VERSION ""

NS_ :

BS_:

BU_: TCM HCM IPMA_ADAS PSCM ABS_ESC TCCM TCM_DSL PCM_HEV PCM ECM_HEVDSL ECM_HEV ECM_Diesel ECM SIMA_DLCS BCMD_IPDB VDM CMR_DSMC SOBDMC_HPCM CHCM GWM _delete AWD_DLCM GENERIC TSTR

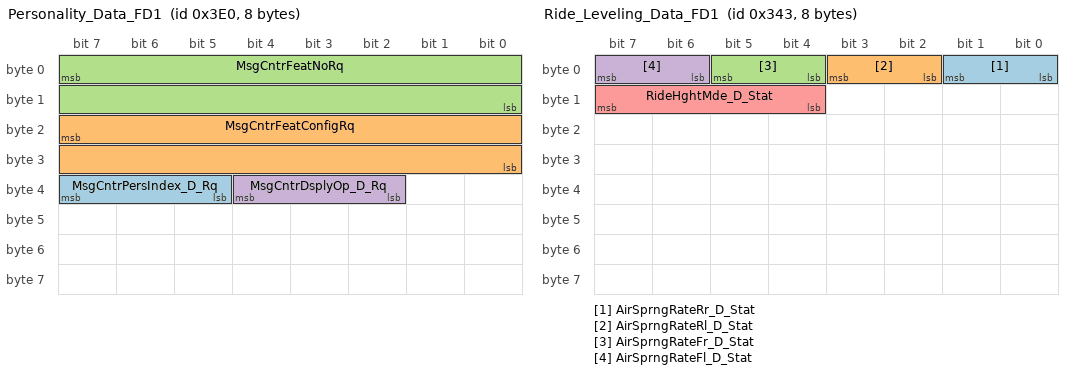
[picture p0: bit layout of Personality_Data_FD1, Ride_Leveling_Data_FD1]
BO_ 992 Personality_Data_FD1: 8 IPC
 SG_ MsgCntrPersIndex_D_Rq : 39|3@0+ (1,0) [0|7] "SED"  SOBDMC_HPCM,VDM,IPMA_ADAS,HCM
 SG_ MsgCntrFeatConfigRq : 23|16@0+ (1,0) [0|65535] "unitless"  SOBDMC_HPCM,HCM,VDM,IPMA_ADAS
 SG_ MsgCntrFeatNoRq : 7|16@0+ (1,0) [0|65535] "Number"  VDM,SOBDMC_HPCM,IPMA_ADAS,HCM
 SG_ MsgCntrDsplyOp_D_Rq : 36|3@0+ (1,0) [0|7] "SED"  SOBDMC_HPCM,HCM,VDM,IPMA_ADAS

BO_ 835 Ride_Leveling_Data_FD1: 8 SUMA_RLM
 SG_ AirSprngRateRr_D_Stat : 1|2@0+ (1,0) [0|3] "SED"  VDM,GENERIC
 SG_ AirSprngRateRl_D_Stat : 3|2@0+ (1,0) [0|3] "SED"  VDM,GENERIC
 SG_ AirSprngRateFr_D_Stat : 5|2@0+ (1,0) [0|3] "SED"  VDM,GENERIC
 SG_ AirSprngRateFl_D_Stat : 7|2@0+ (1,0) [0|3] "SED"  VDM,GENERIC
 SG_ RideHghtMde_D_Stat : 15|4@0+ (1,0) [0|15] "SED"  PSCM,GENERIC,VDM

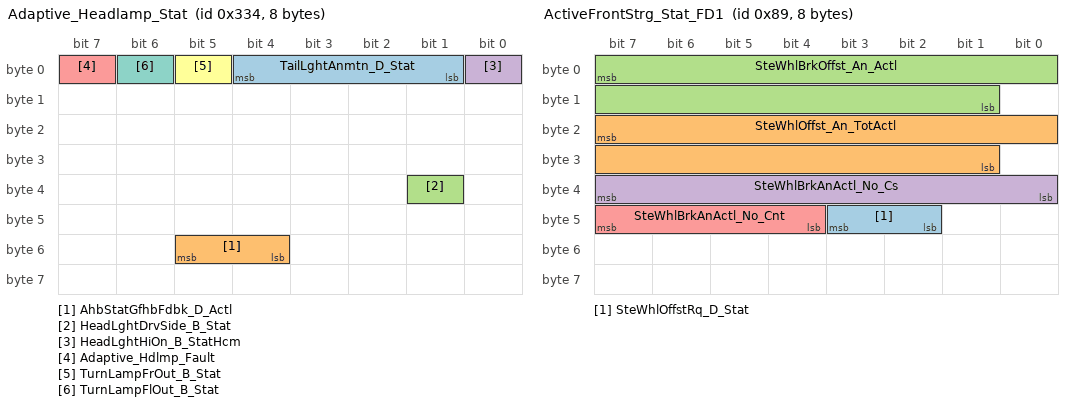
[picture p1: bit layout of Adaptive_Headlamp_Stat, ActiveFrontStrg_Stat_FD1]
BO_ 820 Adaptive_Headlamp_Stat: 8 GWM
 SG_ TailLghtAnmtn_D_Stat : 4|4@0+ (1,0) [0|15] "SED"  GWM
 SG_ AhbStatGfhbFdbk_D_Actl : 53|2@0+ (1,0) [0|3] "SED"  IPMA_ADAS
 SG_ HeadLghtDrvSide_B_Stat : 33|1@0+ (1,0) [0|1] "SED"  IPMA_ADAS
 SG_ HeadLghtHiOn_B_StatHcm : 0|1@0+ (1,0) [0|1] "SED"  GWM
 SG_ Adaptive_Hdlmp_Fault : 7|1@0+ (1,0) [0|1] "SED"  IPMA_ADAS,GWM
 SG_ TurnLampFrOut_B_Stat : 5|1@0+ (1,0) [0|1] "SED"  GWM
 SG_ TurnLampFlOut_B_Stat : 6|1@0+ (1,0) [0|1] "SED"  GWM

BO_ 817 Locking_Systems_2_FD1: 8 BCM
 SG_ ChildLckMde_B_Stat : 56|1@0+ (1,0) [0|1] "SED"  GENERIC
 SG_ VehLckInd_D_Rq : 58|2@0+ (1,0) [0|3] "SED"  GENERIC
 SG_ DrTgateOpen_B_Rq : 59|1@0+ (1,0) [0|1] "SED"  GENERIC
 SG_ DrTgateExtSwMde_B_Stat : 32|1@0+ (1,0) [0|1] "SED"  ECM,PCM
 SG_ Remote_Device_Feedback : 50|3@0+ (1,0) [0|7] "SED"  ECM,PCM
 SG_ Veh_Lock_Requestor : 55|5@0+ (1,0) [0|31] "SED"  ECM,PCM,ABS_ESC
 SG_ R_Pwr_Sliding_Dr_Rqst : 36|1@0+ (1,0) [0|1] "SED"  GENERIC
 SG_ Power_Liftgate_Rqst : 0|1@0+ (1,0) [0|1] "SED"  GENERIC
 SG_ Veh_Lock_EvNum : 47|8@0+ (1,0) [0|255] "unitless"  ECM,PCM,ABS_ESC
 SG_ Power_Decklid_Rqst : 1|1@0+ (1,0) [0|1] "SED"  GENERIC
 SG_ L_Pwr_Sliding_Dr_Rqst : 3|1@0+ (1,0) [0|1] "SED"  GENERIC
 SG_ Keyfob_Pad_Msg_Count : 15|8@0+ (1,0) [0|255] "Counts"  GENERIC
 SG_ Veh_Lock_Sub_Id : 63|4@0+ (1,0) [0|15] "SED"  ECM,PCM
 SG_ Veh_Lock_Status : 34|2@0+ (1,0) [0|3] "SED"  ECM,PCM,GENERIC,ABS_ESC,IPMA_ADAS,CMR_DSMC
 SG_ ChildLck_D_Dsply : 7|2@0+ (1,0) [0|3] "SED"  GENERIC
 SG_ WindowLockout_B_Stat : 35|1@0+ (1,0) [0|1] "SED"  GENERIC
 SG_ RollCodeUnlock : 23|16@0+ (1,0) [0|65535] "Unitless"  GENERIC
 SG_ Lockmsgtxt_D_Rq : 39|3@0+ (1,0) [0|7] "SED"  GENERIC
 SG_ FobComm_D_Stat : 5|2@0+ (1,0) [0|3] "SED"  ECM,PCM
 SG_ LockInhibit : 2|1@0+ (1,0) [0|1] "SED"  GENERIC

BO_ 137 ActiveFrontStrg_Stat_FD1: 8 GWM
 SG_ SteWhlOffstRq_D_Stat : 43|2@0+ (1,0) [0|3] "SED"  ABS_ESC
 SG_ SteWhlOffst_An_TotActl : 23|15@0+ (0.1,-1600) [-1600|1676.5] "degrees"  ABS_ESC
 SG_ SteWhlBrkOffst_An_Actl : 7|15@0+ (0.1,-1600) [-1600|1676.5] "degrees"  ABS_ESC,AWD_DLCM
 SG_ SteWhlBrkAnActl_No_Cs : 39|8@0+ (1,0) [0|255] "Unitless"  ABS_ESC
 SG_ SteWhlBrkAnActl_No_Cnt : 47|4@0+ (1,0) [0|15] "Unitless"  ABS_ESC

BO_ 129 Steering_Wheel_Data2_FD1: 8 SCCM
 SG_ SelDrvMdeSwtch4_D_Stat4 : 38|2@0+ (1,0) [0|3] "SED"  ABS_ESC
 SG_ EngExhMdeQuiet_B_RqDrv2 : 39|1@0+ (1,0) [0|1] "SED"  GENERIC
 SG_ SelDrvMdeSwtch_D_Stat4 : 21|2@0+ (1,0) [0|3] "SED"  ABS_ESC
 SG_ SteWhlSwtchView_B_Stat : 23|1@0+ (1,0) [0|1] "SED"  GENERIC
 SG_ SteWhlSwtchSet_B_Stat : 8|1@0+ (1,0) [0|1] "SED"  GENERIC
 SG_ SteWhlSwtchPhon_B_Stat : 9|1@0+ (1,0) [0|1] "SED"  GENERIC
 SG_ SteWhlSwtchNav_B_Stat : 10|1@0+ (1,0) [0|1] "SED"  GENERIC
 SG_ SteWhlSwtchMed_B_Stat : 11|1@0+ (1,0) [0|1] "SED"  GENERIC
 SG_ SteWhlSwtchIod_B_Stat : 12|1@0+ (1,0) [0|1] "SED"  GENERIC
 SG_ SteWhlSwtchHud_B_Stat : 13|1@0+ (1,0) [0|1] "SED"  GENERIC
 SG_ SteWhlSwtchBack_B_Stat : 14|1@0+ (1,0) [0|1] "SED"  GENERIC
 SG_ SteWhlSwtchMenu_B_Stat : 22|1@0+ (1,0) [0|1] "SED"  GENERIC
 SG_ SteEffortInc_B_RqDrv : 5|1@0+ (1,0) [0|1] "SED"  GENERIC
 SG_ SelDrvMdeInc_B_RqDrv : 6|1@0+ (1,0) [0|1] "SED"  GENERIC
 SG_ SelDrvMdeDec_B_RqDrv : 7|1@0+ (1,0) [0|1] "SED"  GENERIC
 SG_ SuspDampInc_B_RqDrv : 15|1@0+ (1,0) [0|1] "SED"  GENERIC
 SG_ SteWhlSwtchUp_B_Stat : 3|1@0+ (1,0) [0|1] "SED"  GENERIC
 SG_ SteWhlSwtchRght_B_Stat : 2|1@0+ (1,0) [0|1] "SED"  GENERIC
 SG_ SteWhlSwtchOk_B_Stat : 4|1@0+ (1,0) [0|1] "SED"  GENERIC
 SG_ SteWhlSwtchLeft_B_Stat : 1|1@0+ (1,0) [0|1] "SED"  GENERIC
 SG_ SteWhlSwtchDown_B_Stat : 0|1@0+ (1,0) [0|1] "SED"  GENERIC
 SG_ SteWhlSwtchHome_B_Stat : 19|1@0+ (1,0) [0|1] "SED"  GENERIC
 SG_ SteWhlSwtchInfo_B_Stat : 18|1@0+ (1,0) [0|1] "SED"  GENERIC
 SG_ PoliceAux4Swtch_B_Stat : 30|1@0+ (1,0) [0|1] "SED"  GENERIC
 SG_ PoliceAux3Swtch_B_Stat : 31|1@0+ (1,0) [0|1] "SED"  GENERIC
 SG_ PoliceAux2Swtch_B_Stat : 16|1@0+ (1,0) [0|1] "SED"  GENERIC
 SG_ PoliceAux1Swtch_B_Stat : 17|1@0+ (1,0) [0|1] "SED"  GENERIC
 SG_ SelDrvMdeSwtch3_D_Stat4 : 25|2@0+ (1,0) [0|3] "SED"  ABS_ESC
 SG_ SelDrvMdeSwtch2_D_Stat4 : 27|2@0+ (1,0) [0|3] "SED"  ABS_ESC
 SG_ SelDrvMdeSwtch1_D_Stat4 : 29|2@0+ (1,0) [0|3] "SED"  ABS_ESC

BO_ 854 Clmt_Button_Stat2_FD1: 8 HVAC_RCCM
 SG_ Dsp_RotAddrBtnEv_St : 63|4@0+ (1,0) [0|15] "SED"  GENERIC
 SG_ SelDrvMdeButtn_B_Stat : 55|1@0+ (1,0) [0|1] "SED"  GENERIC
 SG_ SteEffortButtn_B_Stat : 54|1@0+ (1,0) [0|1] "SED"  GENERIC
 SG_ SelDrvMdeSwtch_D_Stat2 : 51|2@0+ (1,0) [0|3] "SED"  GENERIC,ABS_ESC
 SG_ CC_Fr_Stat_User_Adj : 6|3@0+ (1,0) [0|7] "SED"  GENERIC
 SG_ EngExhMdeQuiet_B_RqDrv : 52|1@0+ (1,0) [0|1] "SED"  GENERIC
 SG_ LnchCtlSys_B_RqDrv : 53|1@0+ (1,0) [0|1] "SED"  GENERIC
 SG_ Front_Blower_Indicate : 13|4@0+ (1,0) [0|15] "SED"  GENERIC
 SG_ CC_Diagnostics_Active : 7|1@0+ (1,0) [0|1] "SED"  GENERIC
 SG_ RHS_Temp_Display_Digit3 : 3|2@0+ (1,0) [0|3] "SED"  GENERIC
 SG_ RHS_Temp_Display_Digit2 : 47|8@0+ (1,0) [0|255] "ASCII"  GENERIC
 SG_ RHS_Temp_Display_Digit1 : 39|8@0+ (1,0) [0|255] "ASCII"  GENERIC
 SG_ LHS_Temp_Display_Digit3 : 9|2@0+ (1,0) [0|3] "SED"  GENERIC
 SG_ LHS_Temp_Display_Digit2 : 31|8@0+ (1,0) [0|255] "ASCII"  GENERIC
 SG_ LHS_Temp_Display_Digit1 : 23|8@0+ (1,0) [0|255] "ASCII"  GENERIC
 SG_ EATC_RHS_Units : 15|2@0+ (1,0) [0|3] "SED"  GENERIC
 SG_ EATC_LHS_Units : 1|2@0+ (1,0) [0|3] "SED"  GENERIC
 SG_ LHS_Auto_Seat_Btn_Stt : 59|2@0+ (1,0) [0|3] "SED"  GENERIC
 SG_ RHS_Auto_Seat_Btn_Stt : 57|2@0+ (1,0) [0|3] "SED"  GENERIC

BO_ 549 IPC_Infotainment_FD1: 8 IPC
 SG_ SpeedChngChime_D_Rq2 : 13|2@0+ (1,0) [0|3] "SED"  IPMA_ADAS
 SG_ CCOI_PolicyClient_St2 : 45|4@0+ (1,0) [0|15] "SED"  GENERIC
 SG_ FactoryReset_Rq2 : 18|1@0+ (1,0) [0|1] "SED"  GENERIC
 SG_ TjaLcEnbl_D_DrvRq : 41|2@0+ (1,0) [0|3] "SED"  IPMA_ADAS
 SG_ BattTracLoThres_D_Rq2 : 52|3@0+ (1,0) [0|7] "SED"  SOBDMC_HPCM
 SG_ NavIod_D_Rq : 55|3@0+ (1,0) [0|7] "SED"  GENERIC
 SG_ Veh_V2_Dsply : 39|9@0+ (1,0) [0|511] "unitless"  GENERIC,IPMA_ADAS
 SG_ IPC_MyKeyVolLimit_St : 9|2@0+ (1,0) [0|3] "SED"  GENERIC
 SG_ HdcOn_B_Rq : 19|1@0+ (1,0) [0|1] "SED"  GENERIC,ABS_ESC
 SG_ IPC_Attn_Info_Audio : 4|3@0+ (1,0) [0|7] "SED"  GENERIC
 SG_ BeltminderAudioMute : 6|2@0+ (1,0) [0|3] "SED"  GENERIC
 SG_ Power_Up_Chime_Modules : 23|1@0+ (1,0) [0|1] "SED"  GENERIC
 SG_ Chime_Source : 15|2@0+ (1,0) [0|3] "SED"  GENERIC
 SG_ IPC_New_Attn_Event : 0|1@0+ (1,0) [0|1] "SED"  GENERIC
 SG_ WwaActv_B_Stat : 46|1@0+ (1,0) [0|1] "SED"  IPMA_ADAS
 SG_ MetricActv_B_Dsply : 7|1@0+ (1,0) [0|1] "SED"  GENERIC
 SG_ HudVertSzMnuOn_B_Rq : 21|1@0+ (1,0) [0|1] "SED"  GENERIC
 SG_ HudVertMnuOn_B_Rq : 11|1@0+ (1,0) [0|1] "SED"  GENERIC
 SG_ HudRotatMnuOn_B_Rq : 22|1@0+ (1,0) [0|1] "SED" Vector__XXX
 SG_ HudCntntMnuOn_B_Rq : 20|1@0+ (1,0) [0|1] "SED"  GENERIC
 SG_ HudBrightMnuOn_B_Rq : 1|1@0+ (1,0) [0|1] "SED"  GENERIC
 SG_ StrtInGearOk_D_Stat : 17|2@0+ (1,0) [0|3] "SED"  ECM_Diesel,ECM,PCM

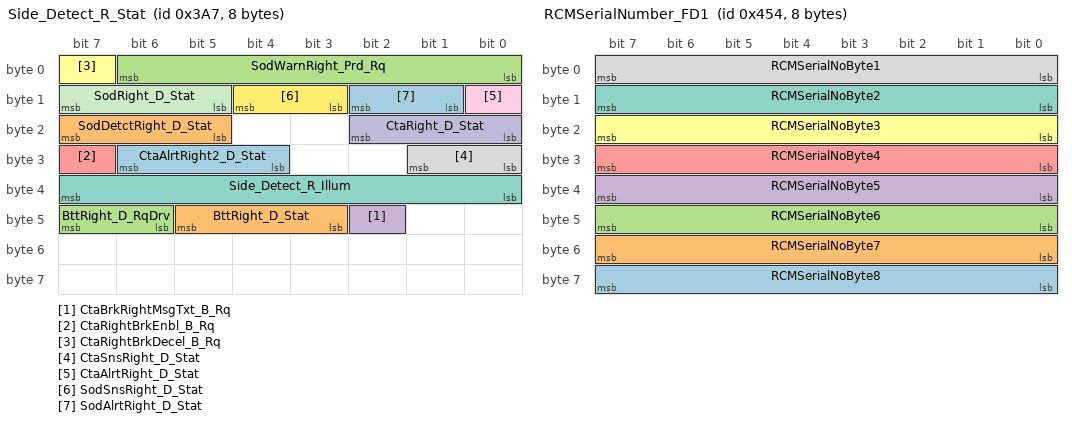
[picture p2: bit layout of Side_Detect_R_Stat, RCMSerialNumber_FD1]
BO_ 935 Side_Detect_R_Stat: 8 IPMA_ADAS
 SG_ CtaAlrtRight2_D_Stat : 30|3@0+ (1,0) [0|7] "SED"  GWM
 SG_ BttRight_D_Stat : 45|3@0+ (1,0) [0|7] "SED"  GWM
 SG_ BttRight_D_RqDrv : 47|2@0+ (1,0) [0|3] "SED"  GWM
 SG_ CtaBrkRightMsgTxt_B_Rq : 42|1@0+ (1,0) [0|1] "SED"  GWM
 SG_ CtaRightBrkEnbl_B_Rq : 31|1@0+ (1,0) [0|1] "SED"  GWM,ABS_ESC
 SG_ CtaRightBrkDecel_B_Rq : 7|1@0+ (1,0) [0|1] "SED"  GWM,ABS_ESC
 SG_ Side_Detect_R_Illum : 39|8@0+ (1,0) [0|255] "Percent"  GWM
 SG_ CtaSnsRight_D_Stat : 25|2@0+ (1,0) [0|3] "SED"  GWM
 SG_ CtaAlrtRight_D_Stat : 8|1@0+ (1,0) [0|1] "SED"  GWM
 SG_ CtaRight_D_Stat : 18|3@0+ (1,0) [0|7] "SED"  GWM
 SG_ SodRight_D_Stat : 15|3@0+ (1,0) [0|7] "SED"  GWM
 SG_ SodSnsRight_D_Stat : 12|2@0+ (1,0) [0|3] "SED"  GWM
 SG_ SodAlrtRight_D_Stat : 10|2@0+ (1,0) [0|3] "SED"  GWM
 SG_ SodDetctRight_D_Stat : 23|3@0+ (1,0) [0|7] "SED"  GWM
 SG_ SodWarnRight_Prd_Rq : 6|7@0+ (1,0) [0|127] "millisecond"  GWM

BO_ 1108 RCMSerialNumber_FD1: 8 RCM
 SG_ RCMSerialNoByte8 : 63|8@0+ (1,0) [0|253] "Unitless"  ABS_ESC
 SG_ RCMSerialNoByte7 : 55|8@0+ (1,0) [0|253] "Unitless"  ABS_ESC
 SG_ RCMSerialNoByte6 : 47|8@0+ (1,0) [0|253] "Unitless"  ABS_ESC
 SG_ RCMSerialNoByte5 : 39|8@0+ (1,0) [0|253] "Unitless"  ABS_ESC
 SG_ RCMSerialNoByte4 : 31|8@0+ (1,0) [0|253] "Unitless"  ABS_ESC
 SG_ RCMSerialNoByte3 : 23|8@0+ (1,0) [0|253] "Unitless"  ABS_ESC
 SG_ RCMSerialNoByte2 : 15|8@0+ (1,0) [0|253] "Unitless"  ABS_ESC
 SG_ RCMSerialNoByte1 : 7|8@0+ (1,0) [0|253] "Unitless"  ABS_ESC

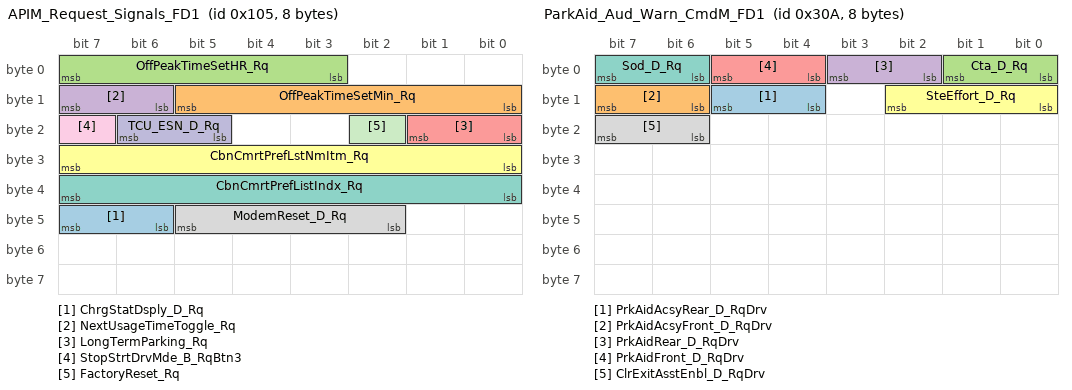
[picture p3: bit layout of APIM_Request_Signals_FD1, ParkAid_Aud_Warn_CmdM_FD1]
BO_ 261 APIM_Request_Signals_FD1: 8 ACM
 SG_ ChrgStatDsply_D_Rq : 47|2@0+ (1,0) [0|3] "SED"  GENERIC
 SG_ OffPeakTimeSetMin_Rq : 13|6@0+ (1,0) [0|63] "unitless"  GENERIC
 SG_ OffPeakTimeSetHR_Rq : 7|5@0+ (1,0) [0|31] "unitless"  GENERIC
 SG_ NextUsageTimeToggle_Rq : 15|2@0+ (1,0) [0|3] "SED"  GENERIC
 SG_ LongTermParking_Rq : 17|2@0+ (1,0) [0|3] "SED"  GENERIC
 SG_ CbnCmrtPrefLstNmItm_Rq : 31|8@0+ (1,0) [0|255] "unitless"  GENERIC
 SG_ CbnCmrtPrefListIndx_Rq : 39|8@0+ (1,0) [0|255] "unitless"  GENERIC
 SG_ ModemReset_D_Rq : 45|4@0+ (1,0) [0|15] "SED"  SOBDMC_HPCM
 SG_ StopStrtDrvMde_B_RqBtn3 : 23|1@0+ (1,0) [0|1] "SED"  ECM_HEVDSL,ECM_Diesel,ECM,PCM
 SG_ TCU_ESN_D_Rq : 22|2@0+ (1,0) [0|3] "SED"  GENERIC
 SG_ FactoryReset_Rq : 18|1@0+ (1,0) [0|1] "SED"  SOBDMC_HPCM

BO_ 1146 TrailerInfo_2_FD1: 8 TRM
 SG_ TrlrAidSwtch_D_RqDrv : 35|2@0+ (1,0) [0|3] "SED"  PSCM,IPMA_ADAS
 SG_ TrlrAidCtl_U_RqDrv : 31|12@0+ (0.00125,0) [0|5.11625] "volt"  PSCM

BO_ 533 APIM_Send_Signals_2_FD1: 8 APIM
 SG_ TjaLcEnbl_D_RqMnu : 57|2@0+ (1,0) [0|3] "SED"  IPMA_ADAS
 SG_ ExtLghtRvrseOn_B_Rq : 58|1@0+ (1,0) [0|1] "SED"  GENERIC
 SG_ ClrExitAsstEnbl_D_RqMnu : 60|2@0+ (1,0) [0|3] "SED"  IPMA_ADAS
 SG_ TrlrAidMde_D_Rq : 5|2@0+ (1,0) [0|3] "SED"  PSCM
 SG_ TCU_Init_Actvtn_St : 1|2@0+ (1,0) [0|3] "SED"  GENERIC
 SG_ TCU_Final_Actvtn_St : 3|2@0+ (1,0) [0|3] "SED"  GENERIC
 SG_ OtaTrg_D_Stat : 41|2@0+ (1,0) [0|3] "SED"  GENERIC
 SG_ OnbChrgGoTTouch_D_Rq : 43|2@0+ (1,0) [0|3] "SED"  SOBDMC_HPCM,GENERIC
 SG_ OnbChrgGoTPrcond_D_Rq : 34|2@0+ (1,0) [0|3] "SED"  SOBDMC_HPCM,GENERIC
 SG_ OnbChrgGoTOn_D_Rq : 25|2@0+ (1,0) [0|3] "SED"  SOBDMC_HPCM,GENERIC
 SG_ OnbChrgGoTMnte_D_Rq : 47|4@0+ (1,0) [0|15] "minute"  SOBDMC_HPCM,GENERIC
 SG_ OnbChrgGoTHr_T_Rq : 39|5@0+ (1,0) [0|29] "hour"  SOBDMC_HPCM,GENERIC
 SG_ OnbChrgGoTExtHtr_D_Rq : 27|2@0+ (1,0) [0|3] "SED"  SOBDMC_HPCM,GENERIC
 SG_ OnbChrgGoTElement_D_Rq : 31|4@0+ (1,0) [0|15] "Unitless"  SOBDMC_HPCM,GENERIC
 SG_ OnbChrgGoTDelete_B_Rq : 17|1@0+ (1,0) [0|1] "SED"  SOBDMC_HPCM,GENERIC
 SG_ OnbChrgClearAll_B_Rq : 18|1@0+ (1,0) [0|1] "SED"  SOBDMC_HPCM,GENERIC
 SG_ PaakMyKey_D_Rq : 7|2@0+ (1,0) [0|3] "SED"  GENERIC
 SG_ AutoEpbZoomView_B_Stat : 32|1@0+ (1,0) [0|1] "SED"  ABS_ESC
 SG_ AutoEpbButtn_B_Stat : 19|1@0+ (1,0) [0|1] "SED"  ABS_ESC
 SG_ DcacPw_D_Rq : 62|2@0+ (1,0) [0|3] "SED"  PCM_HEV,ECM_HEV,PCM
 SG_ DcacPwReset_B_Rq : 63|1@0+ (1,0) [0|1] "SED"  PCM_HEV,ECM_HEV,PCM,ECM_HEVDSL,ECM_Diesel
 SG_ LghtAmbDrvMde_D_Rq : 49|2@0+ (1,0) [0|3] "SED"  GENERIC
 SG_ DcacPwLoButtn_B_Stat : 13|1@0+ (1,0) [0|1] "SED"  ECM,ECM_HEV,ECM_HEVDSL,ECM_Diesel,PCM,PCM_HEV
 SG_ DcacPwOffButtn_B_Stat : 12|1@0+ (1,0) [0|1] "SED"  ECM,ECM_HEV,ECM_HEVDSL,ECM_Diesel,PCM,PCM_HEV
 SG_ DcacPwHiButtn_B_Stat : 14|1@0+ (1,0) [0|1] "SED"  PCM,ECM,ECM_HEV,ECM_HEVDSL,ECM_Diesel,PCM_HEV
 SG_ DcacPwResetButtn_B_Stat : 11|1@0+ (1,0) [0|1] "SED"  PCM,PCM_HEV,ECM,ECM_HEV
 SG_ DcacPwButtn_B_Falt : 15|1@0+ (1,0) [0|1] "SED"  PCM,PCM_HEV,ECM,ECM_HEV,ECM_HEVDSL,ECM_Diesel
 SG_ OnbChrgGoTUpdate_B_Rq : 16|1@0+ (1,0) [0|1] "SED"  SOBDMC_HPCM,GENERIC
 SG_ TrlrAlarmButtn_B_Stat : 50|1@0+ (1,0) [0|1] "SED"  GENERIC
 SG_ DcacMdeButtn_B_Stat : 8|1@0+ (1,0) [0|1] "SED"  ECM,ECM_HEV,PCM,PCM_HEV,ECM_HEVDSL,ECM_Diesel
 SG_ DcacGfciTestBttn_B_Stat : 9|1@0+ (1,0) [0|1] "SED"  ECM,ECM_HEV,PCM_HEV,PCM,ECM_HEVDSL,ECM_Diesel
 SG_ TrlrHitch_D_RqMnu : 23|4@0+ (1,0) [0|15] "SED"  IPMA_ADAS
 SG_ TrlrBrkGain_No_Rq : 55|5@0+ (0.5,0) [0|15.5] "unitless"  GENERIC
 SG_ DcacPwButtn_B_Stat : 10|1@0+ (1,0) [0|1] "SED"  ECM,ECM_HEV,ECM_HEVDSL,ECM_Diesel,PCM_HEV,PCM

BO_ 778 ParkAid_Aud_Warn_CmdM_FD1: 8 GWM
 SG_ PrkAidAcsyRear_D_RqDrv : 13|2@0+ (1,0) [0|3] "SED"  IPMA_ADAS
 SG_ PrkAidAcsyFront_D_RqDrv : 15|2@0+ (1,0) [0|3] "SED"  IPMA_ADAS
 SG_ Cta_D_Rq : 1|2@0+ (1,0) [0|3] "SED"  IPMA_ADAS
 SG_ PrkAidRear_D_RqDrv : 3|2@0+ (1,0) [0|3] "SED"  IPMA_ADAS
 SG_ PrkAidFront_D_RqDrv : 5|2@0+ (1,0) [0|3] "SED"  IPMA_ADAS
 SG_ SteEffort_D_Rq : 10|3@0+ (1,0) [0|7] "SED"  PSCM
 SG_ Sod_D_Rq : 7|2@0+ (1,0) [0|3] "SED"  IPMA_ADAS
 SG_ ClrExitAsstEnbl_D_RqDrv : 23|2@0+ (1,0) [0|3] "SED"  IPMA_ADAS

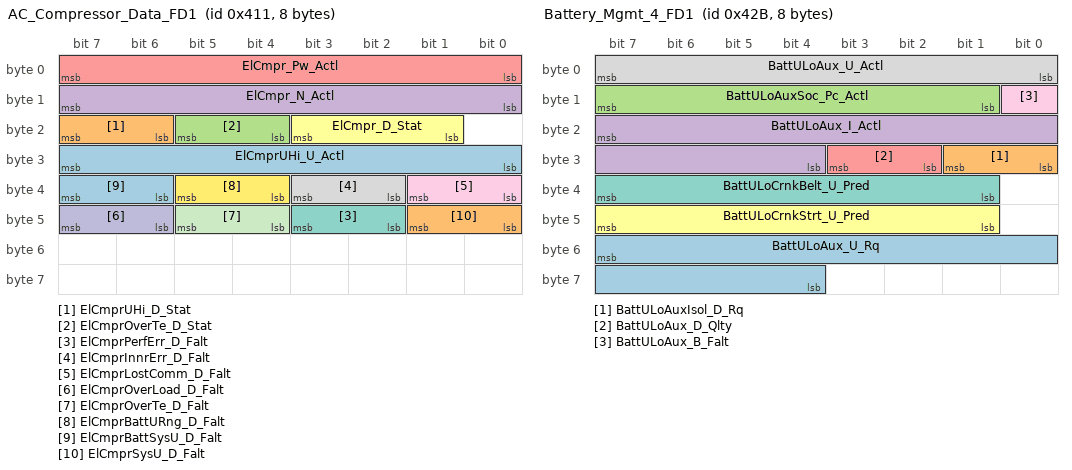
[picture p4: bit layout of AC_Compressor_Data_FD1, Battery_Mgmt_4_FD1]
BO_ 1041 AC_Compressor_Data_FD1: 8 ACCM
 SG_ ElCmprUHi_U_Actl : 31|8@0+ (2,0) [0|510] "volt"  SOBDMC_HPCM,GENERIC
 SG_ ElCmprUHi_D_Stat : 23|2@0+ (1,0) [0|3] "SED"  SOBDMC_HPCM,GENERIC
 SG_ ElCmprOverTe_D_Stat : 21|2@0+ (1,0) [0|3] "SED"  SOBDMC_HPCM,GENERIC
 SG_ ElCmpr_N_Actl : 15|8@0+ (50,0) [0|12700] "RPM"  SOBDMC_HPCM,GENERIC
 SG_ ElCmpr_Pw_Actl : 7|8@0+ (40,0) [0|10160] "watts"  SOBDMC_HPCM,PCM_HEV
 SG_ ElCmpr_D_Stat : 19|3@0+ (1,0) [0|7] "SED"  SOBDMC_HPCM,GENERIC
 SG_ ElCmprPerfErr_D_Falt : 43|2@0+ (1,0) [0|3] "SED"  GENERIC,SOBDMC_HPCM
 SG_ ElCmprInnrErr_D_Falt : 35|2@0+ (1,0) [0|3] "SED"  GENERIC,SOBDMC_HPCM
 SG_ ElCmprLostComm_D_Falt : 33|2@0+ (1,0) [0|3] "SED"  GENERIC,SOBDMC_HPCM
 SG_ ElCmprOverLoad_D_Falt : 47|2@0+ (1,0) [0|3] "SED"  GENERIC,SOBDMC_HPCM
 SG_ ElCmprOverTe_D_Falt : 45|2@0+ (1,0) [0|3] "SED"  GENERIC,SOBDMC_HPCM
 SG_ ElCmprBattURng_D_Falt : 37|2@0+ (1,0) [0|3] "SED"  GENERIC,SOBDMC_HPCM
 SG_ ElCmprBattSysU_D_Falt : 39|2@0+ (1,0) [0|3] "SED"  GENERIC,SOBDMC_HPCM
 SG_ ElCmprSysU_D_Falt : 41|2@0+ (1,0) [0|3] "SED"  GENERIC,SOBDMC_HPCM

BO_ 1067 Battery_Mgmt_4_FD1: 8 BCM
 SG_ BattULoAux_U_Rq : 55|12@0+ (0.00390625,0) [0|15.9921875] "volt"  ECM_HEV,PCM_HEV
 SG_ BattULoAuxIsol_D_Rq : 25|2@0+ (1,0) [0|3] "SED"  ECM_HEV,PCM_HEV
 SG_ BattULoAuxSoc_Pc_Actl : 15|7@0+ (1,0) [0|127] "percent"  PCM_HEV,ECM_HEV
 SG_ BattULoAux_I_Actl : 23|12@0+ (0.0625,-128) [-128|127.875] "ampere"  PCM_HEV,ECM_HEV
 SG_ BattULoAux_D_Qlty : 27|2@0+ (1,0) [0|3] "SED"  PCM_HEV,ECM_HEV
 SG_ BattULoCrnkStrt_U_Pred : 47|7@0+ (0.1,0) [0|12.7] "volt"  PCM_HEV,ECM_HEV
 SG_ BattULoCrnkBelt_U_Pred : 39|7@0+ (0.1,0) [0|12.7] "volt"  PCM_HEV,ECM_HEV
 SG_ BattULoAux_U_Actl : 7|8@0+ (0.0625,0) [0|15.875] "volt"  PCM_HEV,ECM_HEV
 SG_ BattULoAux_B_Falt : 8|1@0+ (1,0) [0|1] "SED"  PCM_HEV,ECM_HEV

BO_ 1118 BatteryCharge_Data2_FD1: 8 SOBDM_BCCM
 SG_ BptTgl_B_Complt : 29|1@0+ (1,0) [0|1] "SED"  SOBDMC_HPCM
 SG_ AcChrgRdy_B_Stat : 51|1@0+ (1,0) [0|1] "SED"  GENERIC
 SG_ DgtlCommGtwyMde_D_Rq : 48|4@0+ (1,0) [0|15] "SED"  GENERIC
 SG_ ExtChrgNowButtn_B_Rq : 49|1@0+ (1,0) [0|1] "SED"  SOBDMC_HPCM,GENERIC
 SG_ CoolFanChrgr_D_Rq : 45|2@0+ (1,0) [0|3] "SED"  SOBDMC_HPCM,GENERIC
 SG_ ChrgrClntFlw_D_Rq : 31|2@0+ (1,0) [0|3] "SED"  SOBDMC_HPCM,GENERIC
 SG_ PlgStatEvnt_B_Stat : 46|1@0+ (1,0) [0|1] "SED"  SOBDMC_HPCM,ECM_HEV,PCM_HEV
 SG_ ChrgrCnnctPwr_B_Stat : 47|1@0+ (1,0) [0|1] "SED"  SOBDMC_HPCM,GENERIC
 SG_ ChrgrAvailEvnt_B_Stat : 32|1@0+ (1,0) [0|1] "SED"  SOBDMC_HPCM,ECM_HEV,PCM_HEV
 SG_ ChrgrSrvcRqd_B_Rq : 0|1@0+ (1,0) [0|1] "SED"  GENERIC
 SG_ ChrgrS2Swtch_B_Stat : 42|1@0+ (1,0) [0|1] "SED"  GENERIC
 SG_ ChrgChngEvnt_B_Stat : 33|1@0+ (1,0) [0|1] "SED"  SOBDMC_HPCM,ECM_HEV,PCM_HEV
 SG_ ChrgCordLck_D_Stat : 7|3@0+ (1,0) [0|7] "SED"  SOBDMC_HPCM,PCM_HEV
 SG_ ChrgrInPwMde_D_Actl : 4|4@0+ (1,0) [0|15] "SED"  ECM_HEV,SOBDMC_HPCM,PCM_HEV
 SG_ ChrgPortDrOpen_B_Stat : 43|1@0+ (1,0) [0|1] "SED"  GENERIC
 SG_ ChrgCordChlng2_No_Actl : 23|8@0+ (1,0) [0|255] "unitless"  GENERIC
 SG_ ChrgCordChlng1_No_Actl : 15|8@0+ (1,0) [0|255] "unitless"  GENERIC
 SG_ ChrgrDcOvrVolt_B_Falt : 50|1@0+ (1,0) [0|1] "SED"  GENERIC
 SG_ ChrgrDcOvrCurnt_B_Falt : 56|1@0+ (1,0) [0|1] "SED"  GENERIC
 SG_ ChrgrPncEnbl_D_Stat : 58|2@0+ (1,0) [0|3] "SED"  GENERIC
 SG_ ChrgrCc2Cnnct_B_Falt : 59|1@0+ (1,0) [0|1] "SED"  GENERIC
 SG_ ChrgPortDcTeMx_B_Falt : 60|1@0+ (1,0) [0|1] "SED"  GENERIC
 SG_ ChrgCrdLck_D_Falt : 41|2@0+ (1,0) [0|3] "SED"  GENERIC

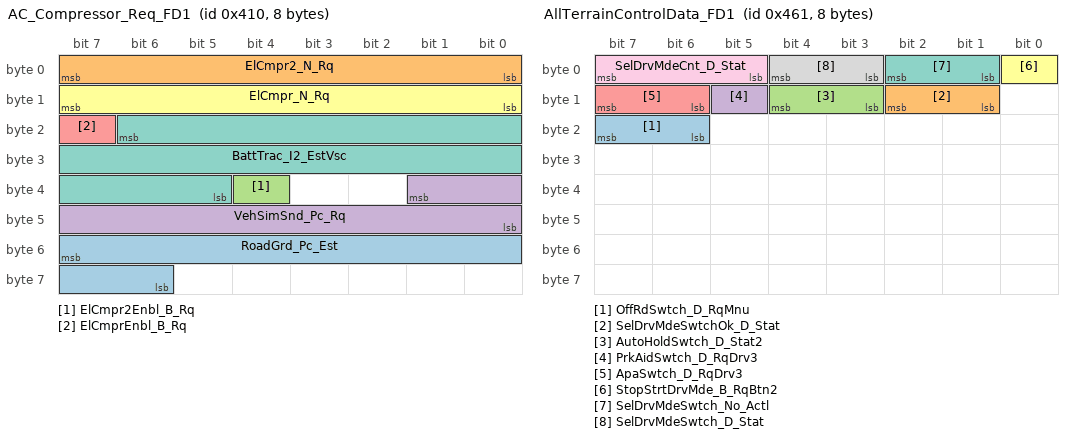
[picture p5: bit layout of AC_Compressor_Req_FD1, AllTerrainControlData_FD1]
BO_ 1040 AC_Compressor_Req_FD1: 8 SOBDMC_HPCM
 SG_ RoadGrd_Pc_Est : 55|10@0+ (0.2,-102) [-102|102.4] "percent"  GWM
 SG_ ElCmpr2_N_Rq : 7|8@0+ (50,0) [0|12750] "RPM"  GWM
 SG_ ElCmpr2Enbl_B_Rq : 36|1@0+ (1,0) [0|1] "SED"  GWM,ECM_HEV
 SG_ VehSimSnd_Pc_Rq : 33|10@0+ (0.2,-102.2) [-102.2|102.4] "percent"  GWM
 SG_ ElCmprEnbl_B_Rq : 23|1@0+ (1,0) [0|1] "SED"  GWM,PCM_HEV,ECM_HEV
 SG_ ElCmpr_N_Rq : 15|8@0+ (50,0) [0|12750] "RPM"  GWM,GENERIC
 SG_ BattTrac_I2_EstVsc : 22|18@0+ (0.05,-6553.52) [-6553.52|6553.53] "ampere"  GWM

BO_ 1144 MHT_EV_Wakeup_FD1: 8 SOBDMC_HPCM
 SG_ AwdLckMde_D_Stat : 59|3@0+ (1,0) [0|7] "SED"  ABS_ESC,GWM
 SG_ BattTracCool_B_Actl : 60|1@0+ (1,0) [0|1] "SED"  GWM
 SG_ BattChrgTrgtSoC_D_Rq : 35|3@0+ (1,0) [0|7] "Percent"  GWM,GENERIC
 SG_ CabnEvapSovFront_B_Rq : 38|1@0+ (1,0) [0|1] "SED"  GWM,BCMD_IPDB
 SG_ HeatCoreSovRear_B_Rq : 36|1@0+ (1,0) [0|1] "SED"  GWM,GENERIC
 SG_ BattChlrSov_B_Rq : 39|1@0+ (1,0) [0|1] "SED"  GWM,BCMD_IPDB
 SG_ CabnEvapSovRear_B_Rq : 37|1@0+ (1,0) [0|1] "SED"  GWM,GENERIC
 SG_ BrkAppl_D_RqPt : 25|2@0+ (1,0) [0|3] "SED"  GWM,ABS_ESC
 SG_ BattClntVlvOvrrd_D_Rq : 31|2@0+ (1,0) [0|3] "SED"  GWM,GENERIC
 SG_ BattTracChillerOn_B_Rq : 27|1@0+ (1,0) [0|1] "SED"  GWM,GENERIC
 SG_ BattTracChiller_D_Stat : 29|2@0+ (1,0) [0|3] "SED"  GWM,GENERIC
 SG_ HtrnDcdcDis_B_Rq : 26|1@0+ (1,0) [0|1] "SED"  GWM,ECM_HEV,ECM_HEVDSL,PCM_HEV
 SG_ HtrnCnnctPwr_B_Stat : 16|1@0+ (1,0) [0|1] "SED"  GWM,GENERIC
 SG_ PtcHtr_D_Stat : 18|2@0+ (1,0) [0|3] "SED"  GWM,PCM_HEV,ECM_HEV
 SG_ WakeAlarm0_B_Typ : 21|1@0+ (1,0) [0|1] "SED"  GWM,GENERIC
 SG_ WakeAlarm0_T_Rq : 7|15@0+ (1,0) [0|32767] "minute"  GWM,GENERIC
 SG_ HtrnClntFlw_D_Rq : 20|2@0+ (1,0) [0|3] "SED"  GWM,GENERIC
 SG_ BattTracDrvSustn_B_Rq : 8|1@0+ (1,0) [0|1] "SED"  GWM,PCM_HEV,ECM_HEV
 SG_ CabinDrvSustn_B_Rq : 23|1@0+ (1,0) [0|1] "SED"  GWM,PCM_HEV,ECM_HEV
 SG_ ChrgNowEvnt_B_Stat : 22|1@0+ (1,0) [0|1] "SED"  GWM,PCM_HEV,ECM_HEV
 SG_ PreCondBatt_B_Actl : 32|1@0+ (1,0) [0|1] "SED"  GWM,ECM_HEV,PCM_HEV
 SG_ BattTracClntVlv_B_Rq : 47|1@0+ (1,0) [0|1] "SED"  GWM,BCMD_IPDB
 SG_ FstChrgCmplt_T_Est : 41|10@0+ (1,0) [0|1023] "minute"  GWM
 SG_ ULoBattTrnsfrSustn_B_Rq : 43|1@0+ (1,0) [0|1] "SED"  ECM_HEV,PCM_HEV,GWM
 SG_ ULoBattTransfer_D_Stat : 46|3@0+ (1,0) [0|7] "SED"  ECM_HEV,PCM_HEV,GWM
 SG_ BattChrgInhbt_D2_Rq : 63|3@0+ (1,0) [0|7] "SED"  GWM
 SG_ BattTracClimtDis_B_Stat : 42|1@0+ (1,0) [0|1] "SED"  GWM

BO_ 1112 Battery_Traction_6_FD1: 8 BECM
 SG_ BattDcCnnct_D_Cmd : 14|3@0+ (1,0) [0|7] "SED"  SOBDMC_HPCM
 SG_ BattTrac2_E_Avail : 31|12@0+ (50,0) [0|204650] "watt*hour"  SOBDMC_HPCM,PCM_HEV
 SG_ BattTracCnnct_D_Cmd : 18|3@0+ (1,0) [0|7] "SED"  SOBDMC_HPCM,PCM_HEV,ECM_HEV,ECM_HEVDSL
 SG_ BattTracHvilOpen_B_Stat : 8|1@0+ (1,0) [0|1] "SED"  SOBDMC_HPCM,PCM_HEV
 SG_ BattTracCoolLvl_D_Rq : 11|3@0+ (1,0) [0|7] "SED"  SOBDMC_HPCM,GENERIC
 SG_ CoolFanBatt_D_Rq : 23|5@0+ (1,0) [0|31] "unitless"  PCM_HEV
 SG_ BattTracTeSustn_B_Rq : 1|1@0+ (1,0) [0|1] "SED"  SOBDMC_HPCM,PCM_HEV,ECM_HEV
 SG_ BattTracTeEvnt_B_Stat : 2|1@0+ (1,0) [0|1] "SED"  SOBDMC_HPCM,PCM_HEV,ECM_HEV
 SG_ BattTracDcdcDis_B_Rq : 7|1@0+ (1,0) [0|1] "SED"  ECM_HEV,ECM_HEVDSL,PCM_HEV
 SG_ BattChrgTrgtEvnt_B_Stat : 3|1@0+ (1,0) [0|1] "SED"  SOBDMC_HPCM,PCM_HEV,ECM_HEV
 SG_ BattTracChrgSustn_B_Rq : 4|1@0+ (1,0) [0|1] "SED"  SOBDMC_HPCM,PCM_HEV,ECM_HEV
 SG_ HtrnClntPump_D_Stat : 6|2@0+ (1,0) [0|3] "SED"  SOBDMC_HPCM,GENERIC
 SG_ BattTracIsoDis_B_Stat : 0|1@0+ (1,0) [0|1] "SED"  GENERIC
 SG_ BattTrac2_E_Max : 47|12@0+ (50,0) [0|204650] "watt*hour"  PCM_HEV,SOBDMC_HPCM
 SG_ BattTracHeat_D_Rq : 35|2@0+ (1,0) [0|3] "SED"  PCM_HEV,SOBDMC_HPCM
 SG_ BattTracDcFstSustn_B_Rq : 51|1@0+ (1,0) [0|1] "SED"  SOBDMC_HPCM
 SG_ BattTracDiagClr_B_Rq : 15|1@0+ (1,0) [0|1] "SED"  ECM_HEV,ECM_HEVDSL,PCM_HEV
 SG_ BattTracHazrd_D_Stat : 50|3@0+ (1,0) [0|7] "SED"  SOBDMC_HPCM
 SG_ BattTracDelta_Te_Actl : 63|8@0+ (0.5,-60) [-60|66.5] "degC"  SOBDMC_HPCM,GENERIC
 SG_ BattTracClntPmp_D_Stat : 33|2@0+ (1,0) [0|3] "SED"  SOBDMC_HPCM,GENERIC

BO_ 139 CruiseCtrl_Strg_Data_FD1: 8 GWM
 SG_ AccButtnGpTogglePress2 : 25|1@0+ (1,0) [0|1] "SED"  GENERIC
 SG_ TjaButtnOnOffPress2 : 26|1@0+ (1,0) [0|1] "SED"  GENERIC
 SG_ ActvFrontSteMsgTxt_D_Rq : 31|3@0+ (1,0) [0|7] "SED"  GENERIC
 SG_ ActvFrontSteLck_D_Stat : 17|2@0+ (1,0) [0|3] "SED"  ECM,ECM_Diesel,ECM_HEVDSL,PCM,PCM_HEV
 SG_ SelDrvMdeAdptSte_D_Stat : 28|2@0+ (1,0) [0|3] "SED"  ABS_ESC
 SG_ AslButtnOnOffPress2 : 4|1@0+ (1,0) [0|1] "SED"  GENERIC
 SG_ AslButtnOnOffCnclPres2 : 5|1@0+ (1,0) [0|1] "SED"  GENERIC
 SG_ CcButtnOnPress2 : 18|1@0+ (1,0) [0|1] "SED"  GENERIC
 SG_ CcButtnOnOffPress2 : 19|1@0+ (1,0) [0|1] "SED"  GENERIC
 SG_ CcButtnOnOffCnclPress2 : 20|1@0+ (1,0) [0|1] "SED"  GENERIC
 SG_ CcButtnOffPress2 : 21|1@0+ (1,0) [0|1] "SED"  GENERIC
 SG_ CcAsllButtnResPress2 : 22|1@0+ (1,0) [0|1] "SED"  GENERIC
 SG_ CcAslButtnSetPress2 : 23|1@0+ (1,0) [0|1] "SED"  GENERIC
 SG_ CcAslButtnSetIncPress2 : 8|1@0+ (1,0) [0|1] "SED"  GENERIC
 SG_ CcAslButtnSetDecPress2 : 9|1@0+ (1,0) [0|1] "SED"  GENERIC
 SG_ CcAslButtnResIncPress2 : 10|1@0+ (1,0) [0|1] "SED"  GENERIC
 SG_ CcAslButtnResDecPress2 : 11|1@0+ (1,0) [0|1] "SED"  GENERIC
 SG_ CcAslButtnOnPress2 : 12|1@0+ (1,0) [0|1] "SED"  GENERIC
 SG_ CcAslButtnOnOffCncl2 : 13|1@0+ (1,0) [0|1] "SED"  GENERIC
 SG_ CcAslButtnOffCnclPres2 : 14|1@0+ (1,0) [0|1] "SED"  GENERIC
 SG_ CcAslButtnIndxIncPres2 : 15|1@0+ (1,0) [0|1] "SED"  GENERIC
 SG_ CcAslButtnIndxDecPres2 : 0|1@0+ (1,0) [0|1] "SED"  GENERIC
 SG_ CcAslButtnDeny_B_Actl2 : 1|1@0+ (1,0) [0|1] "SED"  GENERIC
 SG_ CcAslButtnCnclResPres2 : 2|1@0+ (1,0) [0|1] "SED"  GENERIC
 SG_ CcAslButtnCnclPress2 : 3|1@0+ (1,0) [0|1] "SED"  GENERIC
 SG_ AccButtnGapIncPress2 : 6|1@0+ (1,0) [0|1] "SED"  GENERIC
 SG_ AccButtnGapDecPress2 : 7|1@0+ (1,0) [0|1] "SED"  GENERIC
 SG_ AfsPw_B_Rq : 24|1@0+ (1,0) [0|1] "SED"  ECM_Diesel,PCM

BO_ 1121 AllTerrainControlData_FD1: 8 ATCM_DMSM
 SG_ OffRdSwtch_D_RqMnu : 23|2@0+ (1,0) [0|3] "SED"  GENERIC
 SG_ SelDrvMdeSwtchOk_D_Stat : 10|2@0+ (1,0) [0|3] "SED"  ABS_ESC
 SG_ AutoHoldSwtch_D_Stat2 : 12|2@0+ (1,0) [0|3] "SED"  ABS_ESC
 SG_ PrkAidSwtch_D_RqDrv3 : 13|1@0+ (1,0) [0|1] "SED"  IPMA_ADAS
 SG_ ApaSwtch_D_RqDrv3 : 15|2@0+ (1,0) [0|3] "SED"  GENERIC
 SG_ StopStrtDrvMde_B_RqBtn2 : 0|1@0+ (1,0) [0|1] "SED"  PCM,ECM,ECM_Diesel,ECM_HEVDSL
 SG_ SelDrvMdeSwtch_No_Actl : 2|2@0+ (1,0) [0|3] "unitless"  ABS_ESC
 SG_ SelDrvMdeSwtch_D_Stat : 4|2@0+ (1,0) [0|3] "SED"  ABS_ESC
 SG_ SelDrvMdeCnt_D_Stat : 7|3@0+ (1,0) [0|7] "Counts"  ABS_ESC

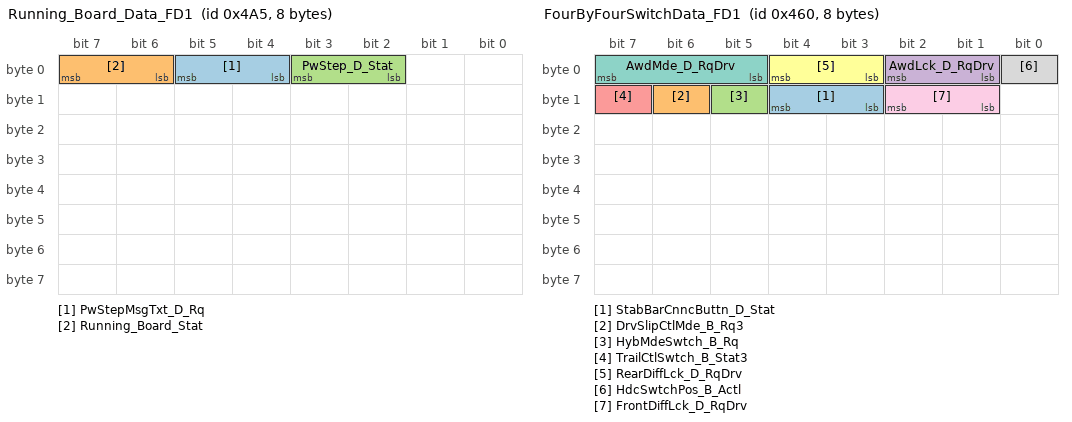
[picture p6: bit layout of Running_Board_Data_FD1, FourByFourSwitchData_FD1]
BO_ 1189 Running_Board_Data_FD1: 8 RBM
 SG_ PwStepMsgTxt_D_Rq : 5|2@0+ (1,0) [0|3] "SED"  GENERIC
 SG_ Running_Board_Stat : 7|2@0+ (1,0) [0|3] "SED"  GENERIC
 SG_ PwStep_D_Stat : 3|2@0+ (1,0) [0|3] "SED"  ECM,ECM_Diesel,ECM_HEVDSL

BO_ 1120 FourByFourSwitchData_FD1: 8 ATCM_DMSM
 SG_ StabBarCnncButtn_D_Stat : 12|2@0+ (1,0) [0|3] "SED"  CHCM
 SG_ DrvSlipCtlMde_B_Rq3 : 14|1@0+ (1,0) [0|1] "SED"  ABS_ESC
 SG_ HybMdeSwtch_B_Rq : 13|1@0+ (1,0) [0|1] "SED"  SOBDMC_HPCM,PCM_HEV
 SG_ AwdLck_D_RqDrv : 2|2@0+ (1,0) [0|3] "SED"  AWD_DLCM
 SG_ TrailCtlSwtch_B_Stat3 : 15|1@0+ (1,0) [0|1] "SED"  ABS_ESC
 SG_ RearDiffLck_D_RqDrv : 4|2@0+ (1,0) [0|3] "SED"  ECM,ECM_Diesel,ECM_HEVDSL,TCCM,PCM,AWD_DLCM
 SG_ AwdMde_D_RqDrv : 7|3@0+ (1,0) [0|7] "SED"  TCCM,AWD_DLCM
 SG_ HdcSwtchPos_B_Actl : 0|1@0+ (1,0) [0|1] "SED"  ABS_ESC
 SG_ FrontDiffLck_D_RqDrv : 10|2@0+ (1,0) [0|3] "SED"  AWD_DLCM

BO_ 1050 Climate_Control_Data_FD1: 8 HVAC_RCCM
 SG_ RearDiffLck_D_RqDrv4 : 55|2@0+ (1,0) [0|3] "SED"  AWD_DLCM
 SG_ CamraRearBttn_D_Stat : 35|1@0+ (1,0) [0|1] "SED"  GENERIC
 SG_ TrailCtlSwtch_B_Stat : 16|1@0+ (1,0) [0|1] "SED"  ABS_ESC
 SG_ AutoHoldSwtch_D_Stat : 20|2@0+ (1,0) [0|3] "SED"  ABS_ESC
 SG_ GlvBoxRleas_No_Actl : 23|3@0+ (1,0) [0|7] "unitless"  GENERIC
 SG_ EcoInhbt_B_RqHvac : 17|1@0+ (1,0) [0|1] "SED"  ECM,ECM_Diesel,ECM_HEV,ECM_HEVDSL,PCM,PCM_HEV
 SG_ LpdbPtc3_B_Rq : 36|1@0+ (1,0) [0|1] "SED"  GENERIC
 SG_ LpdbPtc2_B_Rq : 37|1@0+ (1,0) [0|1] "SED"  GENERIC
 SG_ LpdbPtc1_B_Rq : 38|1@0+ (1,0) [0|1] "SED"  GENERIC
 SG_ LpdbHeatWiprPrk_B_Rq : 39|1@0+ (1,0) [0|1] "SED"  GENERIC
 SG_ LpdbDfrstRearOn_B_Rq : 24|1@0+ (1,0) [0|1] "SED"  GENERIC,ECM_Diesel,ECM_HEVDSL
 SG_ LpdbDfrstFrOn_B_Rq : 25|1@0+ (1,0) [0|1] "SED"  GENERIC
 SG_ LpdbDfrstFlOn_B_Rq : 26|1@0+ (1,0) [0|1] "SED"  GENERIC
 SG_ LpdbAuxBlwr_B_Rq : 27|1@0+ (1,0) [0|1] "SED"  GENERIC
 SG_ PrkAidSwtch_No_Cnt : 31|4@0+ (1,0) [0|15] "Unitless"  GENERIC
 SG_ PrkAidSwtch_D_RqDrv : 18|1@0+ (1,0) [0|1] "SED"  GENERIC
 SG_ SteWhlHeat_D_Rq : 13|4@0+ (1,0) [0|15] "SED"  GENERIC
 SG_ MirrorHeatOn_B_Rq : 14|1@0+ (1,0) [0|1] "SED"  GENERIC
 SG_ Remote_Start_QuietMode : 15|1@0+ (1,0) [0|1] "SED"  GENERIC
 SG_ DrvSlipCtlMde_B_Rq : 9|1@0+ (1,0) [0|1] "SED"  ABS_ESC
 SG_ Outside_Air_Temp_Stat : 7|8@0+ (0.5,-40) [-40|86.5] "Degrees C"  ECM,ECM_Diesel,ECM_HEV,ECM_HEVDSL,IPMA_ADAS,PCM,PCM_HEV,PSCM,VDM
 SG_ CabnAmb_Te2_Actl : 47|8@0+ (0.5,-42) [-42|85] "degC"  PCM_HEV,PCM
 SG_ CamraFrntBttn_D_Stat : 8|1@0+ (1,0) [0|1] "SED"  IPMA_ADAS

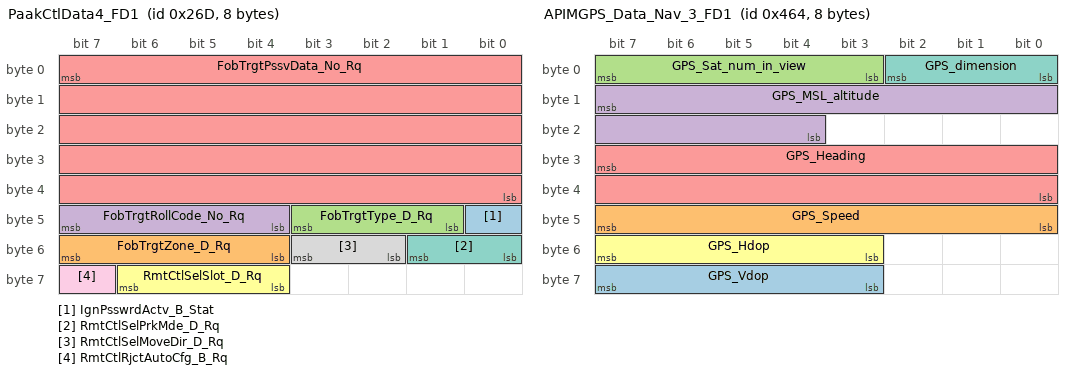
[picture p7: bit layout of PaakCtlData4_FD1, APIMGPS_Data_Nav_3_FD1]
BO_ 621 PaakCtlData4_FD1: 8 RFA_BLEM
 SG_ IgnPsswrdActv_B_Stat : 40|1@0+ (1,0) [0|1] "SED"  GENERIC
 SG_ FobTrgtZone_D_Rq : 55|4@0+ (1,0) [0|15] "SED"  GENERIC
 SG_ FobTrgtType_D_Rq : 43|3@0+ (1,0) [0|7] "SED"  GENERIC
 SG_ FobTrgtRollCode_No_Rq : 47|4@0+ (1,0) [0|15] "unitless"  GENERIC
 SG_ FobTrgtPssvData_No_Rq : 7|40@0+ (1,0) [0|1099511627775] "Encrypted"  GENERIC
 SG_ RmtCtlSelSlot_D_Rq : 62|3@0+ (1,0) [0|7] "SED"  IPMA_ADAS
 SG_ RmtCtlSelPrkMde_D_Rq : 49|2@0+ (1,0) [0|3] "SED"  IPMA_ADAS
 SG_ RmtCtlSelMoveDir_D_Rq : 51|2@0+ (1,0) [0|3] "SED"  IPMA_ADAS
 SG_ RmtCtlRjctAutoCfg_B_Rq : 63|1@0+ (1,0) [0|1] "SED"  IPMA_ADAS

BO_ 1124 APIMGPS_Data_Nav_3_FD1: 8 APIM
 SG_ GPS_Vdop : 63|5@0+ (0.2,0) [0|5.8] "unitless"  IPMA_ADAS,SOBDMC_HPCM,GENERIC
 SG_ GPS_Speed : 47|8@0+ (1,0) [0|253] "MPH"  SOBDMC_HPCM,GENERIC
 SG_ GPS_Sat_num_in_view : 7|5@0+ (1,0) [0|29] "unitless"  SOBDMC_HPCM,GENERIC
 SG_ GPS_MSL_altitude : 15|12@0+ (10,-20460) [-20460|20470] "feet"  SOBDMC_HPCM,GENERIC
 SG_ GPS_Heading : 31|16@0+ (0.01,0) [0|655.33] "Degrees"  SOBDMC_HPCM,IPMA_ADAS
 SG_ GPS_Hdop : 55|5@0+ (0.2,0) [0|5.8] "unitless"  IPMA_ADAS,SOBDMC_HPCM,GENERIC
 SG_ GPS_dimension : 2|3@0+ (1,0) [0|7] "SED"  SOBDMC_HPCM,GENERIC

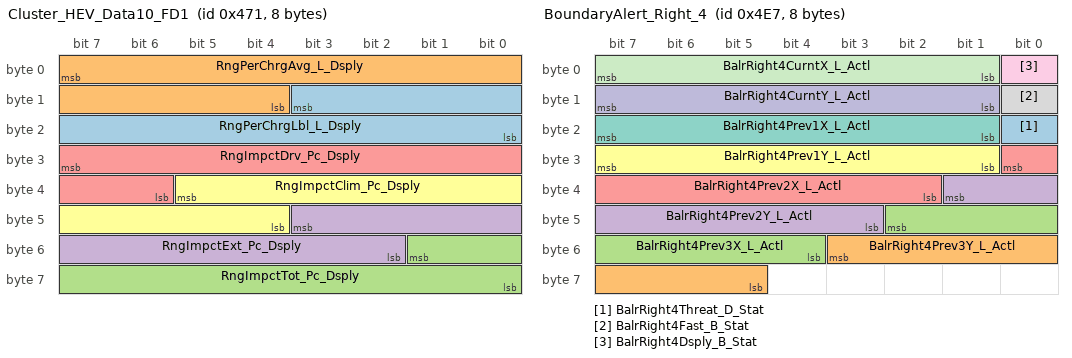
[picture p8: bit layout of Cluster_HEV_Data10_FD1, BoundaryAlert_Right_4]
BO_ 1137 Cluster_HEV_Data10_FD1: 8 PCM_HEV
 SG_ RngPerChrgLbl_L_Dsply : 11|12@0+ (0.1,0) [0|409.3] "km"  GWM
 SG_ RngPerChrgAvg_L_Dsply : 7|12@0+ (0.1,0) [0|409.3] "km"  GWM
 SG_ RngImpctTot_Pc_Dsply : 49|10@0+ (0.2,-102) [-102|102.4] "percent"  GWM
 SG_ RngImpctExt_Pc_Dsply : 43|10@0+ (0.2,-102) [-102|102.4] "percent"  GWM
 SG_ RngImpctDrv_Pc_Dsply : 31|10@0+ (0.2,-102) [-102|102.4] "percent"  GWM
 SG_ RngImpctClim_Pc_Dsply : 37|10@0+ (0.2,-102) [-102|102.4] "percent"  GWM

BO_ 1255 BoundaryAlert_Right_4: 8 IPMA_ADAS
 SG_ BalrRight4Threat_D_Stat : 16|1@0+ (1,0) [0|1] "SED"  GWM
 SG_ BalrRight4Prev3Y_L_Actl : 51|7@0+ (0.5,-32) [-32|31.5] "meter"  GWM
 SG_ BalrRight4Prev3X_L_Actl : 42|7@0+ (0.5,-32) [-32|31.5] "meter"  GWM
 SG_ BalrRight4Prev2Y_L_Actl : 33|7@0+ (0.5,-32) [-32|31.5] "meter"  GWM
 SG_ BalrRight4Prev2X_L_Actl : 24|7@0+ (0.5,-32) [-32|31.5] "meter"  GWM
 SG_ BalrRight4Prev1Y_L_Actl : 31|7@0+ (0.5,-32) [-32|31.5] "meter"  GWM
 SG_ BalrRight4Prev1X_L_Actl : 23|7@0+ (0.5,-32) [-32|31.5] "meter"  GWM
 SG_ BalrRight4Fast_B_Stat : 8|1@0+ (1,0) [0|1] "SED"  GWM
 SG_ BalrRight4Dsply_B_Stat : 0|1@0+ (1,0) [0|1] "SED"  GWM
 SG_ BalrRight4CurntY_L_Actl : 15|7@0+ (0.5,-32) [-32|31.5] "meter"  GWM
 SG_ BalrRight4CurntX_L_Actl : 7|7@0+ (0.5,-32) [-32|31.5] "meter"  GWM

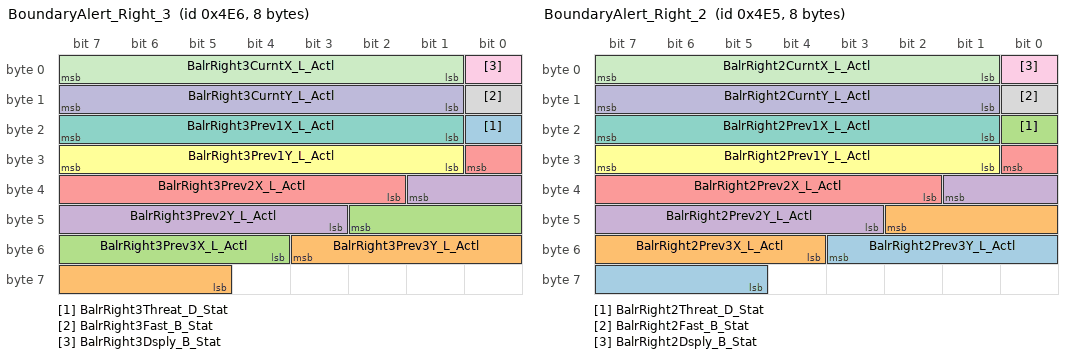
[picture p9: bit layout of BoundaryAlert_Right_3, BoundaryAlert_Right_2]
BO_ 1254 BoundaryAlert_Right_3: 8 IPMA_ADAS
 SG_ BalrRight3Threat_D_Stat : 16|1@0+ (1,0) [0|1] "SED"  GWM
 SG_ BalrRight3Prev3Y_L_Actl : 51|7@0+ (0.5,-32) [-32|31.5] "meter"  GWM
 SG_ BalrRight3Prev3X_L_Actl : 42|7@0+ (0.5,-32) [-32|31.5] "meter"  GWM
 SG_ BalrRight3Prev2Y_L_Actl : 33|7@0+ (0.5,-32) [-32|31.5] "meter"  GWM
 SG_ BalrRight3Prev2X_L_Actl : 24|7@0+ (0.5,-32) [-32|31.5] "meter"  GWM
 SG_ BalrRight3Prev1Y_L_Actl : 31|7@0+ (0.5,-32) [-32|31.5] "meter"  GWM
 SG_ BalrRight3Prev1X_L_Actl : 23|7@0+ (0.5,-32) [-32|31.5] "meter"  GWM
 SG_ BalrRight3Fast_B_Stat : 8|1@0+ (1,0) [0|1] "SED"  GWM
 SG_ BalrRight3Dsply_B_Stat : 0|1@0+ (1,0) [0|1] "SED"  GWM
 SG_ BalrRight3CurntY_L_Actl : 15|7@0+ (0.5,-32) [-32|31.5] "meter"  GWM
 SG_ BalrRight3CurntX_L_Actl : 7|7@0+ (0.5,-32) [-32|31.5] "meter"  GWM

BO_ 1253 BoundaryAlert_Right_2: 8 IPMA_ADAS
 SG_ BalrRight2Prev3Y_L_Actl : 51|7@0+ (0.5,-32) [-32|31.5] "meter"  GWM
 SG_ BalrRight2Prev3X_L_Actl : 42|7@0+ (0.5,-32) [-32|31.5] "meter"  GWM
 SG_ BalrRight2Threat_D_Stat : 16|1@0+ (1,0) [0|1] "SED"  GWM
 SG_ BalrRight2Prev2Y_L_Actl : 33|7@0+ (0.5,-32) [-32|31.5] "meter"  GWM
 SG_ BalrRight2Prev2X_L_Actl : 24|7@0+ (0.5,-32) [-32|31.5] "meter"  GWM
 SG_ BalrRight2Prev1Y_L_Actl : 31|7@0+ (0.5,-32) [-32|31.5] "meter"  GWM
 SG_ BalrRight2Prev1X_L_Actl : 23|7@0+ (0.5,-32) [-32|31.5] "meter"  GWM
 SG_ BalrRight2Fast_B_Stat : 8|1@0+ (1,0) [0|1] "SED"  GWM
 SG_ BalrRight2Dsply_B_Stat : 0|1@0+ (1,0) [0|1] "SED"  GWM
 SG_ BalrRight2CurntY_L_Actl : 15|7@0+ (0.5,-32) [-32|31.5] "meter"  GWM
 SG_ BalrRight2CurntX_L_Actl : 7|7@0+ (0.5,-32) [-32|31.5] "meter"  GWM

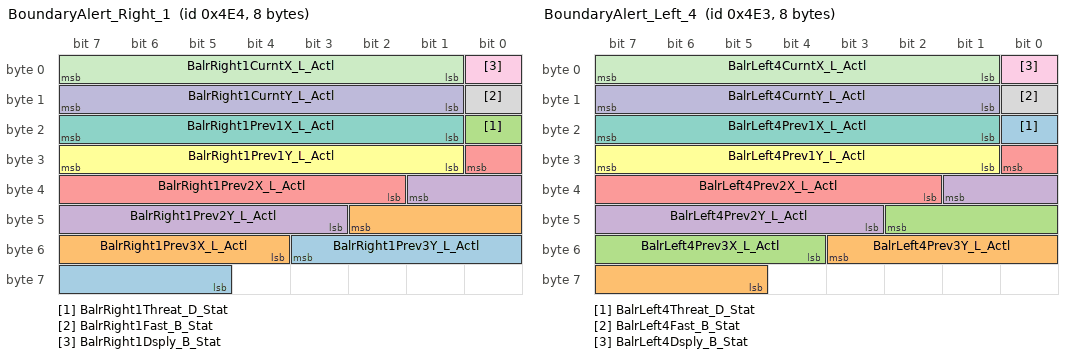
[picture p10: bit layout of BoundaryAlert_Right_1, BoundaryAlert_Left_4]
BO_ 1252 BoundaryAlert_Right_1: 8 IPMA_ADAS
 SG_ BalrRight1Prev3Y_L_Actl : 51|7@0+ (0.5,-32) [-32|31.5] "meter"  GWM
 SG_ BalrRight1Prev3X_L_Actl : 42|7@0+ (0.5,-32) [-32|31.5] "meter"  GWM
 SG_ BalrRight1Threat_D_Stat : 16|1@0+ (1,0) [0|1] "SED"  GWM
 SG_ BalrRight1Prev2Y_L_Actl : 33|7@0+ (0.5,-32) [-32|31.5] "meter"  GWM
 SG_ BalrRight1Prev2X_L_Actl : 24|7@0+ (0.5,-32) [-32|31.5] "meter"  GWM
 SG_ BalrRight1Prev1Y_L_Actl : 31|7@0+ (0.5,-32) [-32|31.5] "meter"  GWM
 SG_ BalrRight1Prev1X_L_Actl : 23|7@0+ (0.5,-32) [-32|31.5] "meter"  GWM
 SG_ BalrRight1Fast_B_Stat : 8|1@0+ (1,0) [0|1] "SED"  GWM
 SG_ BalrRight1Dsply_B_Stat : 0|1@0+ (1,0) [0|1] "SED"  GWM
 SG_ BalrRight1CurntY_L_Actl : 15|7@0+ (0.5,-32) [-32|31.5] "meter"  GWM
 SG_ BalrRight1CurntX_L_Actl : 7|7@0+ (0.5,-32) [-32|31.5] "meter"  GWM

BO_ 1251 BoundaryAlert_Left_4: 8 IPMA_ADAS
 SG_ BalrLeft4Threat_D_Stat : 16|1@0+ (1,0) [0|1] "SED"  GWM
 SG_ BalrLeft4Prev3Y_L_Actl : 51|7@0+ (0.5,-32) [-32|31.5] "meter"  GWM
 SG_ BalrLeft4Prev3X_L_Actl : 42|7@0+ (0.5,-32) [-32|31.5] "meter"  GWM
 SG_ BalrLeft4Prev2Y_L_Actl : 33|7@0+ (0.5,-32) [-32|31.5] "meter"  GWM
 SG_ BalrLeft4Prev2X_L_Actl : 24|7@0+ (0.5,-32) [-32|31.5] "meter"  GWM
 SG_ BalrLeft4Prev1Y_L_Actl : 31|7@0+ (0.5,-32) [-32|31.5] "meter"  GWM
 SG_ BalrLeft4Prev1X_L_Actl : 23|7@0+ (0.5,-32) [-32|31.5] "meter"  GWM
 SG_ BalrLeft4Fast_B_Stat : 8|1@0+ (1,0) [0|1] "SED"  GWM
 SG_ BalrLeft4Dsply_B_Stat : 0|1@0+ (1,0) [0|1] "SED"  GWM
 SG_ BalrLeft4CurntY_L_Actl : 15|7@0+ (0.5,-32) [-32|31.5] "meter"  GWM
 SG_ BalrLeft4CurntX_L_Actl : 7|7@0+ (0.5,-32) [-32|31.5] "meter"  GWM

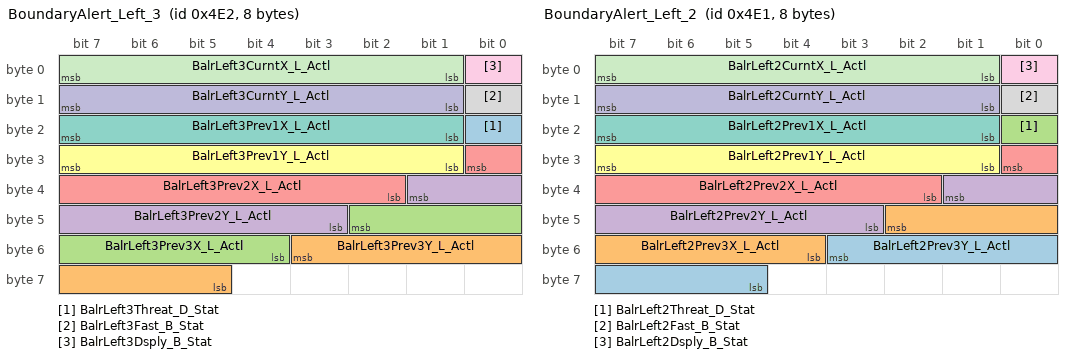
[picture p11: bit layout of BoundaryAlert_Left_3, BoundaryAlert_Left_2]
BO_ 1250 BoundaryAlert_Left_3: 8 IPMA_ADAS
 SG_ BalrLeft3Threat_D_Stat : 16|1@0+ (1,0) [0|1] "SED"  GWM
 SG_ BalrLeft3Prev3Y_L_Actl : 51|7@0+ (0.5,-32) [-32|31.5] "meter"  GWM
 SG_ BalrLeft3Prev3X_L_Actl : 42|7@0+ (0.5,-32) [-32|31.5] "meter"  GWM
 SG_ BalrLeft3Prev2Y_L_Actl : 33|7@0+ (0.5,-32) [-32|31.5] "meter"  GWM
 SG_ BalrLeft3Prev2X_L_Actl : 24|7@0+ (0.5,-32) [-32|31.5] "meter"  GWM
 SG_ BalrLeft3Prev1Y_L_Actl : 31|7@0+ (0.5,-32) [-32|31.5] "meter"  GWM
 SG_ BalrLeft3Prev1X_L_Actl : 23|7@0+ (0.5,-32) [-32|31.5] "meter"  GWM
 SG_ BalrLeft3Fast_B_Stat : 8|1@0+ (1,0) [0|1] "SED"  GWM
 SG_ BalrLeft3Dsply_B_Stat : 0|1@0+ (1,0) [0|1] "SED"  GWM
 SG_ BalrLeft3CurntY_L_Actl : 15|7@0+ (0.5,-32) [-32|31.5] "meter"  GWM
 SG_ BalrLeft3CurntX_L_Actl : 7|7@0+ (0.5,-32) [-32|31.5] "meter"  GWM

BO_ 1249 BoundaryAlert_Left_2: 8 IPMA_ADAS
 SG_ BalrLeft2Prev3Y_L_Actl : 51|7@0+ (0.5,-32) [-32|31.5] "meter"  GWM
 SG_ BalrLeft2Prev3X_L_Actl : 42|7@0+ (0.5,-32) [-32|31.5] "meter"  GWM
 SG_ BalrLeft2Threat_D_Stat : 16|1@0+ (1,0) [0|1] "SED"  GWM
 SG_ BalrLeft2Prev2Y_L_Actl : 33|7@0+ (0.5,-32) [-32|31.5] "meter"  GWM
 SG_ BalrLeft2Prev2X_L_Actl : 24|7@0+ (0.5,-32) [-32|31.5] "meter"  GWM
 SG_ BalrLeft2Prev1Y_L_Actl : 31|7@0+ (0.5,-32) [-32|31.5] "meter"  GWM
 SG_ BalrLeft2Prev1X_L_Actl : 23|7@0+ (0.5,-32) [-32|31.5] "meter"  GWM
 SG_ BalrLeft2Fast_B_Stat : 8|1@0+ (1,0) [0|1] "SED"  GWM
 SG_ BalrLeft2Dsply_B_Stat : 0|1@0+ (1,0) [0|1] "SED"  GWM
 SG_ BalrLeft2CurntY_L_Actl : 15|7@0+ (0.5,-32) [-32|31.5] "meter"  GWM
 SG_ BalrLeft2CurntX_L_Actl : 7|7@0+ (0.5,-32) [-32|31.5] "meter"  GWM

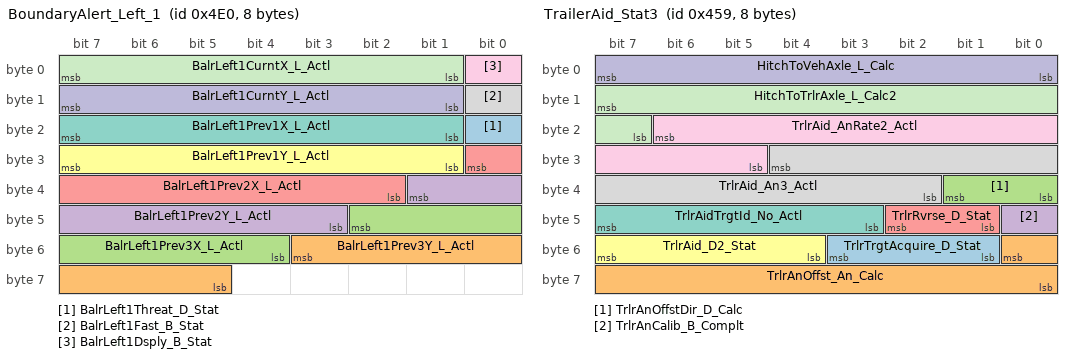
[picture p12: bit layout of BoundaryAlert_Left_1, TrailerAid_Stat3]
BO_ 1248 BoundaryAlert_Left_1: 8 IPMA_ADAS
 SG_ BalrLeft1Threat_D_Stat : 16|1@0+ (1,0) [0|1] "SED"  GWM
 SG_ BalrLeft1Prev3Y_L_Actl : 51|7@0+ (0.5,-32) [-32|31.5] "meter"  GWM
 SG_ BalrLeft1Prev3X_L_Actl : 42|7@0+ (0.5,-32) [-32|31.5] "meter"  GWM
 SG_ BalrLeft1Prev2Y_L_Actl : 33|7@0+ (0.5,-32) [-32|31.5] "meter"  GWM
 SG_ BalrLeft1Prev2X_L_Actl : 24|7@0+ (0.5,-32) [-32|31.5] "meter"  GWM
 SG_ BalrLeft1Prev1Y_L_Actl : 31|7@0+ (0.5,-32) [-32|31.5] "meter"  GWM
 SG_ BalrLeft1Prev1X_L_Actl : 23|7@0+ (0.5,-32) [-32|31.5] "meter"  GWM
 SG_ BalrLeft1Fast_B_Stat : 8|1@0+ (1,0) [0|1] "SED"  GWM
 SG_ BalrLeft1Dsply_B_Stat : 0|1@0+ (1,0) [0|1] "SED"  GWM
 SG_ BalrLeft1CurntY_L_Actl : 15|7@0+ (0.5,-32) [-32|31.5] "meter"  GWM
 SG_ BalrLeft1CurntX_L_Actl : 7|7@0+ (0.5,-32) [-32|31.5] "meter"  GWM

BO_ 2610988248 PARSEDPhysGWM_ECGtoIPMA: 64 GWM
 SG_ PARSEDPhysGWM_ECGtoIPMA : 7|29@0+ (1,0) [0|536870911] "unitless"  IPMA_ADAS

BO_ 1113 TrailerAid_Stat3: 8 IPMA_ADAS
 SG_ TrlrTrgtAcquire_D_Stat : 51|3@0+ (1,0) [0|7] "SED"  PSCM,GWM
 SG_ TrlrAnOffst_An_Calc : 48|9@0+ (0.1,0) [0|51.1] "degrees"  PSCM,GWM
 SG_ TrlrAnOffstDir_D_Calc : 33|2@0+ (1,0) [0|3] "SED"  PSCM,GWM
 SG_ TrlrAnCalib_B_Complt : 40|1@0+ (1,0) [0|1] "SED"  GWM
 SG_ TrlrRvrse_D_Stat : 42|2@0+ (1,0) [0|3] "SED"  PSCM
 SG_ TrlrAid_D2_Stat : 55|4@0+ (1,0) [0|15] "SED"  PSCM
 SG_ TrlrAidTrgtId_No_Actl : 47|5@0+ (1,0) [0|31] "unitless"  GWM,PSCM
 SG_ TrlrAid_An3_Actl : 28|11@0+ (0.125,-90) [-90|165.75] "degrees"  PSCM,GWM
 SG_ TrlrAid_AnRate2_Actl : 22|10@0+ (0.125,-50) [-50|77.75] "degrees/second"  PSCM,GWM
 SG_ HitchToVehAxle_L_Calc : 7|8@0+ (0.0127,-0.508) [-0.508|2.7178] "meter"  PSCM,GWM
 SG_ HitchToTrlrAxle_L_Calc2 : 15|9@0+ (0.0254,0) [0|12.9794] "meter"  GWM

BO_ 1105 Image_Processing_Data: 8 IPMA_ADAS
 SG_ SpeedChngChime_D_Stat : 41|2@0+ (1,0) [0|3] "SED"  GWM
 SG_ ClrExitAsstMsgTxt2_D_Rq : 55|4@0+ (1,0) [0|15] "SED"  GWM
 SG_ ClrExitAsstActv_B_Rq : 24|1@0+ (1,0) [0|1] "SED"  GWM
 SG_ TrlrRvrseMsgTxt_D2_Rq : 31|6@0+ (1,0) [0|63] "SED"  PSCM,GWM
 SG_ TrlrRvrseEnbl_D2_Stat : 18|3@0+ (1,0) [0|7] "SED"  PSCM,GWM
 SG_ RbaMsg_D_Rq : 22|2@0+ (1,0) [0|3] "SED"  GWM
 SG_ BrkDecel_B_RqRba : 8|1@0+ (1,0) [0|1] "SED"  ABS_ESC
 SG_ BrkEnbl_B_RqRba : 23|1@0+ (1,0) [0|1] "SED"  ABS_ESC
 SG_ Rba_D_Stat : 14|2@0+ (1,0) [0|3] "SED"  GWM
 SG_ RbaAlrt_D_Dsply : 12|2@0+ (1,0) [0|3] "SED"  GWM
 SG_ RbaMnu_D_Rq : 10|2@0+ (1,0) [0|3] "SED"  GWM
 SG_ CamraFrntStat_D_Stat : 7|2@0+ (1,0) [0|3] "SED"  GWM
 SG_ TrlrHitchLamp_D_Rq2 : 15|1@0+ (1,0) [0|1] "SED"  GWM
 SG_ CamraFrntOffRd_B_Stat : 25|1@0+ (1,0) [0|1] "SED"  GWM
 SG_ TrlrAidSwtchLamp_B_Rq : 32|1@0+ (1,0) [0|1] "SED"  GWM
 SG_ TrlrAidEnbl_D_RqAdas : 5|3@0+ (1,0) [0|7] "SED"  GWM,PSCM
 SG_ TrlrHitchMsgTxt_D_Rq : 47|6@0+ (1,0) [0|63] "SED"  GWM
 SG_ TrlrHitchIcon_D_Rq : 36|4@0+ (1,0) [0|15] "SED"  GWM
 SG_ TrlrHitchChime_D_Rq : 39|3@0+ (1,0) [0|7] "SED"  GWM

BO_ 938 ParkAid_Aud_Warn_Stat: 8 IPMA_ADAS
 SG_ SidePrkSnsR2_D_Stat : 59|4@0+ (1,0) [0|15] "SED"  GWM
 SG_ SidePrkSnsR1_D_Stat : 63|4@0+ (1,0) [0|15] "SED"  GWM
 SG_ SidePrkSnsL2_D_Stat : 51|4@0+ (1,0) [0|15] "SED"  GWM
 SG_ ApaMde_D_Stat : 23|3@0+ (1,0) [0|7] "SED"  GWM
 SG_ ApaActvSd_D_Actl : 14|2@0+ (1,0) [0|3] "SED"  GWM
 SG_ PrkAidSwtch_B_Stat : 8|1@0+ (1,0) [0|1] "SED"  GWM
 SG_ ApaMde_D_Avail : 12|4@0+ (1,0) [0|15] "SED"  GWM
 SG_ PrkAidSnsFrCrnr_D_Stat : 47|4@0+ (1,0) [0|15] "SED"  GWM
 SG_ PrkAidSnsFrCntr_D_Stat : 35|4@0+ (1,0) [0|15] "SED"  GWM
 SG_ PrkAidSnsFlCrnr_D_Stat : 27|4@0+ (1,0) [0|15] "SED"  GWM
 SG_ PrkAidSnsFlCntr_D_Stat : 31|4@0+ (1,0) [0|15] "SED"  GWM
 SG_ PrkBrkEl_B_RqFap : 20|1@0+ (1,0) [0|1] "SED"  GWM,ABS_ESC
 SG_ RpaChime_D_Rq : 7|4@0+ (1,0) [0|15] "SED"  GWM
 SG_ FpaChime_D_Rq : 3|4@0+ (1,0) [0|15] "SED"  GWM
 SG_ PrkAidMsgTxt_D_Rq : 19|4@0+ (1,0) [0|15] "SED"  GWM,PSCM
 SG_ SidePrkSnsL1_D_Stat : 55|4@0+ (1,0) [0|15] "SED"  GWM
 SG_ PrkAidAudioMute_B_Rq : 15|1@0+ (1,0) [0|1] "SED"  GWM

BO_ 939 ParkAid_Aud_Warn_Stat2: 8 IPMA_ADAS
 SG_ SidePrkSnsR4_D_Stat : 55|4@0+ (1,0) [0|15] "SED"  GWM
 SG_ SidePrkSnsR3_D_Stat : 47|4@0+ (1,0) [0|15] "SED"  GWM
 SG_ SidePrkSnsL4_D_Stat : 43|4@0+ (1,0) [0|15] "SED"  GWM
 SG_ SidePrkSnsL3_D_Stat : 37|4@0+ (1,0) [0|15] "SED"  GWM
 SG_ PrkAidChime_D_Stat : 4|2@0+ (1,0) [0|3] "SED"  GWM
 SG_ PrkAidSnsRlCntr_D_Stat : 15|4@0+ (1,0) [0|15] "SED"  GWM
 SG_ PrkAidSnsRrCrnr_D_Stat : 31|4@0+ (1,0) [0|15] "SED"  GWM
 SG_ PrkAidSnsRrCntr_D_Stat : 19|4@0+ (1,0) [0|15] "SED"  GWM
 SG_ PrkAidSnsRlCrnr_D_Stat : 11|4@0+ (1,0) [0|15] "SED"  GWM
 SG_ PrkAidRear_D_Stat : 39|2@0+ (1,0) [0|3] "SED"  GWM
 SG_ PrkAidFront_D_Stat : 2|2@0+ (1,0) [0|3] "SED"  GWM
 SG_ PrkAid_D_Falt : 7|3@0+ (1,0) [0|7] "SED"  GWM
 SG_ ApaLongCtrlEnbl_D_Rq : 0|1@0+ (1,0) [0|1] "SED"  TCM,SOBDMC_HPCM,ABS_ESC,ECM,ECM_Diesel,ECM_HEV,ECM_HEVDSL,PCM,PCM_HEV,TCM_DSL,GWM
 SG_ ApaBrk_A_Rq : 63|8@0+ (0.05,-12.75) [-12.75|0] "m/sec^2"  ABS_ESC,ECM,ECM_Diesel,ECM_HEV,ECM_HEVDSL,PCM,PCM_HEV,GWM
 SG_ PrkAidLamp_D_Rq : 33|2@0+ (1,0) [0|3] "SED"  GWM
 SG_ ResPrkAidSnsRrSide_D_Stat : 27|4@0+ (1,0) [0|15] "unitless"  GENERIC
 SG_ ResPrkAidSnsRlSide_D_Stat : 23|4@0+ (1,0) [0|15] "unitless"  GENERIC
 SG_ ApaBrk_D_Rq : 51|2@0+ (1,0) [0|3] "SED"  ABS_ESC,GWM

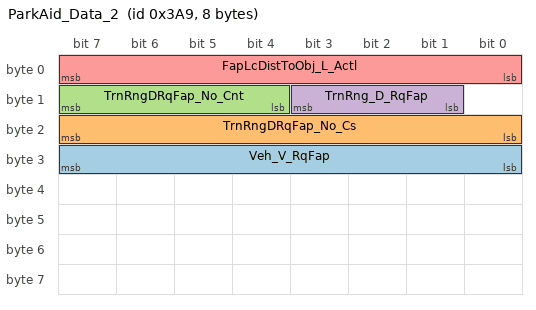
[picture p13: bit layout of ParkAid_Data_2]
BO_ 937 ParkAid_Data_2: 8 IPMA_ADAS
 SG_ Veh_V_RqFap : 31|8@0+ (0.1,0) [0|25.5] "km/h"  ECM,ECM_Diesel,ECM_HEV,ECM_HEVDSL,PCM,PCM_HEV
 SG_ TrnRngDRqFap_No_Cs : 23|8@0+ (1,0) [0|255] "unitless"  ECM_HEV,TCM,SOBDMC_HPCM,PCM,PCM_HEV,TCM_DSL
 SG_ TrnRngDRqFap_No_Cnt : 15|4@0+ (1,0) [0|15] "unitless"  ECM_HEV,TCM,SOBDMC_HPCM,PCM,PCM_HEV,TCM_DSL
 SG_ TrnRng_D_RqFap : 11|3@0+ (1,0) [0|7] "SED"  TCM,SOBDMC_HPCM,ECM,ECM_Diesel,ECM_HEV,ECM_HEVDSL,PCM,PCM_HEV,TCM_DSL,GWM
 SG_ FapLcDistToObj_L_Actl : 7|8@0+ (0.01,0) [0|2.53] "meter"  ECM,ECM_Diesel,ECM_HEV,ECM_HEVDSL,PCM,PCM_HEV

BO_TX_BU_ 820 : HCM,GWM;
BO_TX_BU_ 1137 : SOBDMC_HPCM,PCM_HEV;
CM_ SG_ 129 SelDrvMdeSwtch3_D_Stat4 "ECM_HEV does not support or Transmit signal.";
CM_ SG_ 854 RHS_Temp_Display_Digit3 "Added for MY 08";
CM_ SG_ 854 RHS_Temp_Display_Digit2 "Added for MY 08";
CM_ SG_ 854 RHS_Temp_Display_Digit1 "Added for MY 08";
CM_ SG_ 854 LHS_Temp_Display_Digit3 "Added for MY 08";
CM_ SG_ 854 LHS_Temp_Display_Digit2 "Added for MY 08";
CM_ SG_ 854 LHS_Temp_Display_Digit1 "Added for MY 08";
CM_ SG_ 854 EATC_RHS_Units "Added for MY 08";
CM_ SG_ 854 EATC_LHS_Units "Added for MY 08";
CM_ BO_ 549 "Method IPC _Infotainment";
CM_ SG_ 549 BeltminderAudioMute "Object.MyKey.BeltMinderAudioMute.St";
CM_ SG_ 549 Power_Up_Chime_Modules "Object.AlertMethod.IPC _Infotainment";
CM_ SG_ 549 Chime_Source "Object.AlertMethod.IPC_infotainment";
CM_ SG_ 1112 BattTracClntPmp_D_Stat "48V mHEV: ECM_HEVDSL is Tx,  MHT HEV: PCM_HEV is Tx,  Powersplit HEV: SOBDMC_HPCM is Tx";
CM_ SG_ 1189 Running_Board_Stat "Update msg. $115 to Event @ INIT in CMDB v4.06, 5/27/05.";
CM_ SG_ 1050 Outside_Air_Temp_Stat "Filtered value, i.e. same as disply for customer";
CM_ BO_ 1124 "HS3 APIM Sync Gen3 Tx 0x464.  FrameGateway to 0x467 on HS1, HS2, HS3 and MS1.";
BA_DEF_ BO_  "VFrameFormat" ENUM  "StandardCAN","ExtendedCAN","reserved","reserved","reserved","reserved","reserved","reserved","reserved","reserved","reserved","reserved","reserved","reserved","StandardCAN_FD","ExtendedCAN_FD";
BA_DEF_ SG_  "GenSigSendType" ENUM  "Cyclic","OnWrite","vector_leerstring","OnChange","vector_leerstring","IfActive","vector_leerstring","NoSigSendType";
BA_DEF_ SG_  "GenSigInactiveValue" INT 0 100000;
BA_DEF_ SG_  "WakeupSignal" ENUM  "No","Yes";
BA_DEF_ SG_  "UsedOnPgmDBC" ENUM  "No","Yes";
BA_DEF_ SG_  "GenSigStartValueInteger" INT 0 1000000000;
BA_DEF_ SG_  "ContentDependant" ENUM  "No","Yes";
BA_DEF_ SG_  "MetaData" ENUM  "No","Yes";
BA_DEF_ SG_  "GenSigStartValue" HEX 0 268435455;
BA_DEF_ SG_  "U_CX727_MY2021_Rx" ENUM  "No","Yes";
BA_DEF_ SG_  "U_P702_MY2021_Rx" ENUM  "No","Yes";
BA_DEF_ SG_  "U_T6_MCA_MY2020_Rx" ENUM  "No","Yes";
BA_DEF_ SG_  "ECGUsedRxSignal" ENUM  "No","Yes";
BA_DEF_ SG_  "U_CD542_MY2021_Rx" ENUM  "No","Yes";
BA_DEF_ SG_  "U_U55X_MY2022_Rx" ENUM  "No","Yes";
BA_DEF_ SG_  "U_CD764_MY2022_Rx" ENUM  "No","Yes";
BA_DEF_ SG_  "U_CDX706_MY2023_Rx" ENUM  "No","Yes";
BA_DEF_ SG_  "U_CX727_MY2021_Tx" ENUM  "No","Yes";
BA_DEF_ SG_  "U_P702_MY2021_Tx" ENUM  "No","Yes";
BA_DEF_ SG_  "U_T6_MCA_MY2020_Tx" ENUM  "No","Yes";
BA_DEF_ SG_  "ECGUsedTxSignal" ENUM  "No","Yes";
BA_DEF_ SG_  "U_CD542_MY2021_Tx" ENUM  "No","Yes";
BA_DEF_ SG_  "U_U55X_MY2022_Tx" ENUM  "No","Yes";
BA_DEF_ SG_  "U_CD764_MY2022_Tx" ENUM  "No","Yes";
BA_DEF_ SG_  "U_CDX706_MY2023_Tx" ENUM  "No","Yes";
BA_DEF_ BO_  "GenMsgILSupport" ENUM  "No","Yes";
BA_DEF_ BO_  "DiagResponse" ENUM  "No","Yes";
BA_DEF_ BO_  "DiagRequest" ENUM  "No","Yes";
BA_DEF_ BO_  "TpTxIndex" INT 0 536870911;
BA_DEF_ BO_  "DiagState" ENUM  "No","Yes";
BA_DEF_ BO_  "TpApplType" STRING ;
BA_DEF_ BO_  "NmAsrMessage" ENUM  "No","Yes";
BA_DEF_ BO_  "ProgBWConditional" STRING ;
BA_DEF_ BO_  "SCP_AuthInfoTxLength" INT 0 512;
BA_DEF_ BO_  "SCP_FreshnessValueTxLength" INT 0 512;
BA_DEF_ BO_  "SCP_FreshnessValueLength" INT 0 512;
BA_DEF_ BO_  "OvtpPushApplication" ENUM  "FALSE","TRUE";
BA_DEF_ BO_  "GenMsgSendType" ENUM  "FixedPeriodic","Event","EnabledPeriodic","NotUsed","NotUsed","EventPeriodic","NotUsed","NotUsed","NoMsgSendType";
BA_DEF_ BO_  "GenMsgCycleTime" INT 0 100000;
BA_DEF_ BO_  "GenMsgDelayTime" INT 0 1000;
BA_DEF_ BO_  "GenMsgNrOfRepetition" INT 0 100;
BA_DEF_ BO_  "GenMsgStartDelayTime" INT 0 10000;
BA_DEF_ BO_  "EventRateOfChange" INT 10 10000;
BA_DEF_ BO_  "FrameGatewayId" HEX 0 1407;
BA_DEF_ BO_  "NetworkInitialization" ENUM  "No","Yes";
BA_DEF_ BO_  "FrameGatewayNetwork" STRING ;
BA_DEF_ BO_  "FrameRouting" STRING ;
BA_DEF_DEF_  "VFrameFormat" "ExtendedCAN_FD";
BA_DEF_DEF_  "GenSigSendType" "NoSigSendType";
BA_DEF_DEF_  "GenSigInactiveValue" 0;
BA_DEF_DEF_  "WakeupSignal" "No";
BA_DEF_DEF_  "UsedOnPgmDBC" "Yes";
BA_DEF_DEF_  "GenSigStartValueInteger" 0;
BA_DEF_DEF_  "ContentDependant" "No";
BA_DEF_DEF_  "MetaData" "No";
BA_DEF_DEF_  "GenSigStartValue" 0;
BA_DEF_DEF_  "U_CX727_MY2021_Rx" "No";
BA_DEF_DEF_  "U_P702_MY2021_Rx" "No";
BA_DEF_DEF_  "U_T6_MCA_MY2020_Rx" "No";
BA_DEF_DEF_  "ECGUsedRxSignal" "No";
BA_DEF_DEF_  "U_CD542_MY2021_Rx" "No";
BA_DEF_DEF_  "U_U55X_MY2022_Rx" "No";
BA_DEF_DEF_  "U_CD764_MY2022_Rx" "No";
BA_DEF_DEF_  "U_CDX706_MY2023_Rx" "No";
BA_DEF_DEF_  "U_CX727_MY2021_Tx" "No";
BA_DEF_DEF_  "U_P702_MY2021_Tx" "No";
BA_DEF_DEF_  "U_T6_MCA_MY2020_Tx" "No";
BA_DEF_DEF_  "ECGUsedTxSignal" "No";
BA_DEF_DEF_  "U_CD542_MY2021_Tx" "No";
BA_DEF_DEF_  "U_U55X_MY2022_Tx" "No";
BA_DEF_DEF_  "U_CD764_MY2022_Tx" "No";
BA_DEF_DEF_  "U_CDX706_MY2023_Tx" "No";
BA_DEF_DEF_  "GenMsgILSupport" "Yes";
BA_DEF_DEF_  "DiagResponse" "No";
BA_DEF_DEF_  "DiagRequest" "No";
BA_DEF_DEF_  "TpTxIndex" 0;
BA_DEF_DEF_  "DiagState" "No";
BA_DEF_DEF_  "TpApplType" "";
BA_DEF_DEF_  "NmAsrMessage" "No";
BA_DEF_DEF_  "ProgBWConditional" "NONE";
BA_DEF_DEF_  "SCP_AuthInfoTxLength" 53;
BA_DEF_DEF_  "SCP_FreshnessValueTxLength" 11;
BA_DEF_DEF_  "SCP_FreshnessValueLength" 64;
BA_DEF_DEF_  "OvtpPushApplication" "FALSE";
BA_DEF_DEF_  "GenMsgSendType" "NoMsgSendType";
BA_DEF_DEF_  "GenMsgCycleTime" 0;
BA_DEF_DEF_  "GenMsgDelayTime" 20;
BA_DEF_DEF_  "GenMsgNrOfRepetition" 1;
BA_DEF_DEF_  "GenMsgStartDelayTime" 0;
BA_DEF_DEF_  "EventRateOfChange" 10000;
BA_DEF_DEF_  "FrameGatewayId" 0;
BA_DEF_DEF_  "NetworkInitialization" "Yes";
BA_DEF_DEF_  "FrameGatewayNetwork" "NONE";
BA_DEF_DEF_  "FrameRouting" "";
BA_ "GenMsgSendType" BO_ 992 5;
BA_ "GenMsgCycleTime" BO_ 992 1000;
BA_ "GenMsgSendType" BO_ 835 5;
BA_ "GenMsgCycleTime" BO_ 835 1000;
BA_ "GenMsgSendType" BO_ 817 5;
BA_ "GenMsgCycleTime" BO_ 817 1000;
BA_ "GenMsgSendType" BO_ 129 5;
BA_ "GenMsgCycleTime" BO_ 129 1000;
BA_ "GenMsgSendType" BO_ 854 5;
BA_ "GenMsgCycleTime" BO_ 854 1000;
BA_ "GenMsgSendType" BO_ 549 5;
BA_ "GenMsgCycleTime" BO_ 549 1000;
BA_ "GenMsgSendType" BO_ 1108 0;
BA_ "GenMsgCycleTime" BO_ 1108 1000;
BA_ "GenMsgSendType" BO_ 261 1;
BA_ "GenMsgSendType" BO_ 1146 0;
BA_ "GenMsgCycleTime" BO_ 1146 50;
BA_ "GenMsgSendType" BO_ 533 5;
BA_ "GenMsgCycleTime" BO_ 533 1000;
BA_ "GenMsgSendType" BO_ 1041 0;
BA_ "GenMsgCycleTime" BO_ 1041 100;
BA_ "GenMsgSendType" BO_ 1067 0;
BA_ "GenMsgCycleTime" BO_ 1067 100;
BA_ "GenMsgSendType" BO_ 1118 5;
BA_ "GenMsgCycleTime" BO_ 1118 1000;
BA_ "GenMsgSendType" BO_ 1112 5;
BA_ "GenMsgCycleTime" BO_ 1112 1000;
BA_ "GenMsgSendType" BO_ 1121 5;
BA_ "GenMsgCycleTime" BO_ 1121 1000;
BA_ "GenMsgSendType" BO_ 1189 5;
BA_ "GenMsgCycleTime" BO_ 1189 1000;
BA_ "GenMsgSendType" BO_ 1120 5;
BA_ "GenMsgCycleTime" BO_ 1120 1000;
BA_ "GenMsgSendType" BO_ 1050 5;
BA_ "GenMsgCycleTime" BO_ 1050 1000;
BA_ "GenMsgSendType" BO_ 621 5;
BA_ "GenMsgCycleTime" BO_ 621 200;
BA_ "GenMsgSendType" BO_ 1124 1;
BA_ "FrameGatewayId" BO_ 992 992;
BA_ "FrameGatewayNetwork" BO_ 992 "HS3_CAN";
BA_ "FrameRouting" BO_ 992 "HS3_CAN,0x3E0;";
BA_ "VFrameFormat" BO_ 992 14;
BA_ "FrameGatewayId" BO_ 835 835;
BA_ "FrameGatewayNetwork" BO_ 835 "HS2_CAN";
BA_ "FrameRouting" BO_ 835 "HS2_CAN,0x343;";
BA_ "VFrameFormat" BO_ 835 14;
BA_ "GenMsgSendType" BO_ 820 5;
BA_ "GenMsgCycleTime" BO_ 820 1000;
BA_ "FrameGatewayId" BO_ 820 820;
BA_ "FrameGatewayNetwork" BO_ 820 "HS2_CAN";
BA_ "FrameRouting" BO_ 820 "FD1_CAN,0x334;HS2_CAN,0x334";
BA_ "VFrameFormat" BO_ 820 14;
BA_ "FrameGatewayId" BO_ 817 817;
BA_ "FrameGatewayNetwork" BO_ 817 "HS1_CAN";
BA_ "FrameRouting" BO_ 817 "HS1_CAN,0x331;";
BA_ "VFrameFormat" BO_ 817 14;
BA_ "FrameGatewayId" BO_ 137 137;
BA_ "FrameGatewayNetwork" BO_ 137 "HS2_CAN";
BA_ "FrameRouting" BO_ 137 "HS2_CAN,0x89;";
BA_ "VFrameFormat" BO_ 137 14;
BA_ "FrameGatewayId" BO_ 129 129;
BA_ "FrameGatewayNetwork" BO_ 129 "HS2_CAN";
BA_ "FrameRouting" BO_ 129 "HS2_CAN,0x81;";
BA_ "VFrameFormat" BO_ 129 14;
BA_ "FrameGatewayId" BO_ 854 854;
BA_ "FrameGatewayNetwork" BO_ 854 "MS1_CAN";
BA_ "FrameRouting" BO_ 854 "MS1_CAN,0x356;";
BA_ "VFrameFormat" BO_ 854 14;
BA_ "FrameGatewayId" BO_ 549 549;
BA_ "FrameGatewayNetwork" BO_ 549 "HS3_CAN";
BA_ "FrameRouting" BO_ 549 "HS3_CAN,0x225;";
BA_ "VFrameFormat" BO_ 549 14;
BA_ "GenMsgSendType" BO_ 935 5;
BA_ "GenMsgCycleTime" BO_ 935 200;
BA_ "FrameRouting" BO_ 935 "FD1_CAN,0x3A7;MS1_CAN,0x3A7";
BA_ "VFrameFormat" BO_ 935 14;
BA_ "FrameGatewayId" BO_ 1108 1108;
BA_ "FrameGatewayNetwork" BO_ 1108 "HS2_CAN";
BA_ "FrameRouting" BO_ 1108 "HS2_CAN,0x454;";
BA_ "VFrameFormat" BO_ 1108 14;
BA_ "FrameGatewayId" BO_ 261 261;
BA_ "FrameGatewayNetwork" BO_ 261 "HS3_CAN";
BA_ "FrameRouting" BO_ 261 "HS3_CAN,0x105;";
BA_ "VFrameFormat" BO_ 261 14;
BA_ "FrameRouting" BO_ 1146 "HS3_CAN,0x47A;MS1_CAN,0x44A;HS2_CAN,0x47A;";
BA_ "VFrameFormat" BO_ 1146 14;
BA_ "FrameGatewayId" BO_ 533 533;
BA_ "FrameGatewayNetwork" BO_ 533 "HS3_CAN";
BA_ "FrameRouting" BO_ 533 "HS3_CAN,0x215;";
BA_ "VFrameFormat" BO_ 533 14;
BA_ "FrameGatewayId" BO_ 778 778;
BA_ "FrameGatewayNetwork" BO_ 778 "HS3_CAN";
BA_ "FrameRouting" BO_ 778 "HS3_CAN,0x30A;";
BA_ "VFrameFormat" BO_ 778 14;
BA_ "FrameGatewayId" BO_ 1041 1041;
BA_ "FrameGatewayNetwork" BO_ 1041 "HS1_CAN";
BA_ "FrameRouting" BO_ 1041 "HS1_CAN,0x411;";
BA_ "VFrameFormat" BO_ 1041 14;
BA_ "FrameGatewayId" BO_ 1067 1067;
BA_ "FrameGatewayNetwork" BO_ 1067 "HS1_CAN";
BA_ "FrameRouting" BO_ 1067 "HS1_CAN,0x42B;";
BA_ "VFrameFormat" BO_ 1067 14;
BA_ "FrameGatewayId" BO_ 1118 1118;
BA_ "FrameGatewayNetwork" BO_ 1118 "HS1_CAN";
BA_ "FrameRouting" BO_ 1118 "HS1_CAN,0x45E;";
BA_ "VFrameFormat" BO_ 1118 14;
BA_ "GenMsgSendType" BO_ 1040 0;
BA_ "GenMsgCycleTime" BO_ 1040 100;
BA_ "VFrameFormat" BO_ 1040 14;
BA_ "GenMsgSendType" BO_ 1144 5;
BA_ "GenMsgCycleTime" BO_ 1144 1000;
BA_ "VFrameFormat" BO_ 1144 14;
BA_ "FrameGatewayId" BO_ 1112 1112;
BA_ "FrameGatewayNetwork" BO_ 1112 "HS1_CAN";
BA_ "FrameRouting" BO_ 1112 "HS1_CAN,0x458;";
BA_ "VFrameFormat" BO_ 1112 14;
BA_ "FrameGatewayId" BO_ 139 139;
BA_ "FrameGatewayNetwork" BO_ 139 "HS2_CAN";
BA_ "FrameRouting" BO_ 139 "HS2_CAN,0x8B;";
BA_ "VFrameFormat" BO_ 139 14;
BA_ "FrameGatewayId" BO_ 1121 1121;
BA_ "FrameGatewayNetwork" BO_ 1121 "HS2_CAN";
BA_ "FrameRouting" BO_ 1121 "HS2_CAN,0x461;";
BA_ "VFrameFormat" BO_ 1121 14;
BA_ "FrameGatewayId" BO_ 1189 1189;
BA_ "FrameGatewayNetwork" BO_ 1189 "MS1_CAN";
BA_ "FrameRouting" BO_ 1189 "MS1_CAN,0x4A5;";
BA_ "VFrameFormat" BO_ 1189 14;
BA_ "FrameGatewayId" BO_ 1120 1120;
BA_ "FrameGatewayNetwork" BO_ 1120 "HS2_CAN";
BA_ "FrameRouting" BO_ 1120 "HS2_CAN,0x460;";
BA_ "VFrameFormat" BO_ 1120 14;
BA_ "FrameGatewayId" BO_ 1050 1050;
BA_ "FrameGatewayNetwork" BO_ 1050 "MS1_CAN";
BA_ "FrameRouting" BO_ 1050 "MS1_CAN,0x41A;";
BA_ "VFrameFormat" BO_ 1050 14;
BA_ "FrameGatewayId" BO_ 621 621;
BA_ "FrameGatewayNetwork" BO_ 621 "HS4_CAN";
BA_ "FrameRouting" BO_ 621 "HS4_CAN,0x26D;";
BA_ "VFrameFormat" BO_ 621 14;
BA_ "FrameGatewayId" BO_ 1124 1124;
BA_ "FrameGatewayNetwork" BO_ 1124 "HS3_CAN";
BA_ "FrameRouting" BO_ 1124 "HS3_CAN,0x464;";
BA_ "VFrameFormat" BO_ 1124 14;
BA_ "GenMsgSendType" BO_ 1137 0;
BA_ "GenMsgCycleTime" BO_ 1137 1000;
BA_ "VFrameFormat" BO_ 1137 14;
BA_ "GenMsgSendType" BO_ 1255 0;
BA_ "GenMsgCycleTime" BO_ 1255 1000;
BA_ "FrameRouting" BO_ 1255 "FD1_CAN,0x4E7;MS1_CAN,0x4E7";
BA_ "VFrameFormat" BO_ 1255 14;
BA_ "GenMsgSendType" BO_ 1254 0;
BA_ "GenMsgCycleTime" BO_ 1254 1000;
BA_ "FrameRouting" BO_ 1254 "FD1_CAN,0x4E6;MS1_CAN,0x4E6";
BA_ "VFrameFormat" BO_ 1254 14;
BA_ "GenMsgSendType" BO_ 1253 0;
BA_ "GenMsgCycleTime" BO_ 1253 1000;
BA_ "FrameRouting" BO_ 1253 "FD1_CAN,0x4E5;MS1_CAN,0x4E5";
BA_ "VFrameFormat" BO_ 1253 14;
BA_ "GenMsgSendType" BO_ 1252 0;
BA_ "GenMsgCycleTime" BO_ 1252 1000;
BA_ "FrameRouting" BO_ 1252 "FD1_CAN,0x4E4;MS1_CAN,0x4E4";
BA_ "VFrameFormat" BO_ 1252 14;
BA_ "GenMsgSendType" BO_ 1251 0;
BA_ "GenMsgCycleTime" BO_ 1251 1000;
BA_ "FrameRouting" BO_ 1251 "FD1_CAN,0x4E3;MS1_CAN,0x4E3";
BA_ "VFrameFormat" BO_ 1251 14;
BA_ "GenMsgSendType" BO_ 1250 0;
BA_ "GenMsgCycleTime" BO_ 1250 1000;
BA_ "FrameRouting" BO_ 1250 "FD1_CAN,0x4E2;MS1_CAN,0x4E2";
BA_ "VFrameFormat" BO_ 1250 14;
BA_ "GenMsgSendType" BO_ 1249 0;
BA_ "GenMsgCycleTime" BO_ 1249 1000;
BA_ "FrameRouting" BO_ 1249 "FD1_CAN,0x4E1;MS1_CAN,0x4E1";
BA_ "VFrameFormat" BO_ 1249 14;
BA_ "GenMsgSendType" BO_ 1248 0;
BA_ "GenMsgCycleTime" BO_ 1248 1000;
BA_ "FrameRouting" BO_ 1248 "FD1_CAN,0x4E0;MS1_CAN,0x4E0";
BA_ "VFrameFormat" BO_ 1248 14;
BA_ "TpTxIndex" BO_ 2610988248 463504600;
BA_ "GenMsgSendType" BO_ 2610988248 1;
BA_ "GenMsgDelayTime" BO_ 2610988248 0;
BA_ "NetworkInitialization" BO_ 2610988248 0;
BA_ "GenMsgSendType" BO_ 1113 0;
BA_ "GenMsgCycleTime" BO_ 1113 50;
BA_ "FrameRouting" BO_ 1113 "FD1_CAN,0x459;HS2_CAN,0x459";
BA_ "VFrameFormat" BO_ 1113 14;
BA_ "GenMsgSendType" BO_ 1105 5;
BA_ "GenMsgCycleTime" BO_ 1105 1000;
BA_ "FrameRouting" BO_ 1105 "FD1_CAN,0x451;HS2_CAN,0x451";
BA_ "VFrameFormat" BO_ 1105 14;
BA_ "GenMsgSendType" BO_ 938 5;
BA_ "GenMsgCycleTime" BO_ 938 200;
BA_ "FrameRouting" BO_ 938 "FD1_CAN,0x3AA;HS2_CAN,0x3AA";
BA_ "VFrameFormat" BO_ 938 14;
BA_ "GenMsgSendType" BO_ 939 5;
BA_ "GenMsgCycleTime" BO_ 939 200;
BA_ "FrameRouting" BO_ 939 "FD1_CAN,0x3AB;HS2_CAN,0x3AB";
BA_ "VFrameFormat" BO_ 939 14;
BA_ "GenMsgSendType" BO_ 937 0;
BA_ "GenMsgCycleTime" BO_ 937 20;
BA_ "GenMsgDelayTime" BO_ 937 10;
BA_ "FrameRouting" BO_ 937 "FD1_CAN,0x3A9;HS2_CAN,0x3A9";
BA_ "VFrameFormat" BO_ 937 14;
BA_ "GenSigStartValueInteger" SG_ 992 MsgCntrPersIndex_D_Rq 4;
BA_ "GenSigStartValue" SG_ 992 MsgCntrPersIndex_D_Rq 4;
BA_ "U_CX727_MY2021_Rx" SG_ 992 MsgCntrPersIndex_D_Rq 1;
BA_ "U_P702_MY2021_Rx" SG_ 992 MsgCntrPersIndex_D_Rq 1;
BA_ "U_T6_MCA_MY2020_Rx" SG_ 992 MsgCntrPersIndex_D_Rq 1;
BA_ "U_CD542_MY2021_Rx" SG_ 992 MsgCntrPersIndex_D_Rq 1;
BA_ "U_U55X_MY2022_Rx" SG_ 992 MsgCntrPersIndex_D_Rq 1;
BA_ "U_CD764_MY2022_Rx" SG_ 992 MsgCntrPersIndex_D_Rq 1;
BA_ "U_CDX706_MY2023_Rx" SG_ 992 MsgCntrPersIndex_D_Rq 1;
BA_ "U_CX727_MY2021_Rx" SG_ 992 MsgCntrFeatConfigRq 1;
BA_ "U_P702_MY2021_Rx" SG_ 992 MsgCntrFeatConfigRq 1;
BA_ "U_T6_MCA_MY2020_Rx" SG_ 992 MsgCntrFeatConfigRq 1;
BA_ "U_CD542_MY2021_Rx" SG_ 992 MsgCntrFeatConfigRq 1;
BA_ "U_U55X_MY2022_Rx" SG_ 992 MsgCntrFeatConfigRq 1;
BA_ "U_CD764_MY2022_Rx" SG_ 992 MsgCntrFeatConfigRq 1;
BA_ "U_CDX706_MY2023_Rx" SG_ 992 MsgCntrFeatConfigRq 1;
BA_ "U_CX727_MY2021_Rx" SG_ 992 MsgCntrFeatNoRq 1;
BA_ "U_P702_MY2021_Rx" SG_ 992 MsgCntrFeatNoRq 1;
BA_ "U_T6_MCA_MY2020_Rx" SG_ 992 MsgCntrFeatNoRq 1;
BA_ "U_CD542_MY2021_Rx" SG_ 992 MsgCntrFeatNoRq 1;
BA_ "U_U55X_MY2022_Rx" SG_ 992 MsgCntrFeatNoRq 1;
BA_ "U_CD764_MY2022_Rx" SG_ 992 MsgCntrFeatNoRq 1;
BA_ "U_CDX706_MY2023_Rx" SG_ 992 MsgCntrFeatNoRq 1;
BA_ "U_CX727_MY2021_Rx" SG_ 992 MsgCntrDsplyOp_D_Rq 1;
BA_ "U_P702_MY2021_Rx" SG_ 992 MsgCntrDsplyOp_D_Rq 1;
BA_ "U_T6_MCA_MY2020_Rx" SG_ 992 MsgCntrDsplyOp_D_Rq 1;
BA_ "U_CD542_MY2021_Rx" SG_ 992 MsgCntrDsplyOp_D_Rq 1;
BA_ "U_U55X_MY2022_Rx" SG_ 992 MsgCntrDsplyOp_D_Rq 1;
BA_ "U_CD764_MY2022_Rx" SG_ 992 MsgCntrDsplyOp_D_Rq 1;
BA_ "U_CDX706_MY2023_Rx" SG_ 992 MsgCntrDsplyOp_D_Rq 1;
BA_ "GenSigSendType" SG_ 820 TailLghtAnmtn_D_Stat 3;
BA_ "GenSigStartValue" SG_ 820 TailLghtAnmtn_D_Stat 1;
BA_ "ECGUsedRxSignal" SG_ 820 TailLghtAnmtn_D_Stat 1;
BA_ "GenSigSendType" SG_ 820 AhbStatGfhbFdbk_D_Actl 3;
BA_ "U_T6_MCA_MY2020_Rx" SG_ 820 AhbStatGfhbFdbk_D_Actl 1;
BA_ "U_CD542_MY2021_Rx" SG_ 820 AhbStatGfhbFdbk_D_Actl 1;
BA_ "U_U55X_MY2022_Rx" SG_ 820 AhbStatGfhbFdbk_D_Actl 1;
BA_ "U_CD764_MY2022_Rx" SG_ 820 AhbStatGfhbFdbk_D_Actl 1;
BA_ "U_CDX706_MY2023_Rx" SG_ 820 AhbStatGfhbFdbk_D_Actl 1;
BA_ "U_CX727_MY2021_Tx" SG_ 820 AhbStatGfhbFdbk_D_Actl 1;
BA_ "U_P702_MY2021_Tx" SG_ 820 AhbStatGfhbFdbk_D_Actl 1;
BA_ "U_U55X_MY2022_Tx" SG_ 820 AhbStatGfhbFdbk_D_Actl 1;
BA_ "U_CD764_MY2022_Tx" SG_ 820 AhbStatGfhbFdbk_D_Actl 1;
BA_ "GenSigSendType" SG_ 820 HeadLghtDrvSide_B_Stat 3;
BA_ "U_T6_MCA_MY2020_Rx" SG_ 820 HeadLghtDrvSide_B_Stat 1;
BA_ "U_CD542_MY2021_Rx" SG_ 820 HeadLghtDrvSide_B_Stat 1;
BA_ "U_U55X_MY2022_Rx" SG_ 820 HeadLghtDrvSide_B_Stat 1;
BA_ "U_CD764_MY2022_Rx" SG_ 820 HeadLghtDrvSide_B_Stat 1;
BA_ "U_CDX706_MY2023_Rx" SG_ 820 HeadLghtDrvSide_B_Stat 1;
BA_ "U_CX727_MY2021_Tx" SG_ 820 HeadLghtDrvSide_B_Stat 1;
BA_ "U_P702_MY2021_Tx" SG_ 820 HeadLghtDrvSide_B_Stat 1;
BA_ "U_U55X_MY2022_Tx" SG_ 820 HeadLghtDrvSide_B_Stat 1;
BA_ "U_CD764_MY2022_Tx" SG_ 820 HeadLghtDrvSide_B_Stat 1;
BA_ "GenSigSendType" SG_ 820 HeadLghtHiOn_B_StatHcm 3;
BA_ "U_CX727_MY2021_Tx" SG_ 820 HeadLghtHiOn_B_StatHcm 1;
BA_ "U_P702_MY2021_Tx" SG_ 820 HeadLghtHiOn_B_StatHcm 1;
BA_ "U_U55X_MY2022_Tx" SG_ 820 HeadLghtHiOn_B_StatHcm 1;
BA_ "U_CD764_MY2022_Tx" SG_ 820 HeadLghtHiOn_B_StatHcm 1;
BA_ "GenSigSendType" SG_ 820 Adaptive_Hdlmp_Fault 3;
BA_ "U_CX727_MY2021_Tx" SG_ 820 Adaptive_Hdlmp_Fault 1;
BA_ "U_P702_MY2021_Tx" SG_ 820 Adaptive_Hdlmp_Fault 1;
BA_ "U_U55X_MY2022_Tx" SG_ 820 Adaptive_Hdlmp_Fault 1;
BA_ "U_CD764_MY2022_Tx" SG_ 820 Adaptive_Hdlmp_Fault 1;
BA_ "GenSigSendType" SG_ 820 TurnLampFrOut_B_Stat 3;
BA_ "U_CD764_MY2022_Tx" SG_ 820 TurnLampFrOut_B_Stat 1;
BA_ "GenSigSendType" SG_ 820 TurnLampFlOut_B_Stat 3;
BA_ "U_CD764_MY2022_Tx" SG_ 820 TurnLampFlOut_B_Stat 1;
BA_ "WakeupSignal" SG_ 817 DrTgateOpen_B_Rq 1;
BA_ "WakeupSignal" SG_ 817 DrTgateExtSwMde_B_Stat 1;
BA_ "WakeupSignal" SG_ 817 Remote_Device_Feedback 1;
BA_ "WakeupSignal" SG_ 817 Veh_Lock_Requestor 1;
BA_ "U_T6_MCA_MY2020_Rx" SG_ 817 Veh_Lock_Requestor 1;
BA_ "WakeupSignal" SG_ 817 R_Pwr_Sliding_Dr_Rqst 1;
BA_ "WakeupSignal" SG_ 817 Power_Liftgate_Rqst 1;
BA_ "WakeupSignal" SG_ 817 Veh_Lock_EvNum 1;
BA_ "U_T6_MCA_MY2020_Rx" SG_ 817 Veh_Lock_EvNum 1;
BA_ "WakeupSignal" SG_ 817 Power_Decklid_Rqst 1;
BA_ "WakeupSignal" SG_ 817 L_Pwr_Sliding_Dr_Rqst 1;
BA_ "WakeupSignal" SG_ 817 Keyfob_Pad_Msg_Count 1;
BA_ "WakeupSignal" SG_ 817 Veh_Lock_Status 1;
BA_ "GenSigStartValueInteger" SG_ 817 Veh_Lock_Status 1;
BA_ "GenSigStartValue" SG_ 817 Veh_Lock_Status 1;
BA_ "U_T6_MCA_MY2020_Rx" SG_ 817 Veh_Lock_Status 1;
BA_ "U_CD542_MY2021_Rx" SG_ 817 Veh_Lock_Status 1;
BA_ "U_U55X_MY2022_Rx" SG_ 817 Veh_Lock_Status 1;
BA_ "U_CD764_MY2022_Rx" SG_ 817 Veh_Lock_Status 1;
BA_ "U_CDX706_MY2023_Rx" SG_ 817 Veh_Lock_Status 1;
BA_ "WakeupSignal" SG_ 817 ChildLck_D_Dsply 1;
BA_ "GenSigStartValueInteger" SG_ 817 ChildLck_D_Dsply 1;
BA_ "GenSigStartValue" SG_ 817 ChildLck_D_Dsply 1;
BA_ "WakeupSignal" SG_ 817 Lockmsgtxt_D_Rq 1;
BA_ "WakeupSignal" SG_ 817 LockInhibit 1;
BA_ "GenSigStartValueInteger" SG_ 137 SteWhlOffstRq_D_Stat 2;
BA_ "GenSigStartValue" SG_ 137 SteWhlOffstRq_D_Stat 2;
BA_ "U_P702_MY2021_Rx" SG_ 137 SteWhlOffstRq_D_Stat 1;
BA_ "GenSigStartValueInteger" SG_ 137 SteWhlOffst_An_TotActl 32766;
BA_ "GenSigStartValue" SG_ 137 SteWhlOffst_An_TotActl 32765;
BA_ "U_P702_MY2021_Rx" SG_ 137 SteWhlOffst_An_TotActl 1;
BA_ "GenSigStartValueInteger" SG_ 137 SteWhlBrkOffst_An_Actl 32766;
BA_ "GenSigStartValue" SG_ 137 SteWhlBrkOffst_An_Actl 32765;
BA_ "U_P702_MY2021_Rx" SG_ 137 SteWhlBrkOffst_An_Actl 1;
BA_ "MetaData" SG_ 137 SteWhlBrkAnActl_No_Cs 1;
BA_ "U_P702_MY2021_Rx" SG_ 137 SteWhlBrkAnActl_No_Cs 1;
BA_ "MetaData" SG_ 137 SteWhlBrkAnActl_No_Cnt 1;
BA_ "U_P702_MY2021_Rx" SG_ 137 SteWhlBrkAnActl_No_Cnt 1;
BA_ "U_CX727_MY2021_Rx" SG_ 129 SelDrvMdeSwtch_D_Stat4 1;
BA_ "U_P702_MY2021_Rx" SG_ 129 SelDrvMdeSwtch_D_Stat4 1;
BA_ "U_T6_MCA_MY2020_Rx" SG_ 129 SelDrvMdeSwtch_D_Stat4 1;
BA_ "U_U55X_MY2022_Rx" SG_ 129 SelDrvMdeSwtch_D_Stat4 1;
BA_ "WakeupSignal" SG_ 129 SteWhlSwtchView_B_Stat 1;
BA_ "WakeupSignal" SG_ 129 SteWhlSwtchSet_B_Stat 1;
BA_ "WakeupSignal" SG_ 129 SteWhlSwtchPhon_B_Stat 1;
BA_ "WakeupSignal" SG_ 129 SteWhlSwtchNav_B_Stat 1;
BA_ "WakeupSignal" SG_ 129 SteWhlSwtchMed_B_Stat 1;
BA_ "WakeupSignal" SG_ 129 SteWhlSwtchIod_B_Stat 1;
BA_ "WakeupSignal" SG_ 129 SteWhlSwtchHud_B_Stat 1;
BA_ "WakeupSignal" SG_ 129 SteWhlSwtchBack_B_Stat 1;
BA_ "WakeupSignal" SG_ 129 SteWhlSwtchMenu_B_Stat 1;
BA_ "WakeupSignal" SG_ 129 SteWhlSwtchUp_B_Stat 1;
BA_ "WakeupSignal" SG_ 129 SteWhlSwtchRght_B_Stat 1;
BA_ "WakeupSignal" SG_ 129 SteWhlSwtchOk_B_Stat 1;
BA_ "WakeupSignal" SG_ 129 SteWhlSwtchLeft_B_Stat 1;
BA_ "WakeupSignal" SG_ 129 SteWhlSwtchDown_B_Stat 1;
BA_ "ContentDependant" SG_ 129 SelDrvMdeSwtch3_D_Stat4 1;
BA_ "U_CDX706_MY2023_Rx" SG_ 129 SelDrvMdeSwtch3_D_Stat4 1;
BA_ "U_CDX706_MY2023_Rx" SG_ 129 SelDrvMdeSwtch2_D_Stat4 1;
BA_ "U_CDX706_MY2023_Rx" SG_ 129 SelDrvMdeSwtch1_D_Stat4 1;
BA_ "GenSigStartValueInteger" SG_ 854 Dsp_RotAddrBtnEv_St 7;
BA_ "GenSigStartValue" SG_ 854 Dsp_RotAddrBtnEv_St 7;
BA_ "U_T6_MCA_MY2020_Rx" SG_ 854 SelDrvMdeSwtch_D_Stat2 1;
BA_ "U_U55X_MY2022_Rx" SG_ 854 SelDrvMdeSwtch_D_Stat2 1;
BA_ "GenSigStartValueInteger" SG_ 854 Front_Blower_Indicate 15;
BA_ "GenSigStartValue" SG_ 854 Front_Blower_Indicate 15;
BA_ "GenSigStartValue" SG_ 854 LHS_Auto_Seat_Btn_Stt 2;
BA_ "GenSigStartValue" SG_ 854 RHS_Auto_Seat_Btn_Stt 2;
BA_ "U_CDX706_MY2023_Rx" SG_ 549 TjaLcEnbl_D_DrvRq 1;
BA_ "U_CDX706_MY2023_Rx" SG_ 549 BattTracLoThres_D_Rq2 1;
BA_ "U_T6_MCA_MY2020_Rx" SG_ 549 Veh_V2_Dsply 1;
BA_ "U_CD542_MY2021_Rx" SG_ 549 Veh_V2_Dsply 1;
BA_ "U_U55X_MY2022_Rx" SG_ 549 Veh_V2_Dsply 1;
BA_ "U_CD764_MY2022_Rx" SG_ 549 Veh_V2_Dsply 1;
BA_ "U_CDX706_MY2023_Rx" SG_ 549 Veh_V2_Dsply 1;
BA_ "U_U55X_MY2022_Rx" SG_ 549 HdcOn_B_Rq 1;
BA_ "WakeupSignal" SG_ 549 Power_Up_Chime_Modules 1;
BA_ "U_T6_MCA_MY2020_Rx" SG_ 549 WwaActv_B_Stat 1;
BA_ "U_CD542_MY2021_Rx" SG_ 549 WwaActv_B_Stat 1;
BA_ "U_U55X_MY2022_Rx" SG_ 549 WwaActv_B_Stat 1;
BA_ "U_CD764_MY2022_Rx" SG_ 549 WwaActv_B_Stat 1;
BA_ "U_CDX706_MY2023_Rx" SG_ 549 WwaActv_B_Stat 1;
BA_ "U_T6_MCA_MY2020_Rx" SG_ 549 StrtInGearOk_D_Stat 1;
BA_ "GenSigSendType" SG_ 935 CtaAlrtRight2_D_Stat 3;
BA_ "U_T6_MCA_MY2020_Tx" SG_ 935 CtaAlrtRight2_D_Stat 1;
BA_ "U_CD542_MY2021_Tx" SG_ 935 CtaAlrtRight2_D_Stat 1;
BA_ "U_U55X_MY2022_Tx" SG_ 935 CtaAlrtRight2_D_Stat 1;
BA_ "U_CD764_MY2022_Tx" SG_ 935 CtaAlrtRight2_D_Stat 1;
BA_ "U_CDX706_MY2023_Tx" SG_ 935 CtaAlrtRight2_D_Stat 1;
BA_ "GenSigSendType" SG_ 935 BttRight_D_Stat 3;
BA_ "U_T6_MCA_MY2020_Tx" SG_ 935 BttRight_D_Stat 1;
BA_ "U_CD542_MY2021_Tx" SG_ 935 BttRight_D_Stat 1;
BA_ "U_U55X_MY2022_Tx" SG_ 935 BttRight_D_Stat 1;
BA_ "U_CD764_MY2022_Tx" SG_ 935 BttRight_D_Stat 1;
BA_ "GenSigSendType" SG_ 935 BttRight_D_RqDrv 3;
BA_ "U_T6_MCA_MY2020_Tx" SG_ 935 BttRight_D_RqDrv 1;
BA_ "U_CD542_MY2021_Tx" SG_ 935 BttRight_D_RqDrv 1;
BA_ "U_U55X_MY2022_Tx" SG_ 935 BttRight_D_RqDrv 1;
BA_ "U_CD764_MY2022_Tx" SG_ 935 BttRight_D_RqDrv 1;
BA_ "GenSigSendType" SG_ 935 CtaBrkRightMsgTxt_B_Rq 3;
BA_ "U_T6_MCA_MY2020_Tx" SG_ 935 CtaBrkRightMsgTxt_B_Rq 1;
BA_ "U_CD542_MY2021_Tx" SG_ 935 CtaBrkRightMsgTxt_B_Rq 1;
BA_ "U_U55X_MY2022_Tx" SG_ 935 CtaBrkRightMsgTxt_B_Rq 1;
BA_ "U_CD764_MY2022_Tx" SG_ 935 CtaBrkRightMsgTxt_B_Rq 1;
BA_ "U_CDX706_MY2023_Tx" SG_ 935 CtaBrkRightMsgTxt_B_Rq 1;
BA_ "GenSigSendType" SG_ 935 CtaRightBrkEnbl_B_Rq 3;
BA_ "U_CX727_MY2021_Rx" SG_ 935 CtaRightBrkEnbl_B_Rq 1;
BA_ "U_P702_MY2021_Rx" SG_ 935 CtaRightBrkEnbl_B_Rq 1;
BA_ "U_T6_MCA_MY2020_Rx" SG_ 935 CtaRightBrkEnbl_B_Rq 1;
BA_ "U_CD542_MY2021_Rx" SG_ 935 CtaRightBrkEnbl_B_Rq 1;
BA_ "U_U55X_MY2022_Rx" SG_ 935 CtaRightBrkEnbl_B_Rq 1;
BA_ "U_CD764_MY2022_Rx" SG_ 935 CtaRightBrkEnbl_B_Rq 1;
BA_ "U_CDX706_MY2023_Rx" SG_ 935 CtaRightBrkEnbl_B_Rq 1;
BA_ "U_T6_MCA_MY2020_Tx" SG_ 935 CtaRightBrkEnbl_B_Rq 1;
BA_ "U_CD542_MY2021_Tx" SG_ 935 CtaRightBrkEnbl_B_Rq 1;
BA_ "U_U55X_MY2022_Tx" SG_ 935 CtaRightBrkEnbl_B_Rq 1;
BA_ "U_CD764_MY2022_Tx" SG_ 935 CtaRightBrkEnbl_B_Rq 1;
BA_ "U_CDX706_MY2023_Tx" SG_ 935 CtaRightBrkEnbl_B_Rq 1;
BA_ "GenSigSendType" SG_ 935 CtaRightBrkDecel_B_Rq 3;
BA_ "U_CX727_MY2021_Rx" SG_ 935 CtaRightBrkDecel_B_Rq 1;
BA_ "U_P702_MY2021_Rx" SG_ 935 CtaRightBrkDecel_B_Rq 1;
BA_ "U_T6_MCA_MY2020_Rx" SG_ 935 CtaRightBrkDecel_B_Rq 1;
BA_ "U_CD542_MY2021_Rx" SG_ 935 CtaRightBrkDecel_B_Rq 1;
BA_ "U_U55X_MY2022_Rx" SG_ 935 CtaRightBrkDecel_B_Rq 1;
BA_ "U_CD764_MY2022_Rx" SG_ 935 CtaRightBrkDecel_B_Rq 1;
BA_ "U_CDX706_MY2023_Rx" SG_ 935 CtaRightBrkDecel_B_Rq 1;
BA_ "U_T6_MCA_MY2020_Tx" SG_ 935 CtaRightBrkDecel_B_Rq 1;
BA_ "U_CD542_MY2021_Tx" SG_ 935 CtaRightBrkDecel_B_Rq 1;
BA_ "U_U55X_MY2022_Tx" SG_ 935 CtaRightBrkDecel_B_Rq 1;
BA_ "U_CD764_MY2022_Tx" SG_ 935 CtaRightBrkDecel_B_Rq 1;
BA_ "U_CDX706_MY2023_Tx" SG_ 935 CtaRightBrkDecel_B_Rq 1;
BA_ "GenSigStartValueInteger" SG_ 935 Side_Detect_R_Illum 100;
BA_ "GenSigStartValue" SG_ 935 Side_Detect_R_Illum 100;
BA_ "U_T6_MCA_MY2020_Tx" SG_ 935 Side_Detect_R_Illum 1;
BA_ "U_CD542_MY2021_Tx" SG_ 935 Side_Detect_R_Illum 1;
BA_ "U_U55X_MY2022_Tx" SG_ 935 Side_Detect_R_Illum 1;
BA_ "U_CD764_MY2022_Tx" SG_ 935 Side_Detect_R_Illum 1;
BA_ "U_CDX706_MY2023_Tx" SG_ 935 Side_Detect_R_Illum 1;
BA_ "GenSigSendType" SG_ 935 CtaSnsRight_D_Stat 3;
BA_ "U_T6_MCA_MY2020_Tx" SG_ 935 CtaSnsRight_D_Stat 1;
BA_ "U_CD542_MY2021_Tx" SG_ 935 CtaSnsRight_D_Stat 1;
BA_ "U_U55X_MY2022_Tx" SG_ 935 CtaSnsRight_D_Stat 1;
BA_ "U_CD764_MY2022_Tx" SG_ 935 CtaSnsRight_D_Stat 1;
BA_ "U_CDX706_MY2023_Tx" SG_ 935 CtaSnsRight_D_Stat 1;
BA_ "GenSigSendType" SG_ 935 CtaAlrtRight_D_Stat 3;
BA_ "U_T6_MCA_MY2020_Tx" SG_ 935 CtaAlrtRight_D_Stat 1;
BA_ "U_CD542_MY2021_Tx" SG_ 935 CtaAlrtRight_D_Stat 1;
BA_ "U_U55X_MY2022_Tx" SG_ 935 CtaAlrtRight_D_Stat 1;
BA_ "U_CD764_MY2022_Tx" SG_ 935 CtaAlrtRight_D_Stat 1;
BA_ "U_CDX706_MY2023_Tx" SG_ 935 CtaAlrtRight_D_Stat 1;
BA_ "GenSigSendType" SG_ 935 CtaRight_D_Stat 3;
BA_ "U_T6_MCA_MY2020_Tx" SG_ 935 CtaRight_D_Stat 1;
BA_ "U_CD542_MY2021_Tx" SG_ 935 CtaRight_D_Stat 1;
BA_ "U_U55X_MY2022_Tx" SG_ 935 CtaRight_D_Stat 1;
BA_ "U_CD764_MY2022_Tx" SG_ 935 CtaRight_D_Stat 1;
BA_ "U_CDX706_MY2023_Tx" SG_ 935 CtaRight_D_Stat 1;
BA_ "GenSigSendType" SG_ 935 SodRight_D_Stat 3;
BA_ "GenSigStartValueInteger" SG_ 935 SodRight_D_Stat 2;
BA_ "GenSigStartValue" SG_ 935 SodRight_D_Stat 2;
BA_ "U_T6_MCA_MY2020_Tx" SG_ 935 SodRight_D_Stat 1;
BA_ "U_CD542_MY2021_Tx" SG_ 935 SodRight_D_Stat 1;
BA_ "U_U55X_MY2022_Tx" SG_ 935 SodRight_D_Stat 1;
BA_ "U_CD764_MY2022_Tx" SG_ 935 SodRight_D_Stat 1;
BA_ "U_CDX706_MY2023_Tx" SG_ 935 SodRight_D_Stat 1;
BA_ "GenSigSendType" SG_ 935 SodSnsRight_D_Stat 3;
BA_ "U_T6_MCA_MY2020_Tx" SG_ 935 SodSnsRight_D_Stat 1;
BA_ "U_CD542_MY2021_Tx" SG_ 935 SodSnsRight_D_Stat 1;
BA_ "U_U55X_MY2022_Tx" SG_ 935 SodSnsRight_D_Stat 1;
BA_ "U_CD764_MY2022_Tx" SG_ 935 SodSnsRight_D_Stat 1;
BA_ "U_CDX706_MY2023_Tx" SG_ 935 SodSnsRight_D_Stat 1;
BA_ "GenSigSendType" SG_ 935 SodAlrtRight_D_Stat 3;
BA_ "U_T6_MCA_MY2020_Tx" SG_ 935 SodAlrtRight_D_Stat 1;
BA_ "U_CD542_MY2021_Tx" SG_ 935 SodAlrtRight_D_Stat 1;
BA_ "U_U55X_MY2022_Tx" SG_ 935 SodAlrtRight_D_Stat 1;
BA_ "U_CD764_MY2022_Tx" SG_ 935 SodAlrtRight_D_Stat 1;
BA_ "U_CDX706_MY2023_Tx" SG_ 935 SodAlrtRight_D_Stat 1;
BA_ "GenSigSendType" SG_ 935 SodDetctRight_D_Stat 3;
BA_ "U_T6_MCA_MY2020_Tx" SG_ 935 SodDetctRight_D_Stat 1;
BA_ "U_CD542_MY2021_Tx" SG_ 935 SodDetctRight_D_Stat 1;
BA_ "U_U55X_MY2022_Tx" SG_ 935 SodDetctRight_D_Stat 1;
BA_ "U_CD764_MY2022_Tx" SG_ 935 SodDetctRight_D_Stat 1;
BA_ "U_CDX706_MY2023_Tx" SG_ 935 SodDetctRight_D_Stat 1;
BA_ "GenSigStartValueInteger" SG_ 935 SodWarnRight_Prd_Rq 14;
BA_ "GenSigStartValue" SG_ 935 SodWarnRight_Prd_Rq 14;
BA_ "U_T6_MCA_MY2020_Tx" SG_ 935 SodWarnRight_Prd_Rq 1;
BA_ "U_CD542_MY2021_Tx" SG_ 935 SodWarnRight_Prd_Rq 1;
BA_ "U_U55X_MY2022_Tx" SG_ 935 SodWarnRight_Prd_Rq 1;
BA_ "U_CD764_MY2022_Tx" SG_ 935 SodWarnRight_Prd_Rq 1;
BA_ "U_CDX706_MY2023_Tx" SG_ 935 SodWarnRight_Prd_Rq 1;
BA_ "U_CX727_MY2021_Rx" SG_ 1108 RCMSerialNoByte8 1;
BA_ "U_P702_MY2021_Rx" SG_ 1108 RCMSerialNoByte8 1;
BA_ "U_T6_MCA_MY2020_Rx" SG_ 1108 RCMSerialNoByte8 1;
BA_ "U_CD542_MY2021_Rx" SG_ 1108 RCMSerialNoByte8 1;
BA_ "U_U55X_MY2022_Rx" SG_ 1108 RCMSerialNoByte8 1;
BA_ "U_CD764_MY2022_Rx" SG_ 1108 RCMSerialNoByte8 1;
BA_ "U_CDX706_MY2023_Rx" SG_ 1108 RCMSerialNoByte8 1;
BA_ "U_CX727_MY2021_Rx" SG_ 1108 RCMSerialNoByte7 1;
BA_ "U_P702_MY2021_Rx" SG_ 1108 RCMSerialNoByte7 1;
BA_ "U_T6_MCA_MY2020_Rx" SG_ 1108 RCMSerialNoByte7 1;
BA_ "U_CD542_MY2021_Rx" SG_ 1108 RCMSerialNoByte7 1;
BA_ "U_U55X_MY2022_Rx" SG_ 1108 RCMSerialNoByte7 1;
BA_ "U_CD764_MY2022_Rx" SG_ 1108 RCMSerialNoByte7 1;
BA_ "U_CDX706_MY2023_Rx" SG_ 1108 RCMSerialNoByte7 1;
BA_ "U_CX727_MY2021_Rx" SG_ 1108 RCMSerialNoByte6 1;
BA_ "U_P702_MY2021_Rx" SG_ 1108 RCMSerialNoByte6 1;
BA_ "U_T6_MCA_MY2020_Rx" SG_ 1108 RCMSerialNoByte6 1;
BA_ "U_CD542_MY2021_Rx" SG_ 1108 RCMSerialNoByte6 1;
BA_ "U_U55X_MY2022_Rx" SG_ 1108 RCMSerialNoByte6 1;
BA_ "U_CD764_MY2022_Rx" SG_ 1108 RCMSerialNoByte6 1;
BA_ "U_CDX706_MY2023_Rx" SG_ 1108 RCMSerialNoByte6 1;
BA_ "U_CX727_MY2021_Rx" SG_ 1108 RCMSerialNoByte5 1;
BA_ "U_P702_MY2021_Rx" SG_ 1108 RCMSerialNoByte5 1;
BA_ "U_T6_MCA_MY2020_Rx" SG_ 1108 RCMSerialNoByte5 1;
BA_ "U_CD542_MY2021_Rx" SG_ 1108 RCMSerialNoByte5 1;
BA_ "U_U55X_MY2022_Rx" SG_ 1108 RCMSerialNoByte5 1;
BA_ "U_CD764_MY2022_Rx" SG_ 1108 RCMSerialNoByte5 1;
BA_ "U_CDX706_MY2023_Rx" SG_ 1108 RCMSerialNoByte5 1;
BA_ "U_CX727_MY2021_Rx" SG_ 1108 RCMSerialNoByte4 1;
BA_ "U_P702_MY2021_Rx" SG_ 1108 RCMSerialNoByte4 1;
BA_ "U_T6_MCA_MY2020_Rx" SG_ 1108 RCMSerialNoByte4 1;
BA_ "U_CD542_MY2021_Rx" SG_ 1108 RCMSerialNoByte4 1;
BA_ "U_U55X_MY2022_Rx" SG_ 1108 RCMSerialNoByte4 1;
BA_ "U_CD764_MY2022_Rx" SG_ 1108 RCMSerialNoByte4 1;
BA_ "U_CDX706_MY2023_Rx" SG_ 1108 RCMSerialNoByte4 1;
BA_ "U_CX727_MY2021_Rx" SG_ 1108 RCMSerialNoByte3 1;
BA_ "U_P702_MY2021_Rx" SG_ 1108 RCMSerialNoByte3 1;
BA_ "U_T6_MCA_MY2020_Rx" SG_ 1108 RCMSerialNoByte3 1;
BA_ "U_CD542_MY2021_Rx" SG_ 1108 RCMSerialNoByte3 1;
BA_ "U_U55X_MY2022_Rx" SG_ 1108 RCMSerialNoByte3 1;
BA_ "U_CD764_MY2022_Rx" SG_ 1108 RCMSerialNoByte3 1;
BA_ "U_CDX706_MY2023_Rx" SG_ 1108 RCMSerialNoByte3 1;
BA_ "U_CX727_MY2021_Rx" SG_ 1108 RCMSerialNoByte2 1;
BA_ "U_P702_MY2021_Rx" SG_ 1108 RCMSerialNoByte2 1;
BA_ "U_T6_MCA_MY2020_Rx" SG_ 1108 RCMSerialNoByte2 1;
BA_ "U_CD542_MY2021_Rx" SG_ 1108 RCMSerialNoByte2 1;
BA_ "U_U55X_MY2022_Rx" SG_ 1108 RCMSerialNoByte2 1;
BA_ "U_CD764_MY2022_Rx" SG_ 1108 RCMSerialNoByte2 1;
BA_ "U_CDX706_MY2023_Rx" SG_ 1108 RCMSerialNoByte2 1;
BA_ "U_CX727_MY2021_Rx" SG_ 1108 RCMSerialNoByte1 1;
BA_ "U_P702_MY2021_Rx" SG_ 1108 RCMSerialNoByte1 1;
BA_ "U_T6_MCA_MY2020_Rx" SG_ 1108 RCMSerialNoByte1 1;
BA_ "U_CD542_MY2021_Rx" SG_ 1108 RCMSerialNoByte1 1;
BA_ "U_U55X_MY2022_Rx" SG_ 1108 RCMSerialNoByte1 1;
BA_ "U_CD764_MY2022_Rx" SG_ 1108 RCMSerialNoByte1 1;
BA_ "U_CDX706_MY2023_Rx" SG_ 1108 RCMSerialNoByte1 1;
BA_ "GenSigStartValueInteger" SG_ 261 ChrgStatDsply_D_Rq 1;
BA_ "GenSigStartValue" SG_ 261 ChrgStatDsply_D_Rq 1;
BA_ "U_CX727_MY2021_Rx" SG_ 261 ModemReset_D_Rq 1;
BA_ "U_CD542_MY2021_Rx" SG_ 261 ModemReset_D_Rq 1;
BA_ "U_CDX706_MY2023_Rx" SG_ 261 ModemReset_D_Rq 1;
BA_ "U_T6_MCA_MY2020_Rx" SG_ 261 StopStrtDrvMde_B_RqBtn3 1;
BA_ "U_CD542_MY2021_Rx" SG_ 261 StopStrtDrvMde_B_RqBtn3 1;
BA_ "U_CD764_MY2022_Rx" SG_ 261 StopStrtDrvMde_B_RqBtn3 1;
BA_ "U_CDX706_MY2023_Rx" SG_ 261 StopStrtDrvMde_B_RqBtn3 1;
BA_ "U_CX727_MY2021_Rx" SG_ 261 FactoryReset_Rq 1;
BA_ "U_P702_MY2021_Rx" SG_ 261 FactoryReset_Rq 1;
BA_ "U_CDX706_MY2023_Rx" SG_ 261 FactoryReset_Rq 1;
BA_ "U_P702_MY2021_Rx" SG_ 1146 TrlrAidSwtch_D_RqDrv 1;
BA_ "U_T6_MCA_MY2020_Rx" SG_ 1146 TrlrAidSwtch_D_RqDrv 1;
BA_ "U_CD542_MY2021_Rx" SG_ 1146 TrlrAidSwtch_D_RqDrv 1;
BA_ "U_U55X_MY2022_Rx" SG_ 1146 TrlrAidSwtch_D_RqDrv 1;
BA_ "U_CD764_MY2022_Rx" SG_ 1146 TrlrAidSwtch_D_RqDrv 1;
BA_ "U_CDX706_MY2023_Rx" SG_ 1146 TrlrAidSwtch_D_RqDrv 1;
BA_ "GenSigStartValueInteger" SG_ 1146 TrlrAidCtl_U_RqDrv 4094;
BA_ "GenSigStartValue" SG_ 1146 TrlrAidCtl_U_RqDrv 4093;
BA_ "U_P702_MY2021_Rx" SG_ 1146 TrlrAidCtl_U_RqDrv 1;
BA_ "U_T6_MCA_MY2020_Rx" SG_ 1146 TrlrAidCtl_U_RqDrv 1;
BA_ "U_U55X_MY2022_Rx" SG_ 1146 TrlrAidCtl_U_RqDrv 1;
BA_ "U_CDX706_MY2023_Rx" SG_ 533 TjaLcEnbl_D_RqMnu 1;
BA_ "GenSigStartValue" SG_ 533 ExtLghtRvrseOn_B_Rq 1;
BA_ "U_U55X_MY2022_Rx" SG_ 533 ClrExitAsstEnbl_D_RqMnu 1;
BA_ "U_CDX706_MY2023_Rx" SG_ 533 ClrExitAsstEnbl_D_RqMnu 1;
BA_ "U_P702_MY2021_Rx" SG_ 533 TrlrAidMde_D_Rq 1;
BA_ "U_T6_MCA_MY2020_Rx" SG_ 533 TrlrAidMde_D_Rq 1;
BA_ "U_U55X_MY2022_Rx" SG_ 533 TrlrAidMde_D_Rq 1;
BA_ "U_CX727_MY2021_Rx" SG_ 533 OnbChrgGoTTouch_D_Rq 1;
BA_ "U_P702_MY2021_Rx" SG_ 533 OnbChrgGoTTouch_D_Rq 1;
BA_ "U_CD542_MY2021_Rx" SG_ 533 OnbChrgGoTTouch_D_Rq 1;
BA_ "U_CX727_MY2021_Rx" SG_ 533 OnbChrgGoTPrcond_D_Rq 1;
BA_ "U_P702_MY2021_Rx" SG_ 533 OnbChrgGoTPrcond_D_Rq 1;
BA_ "U_CD542_MY2021_Rx" SG_ 533 OnbChrgGoTPrcond_D_Rq 1;
BA_ "GenSigStartValueInteger" SG_ 533 OnbChrgGoTOn_D_Rq 2;
BA_ "GenSigStartValue" SG_ 533 OnbChrgGoTOn_D_Rq 2;
BA_ "U_CX727_MY2021_Rx" SG_ 533 OnbChrgGoTOn_D_Rq 1;
BA_ "U_P702_MY2021_Rx" SG_ 533 OnbChrgGoTOn_D_Rq 1;
BA_ "U_CD542_MY2021_Rx" SG_ 533 OnbChrgGoTOn_D_Rq 1;
BA_ "U_CX727_MY2021_Rx" SG_ 533 OnbChrgGoTMnte_D_Rq 1;
BA_ "U_P702_MY2021_Rx" SG_ 533 OnbChrgGoTMnte_D_Rq 1;
BA_ "U_CD542_MY2021_Rx" SG_ 533 OnbChrgGoTMnte_D_Rq 1;
BA_ "GenSigStartValueInteger" SG_ 533 OnbChrgGoTHr_T_Rq 30;
BA_ "GenSigStartValue" SG_ 533 OnbChrgGoTHr_T_Rq 30;
BA_ "U_CX727_MY2021_Rx" SG_ 533 OnbChrgGoTHr_T_Rq 1;
BA_ "U_P702_MY2021_Rx" SG_ 533 OnbChrgGoTHr_T_Rq 1;
BA_ "U_CD542_MY2021_Rx" SG_ 533 OnbChrgGoTHr_T_Rq 1;
BA_ "U_CX727_MY2021_Rx" SG_ 533 OnbChrgGoTExtHtr_D_Rq 1;
BA_ "U_P702_MY2021_Rx" SG_ 533 OnbChrgGoTExtHtr_D_Rq 1;
BA_ "U_CD542_MY2021_Rx" SG_ 533 OnbChrgGoTExtHtr_D_Rq 1;
BA_ "U_CX727_MY2021_Rx" SG_ 533 OnbChrgGoTElement_D_Rq 1;
BA_ "U_P702_MY2021_Rx" SG_ 533 OnbChrgGoTElement_D_Rq 1;
BA_ "U_CD542_MY2021_Rx" SG_ 533 OnbChrgGoTElement_D_Rq 1;
BA_ "U_CX727_MY2021_Rx" SG_ 533 OnbChrgGoTDelete_B_Rq 1;
BA_ "U_P702_MY2021_Rx" SG_ 533 OnbChrgGoTDelete_B_Rq 1;
BA_ "U_CD542_MY2021_Rx" SG_ 533 OnbChrgGoTDelete_B_Rq 1;
BA_ "U_CX727_MY2021_Rx" SG_ 533 OnbChrgClearAll_B_Rq 1;
BA_ "U_P702_MY2021_Rx" SG_ 533 OnbChrgClearAll_B_Rq 1;
BA_ "U_CD542_MY2021_Rx" SG_ 533 OnbChrgClearAll_B_Rq 1;
BA_ "U_T6_MCA_MY2020_Rx" SG_ 533 AutoEpbZoomView_B_Stat 1;
BA_ "U_U55X_MY2022_Rx" SG_ 533 AutoEpbZoomView_B_Stat 1;
BA_ "U_T6_MCA_MY2020_Rx" SG_ 533 AutoEpbButtn_B_Stat 1;
BA_ "U_U55X_MY2022_Rx" SG_ 533 AutoEpbButtn_B_Stat 1;
BA_ "U_CDX706_MY2023_Rx" SG_ 533 DcacPw_D_Rq 1;
BA_ "U_CDX706_MY2023_Rx" SG_ 533 DcacPwReset_B_Rq 1;
BA_ "WakeupSignal" SG_ 533 LghtAmbDrvMde_D_Rq 1;
BA_ "U_CDX706_MY2023_Rx" SG_ 533 DcacPwLoButtn_B_Stat 1;
BA_ "U_CDX706_MY2023_Rx" SG_ 533 DcacPwOffButtn_B_Stat 1;
BA_ "U_CDX706_MY2023_Rx" SG_ 533 DcacPwHiButtn_B_Stat 1;
BA_ "U_CDX706_MY2023_Rx" SG_ 533 DcacPwResetButtn_B_Stat 1;
BA_ "U_CDX706_MY2023_Rx" SG_ 533 DcacPwButtn_B_Falt 1;
BA_ "U_CX727_MY2021_Rx" SG_ 533 OnbChrgGoTUpdate_B_Rq 1;
BA_ "U_CD542_MY2021_Rx" SG_ 533 OnbChrgGoTUpdate_B_Rq 1;
BA_ "U_CDX706_MY2023_Rx" SG_ 533 DcacMdeButtn_B_Stat 1;
BA_ "U_CDX706_MY2023_Rx" SG_ 533 DcacGfciTestBttn_B_Stat 1;
BA_ "U_T6_MCA_MY2020_Rx" SG_ 533 TrlrHitch_D_RqMnu 1;
BA_ "U_CD542_MY2021_Rx" SG_ 533 TrlrHitch_D_RqMnu 1;
BA_ "U_U55X_MY2022_Rx" SG_ 533 TrlrHitch_D_RqMnu 1;
BA_ "U_CD764_MY2022_Rx" SG_ 533 TrlrHitch_D_RqMnu 1;
BA_ "U_CDX706_MY2023_Rx" SG_ 533 TrlrHitch_D_RqMnu 1;
BA_ "U_CDX706_MY2023_Rx" SG_ 533 DcacPwButtn_B_Stat 1;
BA_ "U_T6_MCA_MY2020_Rx" SG_ 778 PrkAidAcsyRear_D_RqDrv 1;
BA_ "U_CD542_MY2021_Rx" SG_ 778 PrkAidAcsyRear_D_RqDrv 1;
BA_ "U_U55X_MY2022_Rx" SG_ 778 PrkAidAcsyRear_D_RqDrv 1;
BA_ "U_CD764_MY2022_Rx" SG_ 778 PrkAidAcsyRear_D_RqDrv 1;
BA_ "U_CDX706_MY2023_Rx" SG_ 778 PrkAidAcsyRear_D_RqDrv 1;
BA_ "U_T6_MCA_MY2020_Rx" SG_ 778 PrkAidAcsyFront_D_RqDrv 1;
BA_ "U_CD542_MY2021_Rx" SG_ 778 PrkAidAcsyFront_D_RqDrv 1;
BA_ "U_U55X_MY2022_Rx" SG_ 778 PrkAidAcsyFront_D_RqDrv 1;
BA_ "U_CD764_MY2022_Rx" SG_ 778 PrkAidAcsyFront_D_RqDrv 1;
BA_ "U_CDX706_MY2023_Rx" SG_ 778 PrkAidAcsyFront_D_RqDrv 1;
BA_ "GenSigStartValueInteger" SG_ 778 Cta_D_Rq 1;
BA_ "GenSigStartValue" SG_ 778 Cta_D_Rq 1;
BA_ "U_T6_MCA_MY2020_Rx" SG_ 778 Cta_D_Rq 1;
BA_ "U_CD542_MY2021_Rx" SG_ 778 Cta_D_Rq 1;
BA_ "U_U55X_MY2022_Rx" SG_ 778 Cta_D_Rq 1;
BA_ "U_CD764_MY2022_Rx" SG_ 778 Cta_D_Rq 1;
BA_ "U_CDX706_MY2023_Rx" SG_ 778 Cta_D_Rq 1;
BA_ "U_T6_MCA_MY2020_Rx" SG_ 778 PrkAidRear_D_RqDrv 1;
BA_ "U_CD542_MY2021_Rx" SG_ 778 PrkAidRear_D_RqDrv 1;
BA_ "U_U55X_MY2022_Rx" SG_ 778 PrkAidRear_D_RqDrv 1;
BA_ "U_CD764_MY2022_Rx" SG_ 778 PrkAidRear_D_RqDrv 1;
BA_ "U_CDX706_MY2023_Rx" SG_ 778 PrkAidRear_D_RqDrv 1;
BA_ "U_T6_MCA_MY2020_Rx" SG_ 778 PrkAidFront_D_RqDrv 1;
BA_ "U_CD542_MY2021_Rx" SG_ 778 PrkAidFront_D_RqDrv 1;
BA_ "U_U55X_MY2022_Rx" SG_ 778 PrkAidFront_D_RqDrv 1;
BA_ "U_CD764_MY2022_Rx" SG_ 778 PrkAidFront_D_RqDrv 1;
BA_ "U_CDX706_MY2023_Rx" SG_ 778 PrkAidFront_D_RqDrv 1;
BA_ "GenSigStartValueInteger" SG_ 778 Sod_D_Rq 2;
BA_ "GenSigStartValue" SG_ 778 Sod_D_Rq 2;
BA_ "U_T6_MCA_MY2020_Rx" SG_ 778 Sod_D_Rq 1;
BA_ "U_CD542_MY2021_Rx" SG_ 778 Sod_D_Rq 1;
BA_ "U_U55X_MY2022_Rx" SG_ 778 Sod_D_Rq 1;
BA_ "U_CD764_MY2022_Rx" SG_ 778 Sod_D_Rq 1;
BA_ "U_CDX706_MY2023_Rx" SG_ 778 Sod_D_Rq 1;
BA_ "U_U55X_MY2022_Rx" SG_ 778 ClrExitAsstEnbl_D_RqDrv 1;
BA_ "U_CD764_MY2022_Rx" SG_ 778 ClrExitAsstEnbl_D_RqDrv 1;
BA_ "U_CDX706_MY2023_Rx" SG_ 778 ClrExitAsstEnbl_D_RqDrv 1;
BA_ "U_CX727_MY2021_Rx" SG_ 1041 ElCmprUHi_U_Actl 1;
BA_ "U_P702_MY2021_Rx" SG_ 1041 ElCmprUHi_U_Actl 1;
BA_ "U_CD542_MY2021_Rx" SG_ 1041 ElCmprUHi_U_Actl 1;
BA_ "U_CDX706_MY2023_Rx" SG_ 1041 ElCmprUHi_U_Actl 1;
BA_ "U_CX727_MY2021_Rx" SG_ 1041 ElCmprUHi_D_Stat 1;
BA_ "U_P702_MY2021_Rx" SG_ 1041 ElCmprUHi_D_Stat 1;
BA_ "U_CD542_MY2021_Rx" SG_ 1041 ElCmprUHi_D_Stat 1;
BA_ "U_CDX706_MY2023_Rx" SG_ 1041 ElCmprUHi_D_Stat 1;
BA_ "U_CX727_MY2021_Rx" SG_ 1041 ElCmprOverTe_D_Stat 1;
BA_ "U_P702_MY2021_Rx" SG_ 1041 ElCmprOverTe_D_Stat 1;
BA_ "U_CD542_MY2021_Rx" SG_ 1041 ElCmprOverTe_D_Stat 1;
BA_ "U_CDX706_MY2023_Rx" SG_ 1041 ElCmprOverTe_D_Stat 1;
BA_ "U_CX727_MY2021_Rx" SG_ 1041 ElCmpr_N_Actl 1;
BA_ "U_P702_MY2021_Rx" SG_ 1041 ElCmpr_N_Actl 1;
BA_ "U_CD542_MY2021_Rx" SG_ 1041 ElCmpr_N_Actl 1;
BA_ "U_CDX706_MY2023_Rx" SG_ 1041 ElCmpr_N_Actl 1;
BA_ "U_CX727_MY2021_Rx" SG_ 1041 ElCmpr_Pw_Actl 1;
BA_ "U_P702_MY2021_Rx" SG_ 1041 ElCmpr_Pw_Actl 1;
BA_ "U_CD542_MY2021_Rx" SG_ 1041 ElCmpr_Pw_Actl 1;
BA_ "U_CDX706_MY2023_Rx" SG_ 1041 ElCmpr_Pw_Actl 1;
BA_ "U_CX727_MY2021_Rx" SG_ 1041 ElCmpr_D_Stat 1;
BA_ "U_P702_MY2021_Rx" SG_ 1041 ElCmpr_D_Stat 1;
BA_ "U_CD542_MY2021_Rx" SG_ 1041 ElCmpr_D_Stat 1;
BA_ "U_CDX706_MY2023_Rx" SG_ 1041 ElCmpr_D_Stat 1;
BA_ "U_CX727_MY2021_Rx" SG_ 1041 ElCmprPerfErr_D_Falt 1;
BA_ "U_P702_MY2021_Rx" SG_ 1041 ElCmprPerfErr_D_Falt 1;
BA_ "U_CD542_MY2021_Rx" SG_ 1041 ElCmprPerfErr_D_Falt 1;
BA_ "U_CDX706_MY2023_Rx" SG_ 1041 ElCmprPerfErr_D_Falt 1;
BA_ "U_CX727_MY2021_Rx" SG_ 1041 ElCmprInnrErr_D_Falt 1;
BA_ "U_P702_MY2021_Rx" SG_ 1041 ElCmprInnrErr_D_Falt 1;
BA_ "U_CD542_MY2021_Rx" SG_ 1041 ElCmprInnrErr_D_Falt 1;
BA_ "U_CDX706_MY2023_Rx" SG_ 1041 ElCmprInnrErr_D_Falt 1;
BA_ "U_CX727_MY2021_Rx" SG_ 1041 ElCmprLostComm_D_Falt 1;
BA_ "U_P702_MY2021_Rx" SG_ 1041 ElCmprLostComm_D_Falt 1;
BA_ "U_CD542_MY2021_Rx" SG_ 1041 ElCmprLostComm_D_Falt 1;
BA_ "U_CDX706_MY2023_Rx" SG_ 1041 ElCmprLostComm_D_Falt 1;
BA_ "U_CX727_MY2021_Rx" SG_ 1041 ElCmprOverLoad_D_Falt 1;
BA_ "U_P702_MY2021_Rx" SG_ 1041 ElCmprOverLoad_D_Falt 1;
BA_ "U_CD542_MY2021_Rx" SG_ 1041 ElCmprOverLoad_D_Falt 1;
BA_ "U_CDX706_MY2023_Rx" SG_ 1041 ElCmprOverLoad_D_Falt 1;
BA_ "U_CX727_MY2021_Rx" SG_ 1041 ElCmprOverTe_D_Falt 1;
BA_ "U_P702_MY2021_Rx" SG_ 1041 ElCmprOverTe_D_Falt 1;
BA_ "U_CD542_MY2021_Rx" SG_ 1041 ElCmprOverTe_D_Falt 1;
BA_ "U_CDX706_MY2023_Rx" SG_ 1041 ElCmprOverTe_D_Falt 1;
BA_ "U_CX727_MY2021_Rx" SG_ 1041 ElCmprBattURng_D_Falt 1;
BA_ "U_P702_MY2021_Rx" SG_ 1041 ElCmprBattURng_D_Falt 1;
BA_ "U_CD542_MY2021_Rx" SG_ 1041 ElCmprBattURng_D_Falt 1;
BA_ "U_CDX706_MY2023_Rx" SG_ 1041 ElCmprBattURng_D_Falt 1;
BA_ "U_CX727_MY2021_Rx" SG_ 1041 ElCmprBattSysU_D_Falt 1;
BA_ "U_P702_MY2021_Rx" SG_ 1041 ElCmprBattSysU_D_Falt 1;
BA_ "U_CD542_MY2021_Rx" SG_ 1041 ElCmprBattSysU_D_Falt 1;
BA_ "U_CDX706_MY2023_Rx" SG_ 1041 ElCmprBattSysU_D_Falt 1;
BA_ "U_CX727_MY2021_Rx" SG_ 1041 ElCmprSysU_D_Falt 1;
BA_ "U_P702_MY2021_Rx" SG_ 1041 ElCmprSysU_D_Falt 1;
BA_ "U_CD542_MY2021_Rx" SG_ 1041 ElCmprSysU_D_Falt 1;
BA_ "U_CDX706_MY2023_Rx" SG_ 1041 ElCmprSysU_D_Falt 1;
BA_ "GenSigStartValue" SG_ 1067 BattULoAux_U_Rq 3296;
BA_ "U_P702_MY2021_Rx" SG_ 1067 BattULoAux_U_Rq 1;
BA_ "GenSigStartValueInteger" SG_ 1067 BattULoAuxIsol_D_Rq 2;
BA_ "GenSigStartValue" SG_ 1067 BattULoAuxIsol_D_Rq 2;
BA_ "U_P702_MY2021_Rx" SG_ 1067 BattULoAuxIsol_D_Rq 1;
BA_ "GenSigStartValueInteger" SG_ 1067 BattULoAuxSoc_Pc_Actl 95;
BA_ "GenSigStartValue" SG_ 1067 BattULoAuxSoc_Pc_Actl 95;
BA_ "U_P702_MY2021_Rx" SG_ 1067 BattULoAuxSoc_Pc_Actl 1;
BA_ "GenSigStartValueInteger" SG_ 1067 BattULoAux_I_Actl 2048;
BA_ "U_P702_MY2021_Rx" SG_ 1067 BattULoAux_I_Actl 1;
BA_ "U_P702_MY2021_Rx" SG_ 1067 BattULoAux_D_Qlty 1;
BA_ "U_P702_MY2021_Rx" SG_ 1067 BattULoCrnkStrt_U_Pred 1;
BA_ "U_P702_MY2021_Rx" SG_ 1067 BattULoCrnkBelt_U_Pred 1;
BA_ "GenSigStartValueInteger" SG_ 1067 BattULoAux_U_Actl 203;
BA_ "GenSigStartValue" SG_ 1067 BattULoAux_U_Actl 203;
BA_ "U_P702_MY2021_Rx" SG_ 1067 BattULoAux_U_Actl 1;
BA_ "U_P702_MY2021_Rx" SG_ 1067 BattULoAux_B_Falt 1;
BA_ "U_CX727_MY2021_Rx" SG_ 1118 ExtChrgNowButtn_B_Rq 1;
BA_ "U_CD542_MY2021_Rx" SG_ 1118 ExtChrgNowButtn_B_Rq 1;
BA_ "U_CX727_MY2021_Rx" SG_ 1118 CoolFanChrgr_D_Rq 1;
BA_ "U_CD542_MY2021_Rx" SG_ 1118 CoolFanChrgr_D_Rq 1;
BA_ "U_CX727_MY2021_Rx" SG_ 1118 ChrgrClntFlw_D_Rq 1;
BA_ "U_CD542_MY2021_Rx" SG_ 1118 ChrgrClntFlw_D_Rq 1;
BA_ "U_CX727_MY2021_Rx" SG_ 1118 PlgStatEvnt_B_Stat 1;
BA_ "U_CD542_MY2021_Rx" SG_ 1118 PlgStatEvnt_B_Stat 1;
BA_ "U_CX727_MY2021_Rx" SG_ 1118 ChrgrCnnctPwr_B_Stat 1;
BA_ "U_CD542_MY2021_Rx" SG_ 1118 ChrgrCnnctPwr_B_Stat 1;
BA_ "U_CX727_MY2021_Rx" SG_ 1118 ChrgrAvailEvnt_B_Stat 1;
BA_ "U_CD542_MY2021_Rx" SG_ 1118 ChrgrAvailEvnt_B_Stat 1;
BA_ "U_CX727_MY2021_Rx" SG_ 1118 ChrgChngEvnt_B_Stat 1;
BA_ "U_CD542_MY2021_Rx" SG_ 1118 ChrgChngEvnt_B_Stat 1;
BA_ "U_CX727_MY2021_Rx" SG_ 1118 ChrgCordLck_D_Stat 1;
BA_ "U_CD542_MY2021_Rx" SG_ 1118 ChrgCordLck_D_Stat 1;
BA_ "U_CX727_MY2021_Rx" SG_ 1118 ChrgrInPwMde_D_Actl 1;
BA_ "U_CD542_MY2021_Rx" SG_ 1118 ChrgrInPwMde_D_Actl 1;
BA_ "GenSigStartValueInteger" SG_ 1118 ChrgrPncEnbl_D_Stat 3;
BA_ "GenSigStartValue" SG_ 1118 ChrgrPncEnbl_D_Stat 3;
BA_ "GenSigStartValue" SG_ 1040 RoadGrd_Pc_Est 1023;
BA_ "ECGUsedRxSignal" SG_ 1040 RoadGrd_Pc_Est 1;
BA_ "U_CDX706_MY2023_Rx" SG_ 1040 RoadGrd_Pc_Est 1;
BA_ "GenSigStartValue" SG_ 1040 VehSimSnd_Pc_Rq 511;
BA_ "U_CDX706_MY2023_Tx" SG_ 1040 VehSimSnd_Pc_Rq 1;
BA_ "U_CX727_MY2021_Rx" SG_ 1040 ElCmprEnbl_B_Rq 1;
BA_ "U_P702_MY2021_Rx" SG_ 1040 ElCmprEnbl_B_Rq 1;
BA_ "U_CD542_MY2021_Rx" SG_ 1040 ElCmprEnbl_B_Rq 1;
BA_ "U_CDX706_MY2023_Rx" SG_ 1040 ElCmprEnbl_B_Rq 1;
BA_ "U_CX727_MY2021_Tx" SG_ 1040 ElCmprEnbl_B_Rq 1;
BA_ "U_P702_MY2021_Tx" SG_ 1040 ElCmprEnbl_B_Rq 1;
BA_ "U_CD542_MY2021_Tx" SG_ 1040 ElCmprEnbl_B_Rq 1;
BA_ "U_CDX706_MY2023_Tx" SG_ 1040 ElCmprEnbl_B_Rq 1;
BA_ "U_CX727_MY2021_Tx" SG_ 1040 ElCmpr_N_Rq 1;
BA_ "U_P702_MY2021_Tx" SG_ 1040 ElCmpr_N_Rq 1;
BA_ "U_CD542_MY2021_Tx" SG_ 1040 ElCmpr_N_Rq 1;
BA_ "U_CDX706_MY2023_Tx" SG_ 1040 ElCmpr_N_Rq 1;
BA_ "GenSigStartValueInteger" SG_ 1040 BattTrac_I2_EstVsc 15000;
BA_ "GenSigStartValue" SG_ 1040 BattTrac_I2_EstVsc 262142;
BA_ "U_CDX706_MY2023_Tx" SG_ 1040 BattTrac_I2_EstVsc 1;
BA_ "GenSigSendType" SG_ 1144 AwdLckMde_D_Stat 3;
BA_ "GenSigSendType" SG_ 1144 BattTracCool_B_Actl 3;
BA_ "U_CDX706_MY2023_Tx" SG_ 1144 BattTracCool_B_Actl 1;
BA_ "U_CX727_MY2021_Tx" SG_ 1144 BattChrgTrgtSoC_D_Rq 1;
BA_ "U_P702_MY2021_Tx" SG_ 1144 BattChrgTrgtSoC_D_Rq 1;
BA_ "U_CD542_MY2021_Tx" SG_ 1144 BattChrgTrgtSoC_D_Rq 1;
BA_ "GenSigSendType" SG_ 1144 CabnEvapSovFront_B_Rq 3;
BA_ "WakeupSignal" SG_ 1144 CabnEvapSovFront_B_Rq 1;
BA_ "U_CX727_MY2021_Tx" SG_ 1144 CabnEvapSovFront_B_Rq 1;
BA_ "U_P702_MY2021_Tx" SG_ 1144 CabnEvapSovFront_B_Rq 1;
BA_ "U_CD542_MY2021_Tx" SG_ 1144 CabnEvapSovFront_B_Rq 1;
BA_ "U_CDX706_MY2023_Tx" SG_ 1144 CabnEvapSovFront_B_Rq 1;
BA_ "GenSigSendType" SG_ 1144 HeatCoreSovRear_B_Rq 3;
BA_ "WakeupSignal" SG_ 1144 HeatCoreSovRear_B_Rq 1;
BA_ "U_CX727_MY2021_Tx" SG_ 1144 HeatCoreSovRear_B_Rq 1;
BA_ "U_P702_MY2021_Tx" SG_ 1144 HeatCoreSovRear_B_Rq 1;
BA_ "U_CD542_MY2021_Tx" SG_ 1144 HeatCoreSovRear_B_Rq 1;
BA_ "GenSigSendType" SG_ 1144 BattChlrSov_B_Rq 3;
BA_ "WakeupSignal" SG_ 1144 BattChlrSov_B_Rq 1;
BA_ "U_CX727_MY2021_Tx" SG_ 1144 BattChlrSov_B_Rq 1;
BA_ "U_P702_MY2021_Tx" SG_ 1144 BattChlrSov_B_Rq 1;
BA_ "U_CD542_MY2021_Tx" SG_ 1144 BattChlrSov_B_Rq 1;
BA_ "U_CDX706_MY2023_Tx" SG_ 1144 BattChlrSov_B_Rq 1;
BA_ "GenSigSendType" SG_ 1144 CabnEvapSovRear_B_Rq 3;
BA_ "WakeupSignal" SG_ 1144 CabnEvapSovRear_B_Rq 1;
BA_ "U_CX727_MY2021_Tx" SG_ 1144 CabnEvapSovRear_B_Rq 1;
BA_ "U_P702_MY2021_Tx" SG_ 1144 CabnEvapSovRear_B_Rq 1;
BA_ "U_CD542_MY2021_Tx" SG_ 1144 CabnEvapSovRear_B_Rq 1;
BA_ "U_CDX706_MY2023_Tx" SG_ 1144 CabnEvapSovRear_B_Rq 1;
BA_ "GenSigSendType" SG_ 1144 BrkAppl_D_RqPt 3;
BA_ "U_CX727_MY2021_Rx" SG_ 1144 BrkAppl_D_RqPt 1;
BA_ "U_CD542_MY2021_Rx" SG_ 1144 BrkAppl_D_RqPt 1;
BA_ "U_CD764_MY2022_Rx" SG_ 1144 BrkAppl_D_RqPt 1;
BA_ "U_CX727_MY2021_Tx" SG_ 1144 BrkAppl_D_RqPt 1;
BA_ "U_P702_MY2021_Tx" SG_ 1144 BrkAppl_D_RqPt 1;
BA_ "U_CD542_MY2021_Tx" SG_ 1144 BrkAppl_D_RqPt 1;
BA_ "U_CDX706_MY2023_Tx" SG_ 1144 BrkAppl_D_RqPt 1;
BA_ "GenSigSendType" SG_ 1144 BattClntVlvOvrrd_D_Rq 3;
BA_ "U_CX727_MY2021_Tx" SG_ 1144 BattClntVlvOvrrd_D_Rq 1;
BA_ "U_CD542_MY2021_Tx" SG_ 1144 BattClntVlvOvrrd_D_Rq 1;
BA_ "U_CDX706_MY2023_Tx" SG_ 1144 BattClntVlvOvrrd_D_Rq 1;
BA_ "GenSigSendType" SG_ 1144 BattTracChillerOn_B_Rq 3;
BA_ "U_CX727_MY2021_Tx" SG_ 1144 BattTracChillerOn_B_Rq 1;
BA_ "U_CD542_MY2021_Tx" SG_ 1144 BattTracChillerOn_B_Rq 1;
BA_ "U_CDX706_MY2023_Tx" SG_ 1144 BattTracChillerOn_B_Rq 1;
BA_ "GenSigSendType" SG_ 1144 BattTracChiller_D_Stat 3;
BA_ "U_CX727_MY2021_Tx" SG_ 1144 BattTracChiller_D_Stat 1;
BA_ "U_CD542_MY2021_Tx" SG_ 1144 BattTracChiller_D_Stat 1;
BA_ "U_CDX706_MY2023_Tx" SG_ 1144 BattTracChiller_D_Stat 1;
BA_ "GenSigSendType" SG_ 1144 HtrnDcdcDis_B_Rq 3;
BA_ "U_CX727_MY2021_Rx" SG_ 1144 HtrnDcdcDis_B_Rq 1;
BA_ "U_CD542_MY2021_Rx" SG_ 1144 HtrnDcdcDis_B_Rq 1;
BA_ "U_CDX706_MY2023_Rx" SG_ 1144 HtrnDcdcDis_B_Rq 1;
BA_ "U_CX727_MY2021_Tx" SG_ 1144 HtrnDcdcDis_B_Rq 1;
BA_ "U_CD542_MY2021_Tx" SG_ 1144 HtrnDcdcDis_B_Rq 1;
BA_ "GenSigSendType" SG_ 1144 HtrnCnnctPwr_B_Stat 3;
BA_ "U_CX727_MY2021_Tx" SG_ 1144 HtrnCnnctPwr_B_Stat 1;
BA_ "U_P702_MY2021_Tx" SG_ 1144 HtrnCnnctPwr_B_Stat 1;
BA_ "U_CD542_MY2021_Tx" SG_ 1144 HtrnCnnctPwr_B_Stat 1;
BA_ "GenSigSendType" SG_ 1144 PtcHtr_D_Stat 3;
BA_ "U_CX727_MY2021_Rx" SG_ 1144 PtcHtr_D_Stat 1;
BA_ "U_P702_MY2021_Rx" SG_ 1144 PtcHtr_D_Stat 1;
BA_ "U_CD542_MY2021_Rx" SG_ 1144 PtcHtr_D_Stat 1;
BA_ "U_CDX706_MY2023_Rx" SG_ 1144 PtcHtr_D_Stat 1;
BA_ "U_CX727_MY2021_Tx" SG_ 1144 PtcHtr_D_Stat 1;
BA_ "U_P702_MY2021_Tx" SG_ 1144 PtcHtr_D_Stat 1;
BA_ "U_CD542_MY2021_Tx" SG_ 1144 PtcHtr_D_Stat 1;
BA_ "GenSigSendType" SG_ 1144 WakeAlarm0_B_Typ 3;
BA_ "U_CX727_MY2021_Tx" SG_ 1144 WakeAlarm0_B_Typ 1;
BA_ "U_CD542_MY2021_Tx" SG_ 1144 WakeAlarm0_B_Typ 1;
BA_ "GenSigStartValueInteger" SG_ 1144 WakeAlarm0_T_Rq 32767;
BA_ "GenSigStartValue" SG_ 1144 WakeAlarm0_T_Rq 32767;
BA_ "U_CX727_MY2021_Tx" SG_ 1144 WakeAlarm0_T_Rq 1;
BA_ "U_CD542_MY2021_Tx" SG_ 1144 WakeAlarm0_T_Rq 1;
BA_ "GenSigSendType" SG_ 1144 HtrnClntFlw_D_Rq 3;
BA_ "U_CX727_MY2021_Tx" SG_ 1144 HtrnClntFlw_D_Rq 1;
BA_ "U_P702_MY2021_Tx" SG_ 1144 HtrnClntFlw_D_Rq 1;
BA_ "U_CD542_MY2021_Tx" SG_ 1144 HtrnClntFlw_D_Rq 1;
BA_ "U_CDX706_MY2023_Tx" SG_ 1144 HtrnClntFlw_D_Rq 1;
BA_ "GenSigSendType" SG_ 1144 BattTracDrvSustn_B_Rq 3;
BA_ "U_CX727_MY2021_Rx" SG_ 1144 BattTracDrvSustn_B_Rq 1;
BA_ "U_CD542_MY2021_Rx" SG_ 1144 BattTracDrvSustn_B_Rq 1;
BA_ "U_CDX706_MY2023_Rx" SG_ 1144 BattTracDrvSustn_B_Rq 1;
BA_ "U_CX727_MY2021_Tx" SG_ 1144 BattTracDrvSustn_B_Rq 1;
BA_ "U_P702_MY2021_Tx" SG_ 1144 BattTracDrvSustn_B_Rq 1;
BA_ "U_CD542_MY2021_Tx" SG_ 1144 BattTracDrvSustn_B_Rq 1;
BA_ "U_CDX706_MY2023_Tx" SG_ 1144 BattTracDrvSustn_B_Rq 1;
BA_ "GenSigSendType" SG_ 1144 CabinDrvSustn_B_Rq 3;
BA_ "U_CX727_MY2021_Rx" SG_ 1144 CabinDrvSustn_B_Rq 1;
BA_ "U_CD542_MY2021_Rx" SG_ 1144 CabinDrvSustn_B_Rq 1;
BA_ "U_CDX706_MY2023_Rx" SG_ 1144 CabinDrvSustn_B_Rq 1;
BA_ "U_CX727_MY2021_Tx" SG_ 1144 CabinDrvSustn_B_Rq 1;
BA_ "U_CD542_MY2021_Tx" SG_ 1144 CabinDrvSustn_B_Rq 1;
BA_ "U_CDX706_MY2023_Tx" SG_ 1144 CabinDrvSustn_B_Rq 1;
BA_ "GenSigSendType" SG_ 1144 ChrgNowEvnt_B_Stat 3;
BA_ "U_CDX706_MY2023_Rx" SG_ 1144 ChrgNowEvnt_B_Stat 1;
BA_ "U_CX727_MY2021_Tx" SG_ 1144 ChrgNowEvnt_B_Stat 1;
BA_ "U_CD542_MY2021_Tx" SG_ 1144 ChrgNowEvnt_B_Stat 1;
BA_ "GenSigSendType" SG_ 1144 PreCondBatt_B_Actl 3;
BA_ "U_CDX706_MY2023_Rx" SG_ 1144 PreCondBatt_B_Actl 1;
BA_ "U_CX727_MY2021_Tx" SG_ 1144 PreCondBatt_B_Actl 1;
BA_ "U_CD542_MY2021_Tx" SG_ 1144 PreCondBatt_B_Actl 1;
BA_ "GenSigSendType" SG_ 1144 BattTracClntVlv_B_Rq 3;
BA_ "U_CX727_MY2021_Tx" SG_ 1144 BattTracClntVlv_B_Rq 1;
BA_ "U_P702_MY2021_Tx" SG_ 1144 BattTracClntVlv_B_Rq 1;
BA_ "U_CD542_MY2021_Tx" SG_ 1144 BattTracClntVlv_B_Rq 1;
BA_ "U_CDX706_MY2023_Tx" SG_ 1144 BattTracClntVlv_B_Rq 1;
BA_ "ECGUsedRxSignal" SG_ 1144 FstChrgCmplt_T_Est 1;
BA_ "U_CD542_MY2021_Rx" SG_ 1144 FstChrgCmplt_T_Est 1;
BA_ "U_U55X_MY2022_Rx" SG_ 1144 FstChrgCmplt_T_Est 1;
BA_ "U_CDX706_MY2023_Rx" SG_ 1144 FstChrgCmplt_T_Est 1;
BA_ "GenSigSendType" SG_ 1144 ULoBattTrnsfrSustn_B_Rq 3;
BA_ "ECGUsedRxSignal" SG_ 1144 ULoBattTrnsfrSustn_B_Rq 1;
BA_ "U_CD542_MY2021_Rx" SG_ 1144 ULoBattTrnsfrSustn_B_Rq 1;
BA_ "U_U55X_MY2022_Rx" SG_ 1144 ULoBattTrnsfrSustn_B_Rq 1;
BA_ "U_CDX706_MY2023_Rx" SG_ 1144 ULoBattTrnsfrSustn_B_Rq 1;
BA_ "U_CD542_MY2021_Tx" SG_ 1144 ULoBattTrnsfrSustn_B_Rq 1;
BA_ "GenSigSendType" SG_ 1144 ULoBattTransfer_D_Stat 3;
BA_ "ECGUsedRxSignal" SG_ 1144 ULoBattTransfer_D_Stat 1;
BA_ "U_CD542_MY2021_Rx" SG_ 1144 ULoBattTransfer_D_Stat 1;
BA_ "U_U55X_MY2022_Rx" SG_ 1144 ULoBattTransfer_D_Stat 1;
BA_ "U_CDX706_MY2023_Rx" SG_ 1144 ULoBattTransfer_D_Stat 1;
BA_ "U_CD542_MY2021_Tx" SG_ 1144 ULoBattTransfer_D_Stat 1;
BA_ "GenSigSendType" SG_ 1144 BattChrgInhbt_D2_Rq 3;
BA_ "GenSigStartValue" SG_ 1144 BattChrgInhbt_D2_Rq 1;
BA_ "GenSigSendType" SG_ 1144 BattTracClimtDis_B_Stat 3;
BA_ "U_CDX706_MY2023_Tx" SG_ 1144 BattTracClimtDis_B_Stat 1;
BA_ "U_CX727_MY2021_Rx" SG_ 1112 BattTrac2_E_Avail 1;
BA_ "U_CD542_MY2021_Rx" SG_ 1112 BattTrac2_E_Avail 1;
BA_ "U_CX727_MY2021_Rx" SG_ 1112 BattTracCnnct_D_Cmd 1;
BA_ "U_P702_MY2021_Rx" SG_ 1112 BattTracCnnct_D_Cmd 1;
BA_ "U_CD542_MY2021_Rx" SG_ 1112 BattTracCnnct_D_Cmd 1;
BA_ "U_CDX706_MY2023_Rx" SG_ 1112 BattTracCnnct_D_Cmd 1;
BA_ "U_CX727_MY2021_Rx" SG_ 1112 BattTracHvilOpen_B_Stat 1;
BA_ "U_P702_MY2021_Rx" SG_ 1112 BattTracHvilOpen_B_Stat 1;
BA_ "U_CD542_MY2021_Rx" SG_ 1112 BattTracHvilOpen_B_Stat 1;
BA_ "U_CDX706_MY2023_Rx" SG_ 1112 BattTracHvilOpen_B_Stat 1;
BA_ "U_CDX706_MY2023_Rx" SG_ 1112 BattTracCoolLvl_D_Rq 1;
BA_ "U_CX727_MY2021_Rx" SG_ 1112 BattTracTeSustn_B_Rq 1;
BA_ "U_CDX706_MY2023_Rx" SG_ 1112 BattTracTeSustn_B_Rq 1;
BA_ "U_CX727_MY2021_Rx" SG_ 1112 BattTracTeEvnt_B_Stat 1;
BA_ "U_CD542_MY2021_Rx" SG_ 1112 BattTracTeEvnt_B_Stat 1;
BA_ "U_CDX706_MY2023_Rx" SG_ 1112 BattTracTeEvnt_B_Stat 1;
BA_ "U_CX727_MY2021_Rx" SG_ 1112 BattTracDcdcDis_B_Rq 1;
BA_ "U_P702_MY2021_Rx" SG_ 1112 BattTracDcdcDis_B_Rq 1;
BA_ "U_CD542_MY2021_Rx" SG_ 1112 BattTracDcdcDis_B_Rq 1;
BA_ "U_CDX706_MY2023_Rx" SG_ 1112 BattTracDcdcDis_B_Rq 1;
BA_ "U_CX727_MY2021_Rx" SG_ 1112 BattChrgTrgtEvnt_B_Stat 1;
BA_ "U_CD542_MY2021_Rx" SG_ 1112 BattChrgTrgtEvnt_B_Stat 1;
BA_ "U_CDX706_MY2023_Rx" SG_ 1112 BattChrgTrgtEvnt_B_Stat 1;
BA_ "U_CX727_MY2021_Rx" SG_ 1112 BattTracChrgSustn_B_Rq 1;
BA_ "U_CD542_MY2021_Rx" SG_ 1112 BattTracChrgSustn_B_Rq 1;
BA_ "U_CDX706_MY2023_Rx" SG_ 1112 BattTracChrgSustn_B_Rq 1;
BA_ "U_CX727_MY2021_Rx" SG_ 1112 HtrnClntPump_D_Stat 1;
BA_ "U_P702_MY2021_Rx" SG_ 1112 HtrnClntPump_D_Stat 1;
BA_ "U_CD542_MY2021_Rx" SG_ 1112 HtrnClntPump_D_Stat 1;
BA_ "U_CDX706_MY2023_Rx" SG_ 1112 HtrnClntPump_D_Stat 1;
BA_ "GenSigStartValueInteger" SG_ 1112 BattTrac2_E_Max 4094;
BA_ "GenSigStartValue" SG_ 1112 BattTrac2_E_Max 4094;
BA_ "U_CX727_MY2021_Rx" SG_ 1112 BattTrac2_E_Max 1;
BA_ "U_CDX706_MY2023_Rx" SG_ 1112 BattTracHeat_D_Rq 1;
BA_ "U_CX727_MY2021_Rx" SG_ 1112 BattTracDcFstSustn_B_Rq 1;
BA_ "U_CD542_MY2021_Rx" SG_ 1112 BattTracDiagClr_B_Rq 1;
BA_ "U_CDX706_MY2023_Rx" SG_ 1112 BattTracDiagClr_B_Rq 1;
BA_ "U_CDX706_MY2023_Rx" SG_ 1112 BattTracHazrd_D_Stat 1;
BA_ "GenSigStartValueInteger" SG_ 1112 BattTracDelta_Te_Actl 164;
BA_ "GenSigStartValue" SG_ 1112 BattTracDelta_Te_Actl 254;
BA_ "U_CX727_MY2021_Rx" SG_ 1112 BattTracDelta_Te_Actl 1;
BA_ "U_P702_MY2021_Rx" SG_ 1112 BattTracDelta_Te_Actl 1;
BA_ "U_CD542_MY2021_Rx" SG_ 1112 BattTracDelta_Te_Actl 1;
BA_ "U_CDX706_MY2023_Rx" SG_ 1112 BattTracDelta_Te_Actl 1;
BA_ "ContentDependant" SG_ 1112 BattTracClntPmp_D_Stat 1;
BA_ "U_CX727_MY2021_Rx" SG_ 1112 BattTracClntPmp_D_Stat 1;
BA_ "U_P702_MY2021_Rx" SG_ 1112 BattTracClntPmp_D_Stat 1;
BA_ "U_CD542_MY2021_Rx" SG_ 1112 BattTracClntPmp_D_Stat 1;
BA_ "U_CDX706_MY2023_Rx" SG_ 1112 BattTracClntPmp_D_Stat 1;
BA_ "U_P702_MY2021_Rx" SG_ 139 ActvFrontSteLck_D_Stat 1;
BA_ "U_T6_MCA_MY2020_Rx" SG_ 139 ActvFrontSteLck_D_Stat 1;
BA_ "U_CDX706_MY2023_Rx" SG_ 139 ActvFrontSteLck_D_Stat 1;
BA_ "U_P702_MY2021_Rx" SG_ 139 SelDrvMdeAdptSte_D_Stat 1;
BA_ "U_U55X_MY2022_Rx" SG_ 139 SelDrvMdeAdptSte_D_Stat 1;
BA_ "U_P702_MY2021_Rx" SG_ 139 AfsPw_B_Rq 1;
BA_ "U_T6_MCA_MY2020_Rx" SG_ 139 AfsPw_B_Rq 1;
BA_ "U_CDX706_MY2023_Rx" SG_ 139 AfsPw_B_Rq 1;
BA_ "GenSigStartValue" SG_ 1121 OffRdSwtch_D_RqMnu 2;
BA_ "U_CX727_MY2021_Rx" SG_ 1121 SelDrvMdeSwtchOk_D_Stat 1;
BA_ "U_CX727_MY2021_Rx" SG_ 1121 AutoHoldSwtch_D_Stat2 1;
BA_ "U_T6_MCA_MY2020_Rx" SG_ 1121 AutoHoldSwtch_D_Stat2 1;
BA_ "U_U55X_MY2022_Rx" SG_ 1121 AutoHoldSwtch_D_Stat2 1;
BA_ "U_CDX706_MY2023_Rx" SG_ 1121 PrkAidSwtch_D_RqDrv3 1;
BA_ "U_T6_MCA_MY2020_Rx" SG_ 1121 StopStrtDrvMde_B_RqBtn2 1;
BA_ "U_CX727_MY2021_Rx" SG_ 1121 SelDrvMdeSwtch_No_Actl 1;
BA_ "U_P702_MY2021_Rx" SG_ 1121 SelDrvMdeSwtch_No_Actl 1;
BA_ "U_T6_MCA_MY2020_Rx" SG_ 1121 SelDrvMdeSwtch_No_Actl 1;
BA_ "U_U55X_MY2022_Rx" SG_ 1121 SelDrvMdeSwtch_No_Actl 1;
BA_ "U_CX727_MY2021_Rx" SG_ 1121 SelDrvMdeSwtch_D_Stat 1;
BA_ "U_P702_MY2021_Rx" SG_ 1121 SelDrvMdeSwtch_D_Stat 1;
BA_ "U_T6_MCA_MY2020_Rx" SG_ 1121 SelDrvMdeSwtch_D_Stat 1;
BA_ "U_U55X_MY2022_Rx" SG_ 1121 SelDrvMdeSwtch_D_Stat 1;
BA_ "U_CDX706_MY2023_Rx" SG_ 1121 SelDrvMdeSwtch_D_Stat 1;
BA_ "U_CX727_MY2021_Rx" SG_ 1121 SelDrvMdeCnt_D_Stat 1;
BA_ "U_P702_MY2021_Rx" SG_ 1121 SelDrvMdeCnt_D_Stat 1;
BA_ "U_T6_MCA_MY2020_Rx" SG_ 1121 SelDrvMdeCnt_D_Stat 1;
BA_ "U_U55X_MY2022_Rx" SG_ 1121 SelDrvMdeCnt_D_Stat 1;
BA_ "U_T6_MCA_MY2020_Rx" SG_ 1120 StabBarCnncButtn_D_Stat 1;
BA_ "U_P702_MY2021_Rx" SG_ 1120 DrvSlipCtlMde_B_Rq3 1;
BA_ "U_T6_MCA_MY2020_Rx" SG_ 1120 DrvSlipCtlMde_B_Rq3 1;
BA_ "U_U55X_MY2022_Rx" SG_ 1120 DrvSlipCtlMde_B_Rq3 1;
BA_ "U_P702_MY2021_Rx" SG_ 1120 HybMdeSwtch_B_Rq 1;
BA_ "GenSigStartValueInteger" SG_ 1120 AwdLck_D_RqDrv 2;
BA_ "GenSigStartValue" SG_ 1120 AwdLck_D_RqDrv 2;
BA_ "U_T6_MCA_MY2020_Rx" SG_ 1120 TrailCtlSwtch_B_Stat3 1;
BA_ "GenSigStartValueInteger" SG_ 1120 RearDiffLck_D_RqDrv 2;
BA_ "GenSigStartValue" SG_ 1120 RearDiffLck_D_RqDrv 2;
BA_ "U_P702_MY2021_Rx" SG_ 1120 RearDiffLck_D_RqDrv 1;
BA_ "U_T6_MCA_MY2020_Rx" SG_ 1120 RearDiffLck_D_RqDrv 1;
BA_ "U_U55X_MY2022_Rx" SG_ 1120 RearDiffLck_D_RqDrv 1;
BA_ "GenSigStartValueInteger" SG_ 1120 AwdMde_D_RqDrv 5;
BA_ "GenSigStartValue" SG_ 1120 AwdMde_D_RqDrv 5;
BA_ "U_P702_MY2021_Rx" SG_ 1120 AwdMde_D_RqDrv 1;
BA_ "U_T6_MCA_MY2020_Rx" SG_ 1120 AwdMde_D_RqDrv 1;
BA_ "U_U55X_MY2022_Rx" SG_ 1120 AwdMde_D_RqDrv 1;
BA_ "U_P702_MY2021_Rx" SG_ 1120 HdcSwtchPos_B_Actl 1;
BA_ "U_T6_MCA_MY2020_Rx" SG_ 1120 HdcSwtchPos_B_Actl 1;
BA_ "U_U55X_MY2022_Rx" SG_ 1120 HdcSwtchPos_B_Actl 1;
BA_ "GenSigStartValueInteger" SG_ 1120 FrontDiffLck_D_RqDrv 2;
BA_ "GenSigStartValue" SG_ 1120 FrontDiffLck_D_RqDrv 2;
BA_ "U_T6_MCA_MY2020_Rx" SG_ 1120 FrontDiffLck_D_RqDrv 1;
BA_ "GenSigStartValueInteger" SG_ 1050 RearDiffLck_D_RqDrv4 2;
BA_ "GenSigStartValue" SG_ 1050 RearDiffLck_D_RqDrv4 2;
BA_ "U_CX727_MY2021_Rx" SG_ 1050 TrailCtlSwtch_B_Stat 1;
BA_ "U_CX727_MY2021_Rx" SG_ 1050 AutoHoldSwtch_D_Stat 1;
BA_ "U_P702_MY2021_Rx" SG_ 1050 AutoHoldSwtch_D_Stat 1;
BA_ "U_CD542_MY2021_Rx" SG_ 1050 AutoHoldSwtch_D_Stat 1;
BA_ "U_U55X_MY2022_Rx" SG_ 1050 AutoHoldSwtch_D_Stat 1;
BA_ "U_CD764_MY2022_Rx" SG_ 1050 AutoHoldSwtch_D_Stat 1;
BA_ "WakeupSignal" SG_ 1050 GlvBoxRleas_No_Actl 1;
BA_ "U_CX727_MY2021_Rx" SG_ 1050 DrvSlipCtlMde_B_Rq 1;
BA_ "U_T6_MCA_MY2020_Rx" SG_ 1050 DrvSlipCtlMde_B_Rq 1;
BA_ "U_U55X_MY2022_Rx" SG_ 1050 DrvSlipCtlMde_B_Rq 1;
BA_ "GenSigStartValueInteger" SG_ 1050 Outside_Air_Temp_Stat 254;
BA_ "GenSigStartValue" SG_ 1050 Outside_Air_Temp_Stat 254;
BA_ "U_CX727_MY2021_Rx" SG_ 1050 Outside_Air_Temp_Stat 1;
BA_ "U_P702_MY2021_Rx" SG_ 1050 Outside_Air_Temp_Stat 1;
BA_ "U_T6_MCA_MY2020_Rx" SG_ 1050 Outside_Air_Temp_Stat 1;
BA_ "U_CD542_MY2021_Rx" SG_ 1050 Outside_Air_Temp_Stat 1;
BA_ "U_U55X_MY2022_Rx" SG_ 1050 Outside_Air_Temp_Stat 1;
BA_ "U_CD764_MY2022_Rx" SG_ 1050 Outside_Air_Temp_Stat 1;
BA_ "U_CDX706_MY2023_Rx" SG_ 1050 Outside_Air_Temp_Stat 1;
BA_ "GenSigStartValue" SG_ 1050 CabnAmb_Te2_Actl 84;
BA_ "U_CDX706_MY2023_Rx" SG_ 1050 CamraFrntBttn_D_Stat 1;
BA_ "U_U55X_MY2022_Rx" SG_ 621 RmtCtlSelSlot_D_Rq 1;
BA_ "U_CDX706_MY2023_Rx" SG_ 621 RmtCtlSelSlot_D_Rq 1;
BA_ "U_U55X_MY2022_Rx" SG_ 621 RmtCtlSelPrkMde_D_Rq 1;
BA_ "U_CDX706_MY2023_Rx" SG_ 621 RmtCtlSelPrkMde_D_Rq 1;
BA_ "U_U55X_MY2022_Rx" SG_ 621 RmtCtlSelMoveDir_D_Rq 1;
BA_ "U_CDX706_MY2023_Rx" SG_ 621 RmtCtlSelMoveDir_D_Rq 1;
BA_ "U_U55X_MY2022_Rx" SG_ 621 RmtCtlRjctAutoCfg_B_Rq 1;
BA_ "U_CDX706_MY2023_Rx" SG_ 621 RmtCtlRjctAutoCfg_B_Rq 1;
BA_ "U_T6_MCA_MY2020_Rx" SG_ 1124 GPS_Vdop 1;
BA_ "U_CDX706_MY2023_Rx" SG_ 1124 GPS_Vdop 1;
BA_ "U_CX727_MY2021_Rx" SG_ 1124 GPS_Sat_num_in_view 1;
BA_ "U_P702_MY2021_Rx" SG_ 1124 GPS_Sat_num_in_view 1;
BA_ "U_CD542_MY2021_Rx" SG_ 1124 GPS_Sat_num_in_view 1;
BA_ "U_T6_MCA_MY2020_Rx" SG_ 1124 GPS_Heading 1;
BA_ "U_CD542_MY2021_Rx" SG_ 1124 GPS_Heading 1;
BA_ "U_CD764_MY2022_Rx" SG_ 1124 GPS_Heading 1;
BA_ "U_CDX706_MY2023_Rx" SG_ 1124 GPS_Heading 1;
BA_ "U_T6_MCA_MY2020_Rx" SG_ 1124 GPS_Hdop 1;
BA_ "U_CDX706_MY2023_Rx" SG_ 1124 GPS_Hdop 1;
BA_ "U_CX727_MY2021_Rx" SG_ 1124 GPS_dimension 1;
BA_ "U_P702_MY2021_Rx" SG_ 1124 GPS_dimension 1;
BA_ "U_CD542_MY2021_Rx" SG_ 1124 GPS_dimension 1;
BA_ "GenSigStartValueInteger" SG_ 1137 RngPerChrgLbl_L_Dsply 4094;
BA_ "GenSigStartValue" SG_ 1137 RngPerChrgLbl_L_Dsply 4093;
BA_ "U_CX727_MY2021_Tx" SG_ 1137 RngPerChrgLbl_L_Dsply 1;
BA_ "U_CD542_MY2021_Tx" SG_ 1137 RngPerChrgLbl_L_Dsply 1;
BA_ "GenSigStartValueInteger" SG_ 1137 RngPerChrgAvg_L_Dsply 4094;
BA_ "GenSigStartValue" SG_ 1137 RngPerChrgAvg_L_Dsply 4093;
BA_ "U_CX727_MY2021_Tx" SG_ 1137 RngPerChrgAvg_L_Dsply 1;
BA_ "U_P702_MY2021_Tx" SG_ 1137 RngPerChrgAvg_L_Dsply 1;
BA_ "U_CD542_MY2021_Tx" SG_ 1137 RngPerChrgAvg_L_Dsply 1;
BA_ "GenSigStartValueInteger" SG_ 1137 RngImpctTot_Pc_Dsply 1023;
BA_ "GenSigStartValue" SG_ 1137 RngImpctTot_Pc_Dsply 1022;
BA_ "U_CX727_MY2021_Tx" SG_ 1137 RngImpctTot_Pc_Dsply 1;
BA_ "U_CD542_MY2021_Tx" SG_ 1137 RngImpctTot_Pc_Dsply 1;
BA_ "GenSigStartValueInteger" SG_ 1137 RngImpctExt_Pc_Dsply 1023;
BA_ "GenSigStartValue" SG_ 1137 RngImpctExt_Pc_Dsply 1022;
BA_ "U_CX727_MY2021_Tx" SG_ 1137 RngImpctExt_Pc_Dsply 1;
BA_ "U_CD542_MY2021_Tx" SG_ 1137 RngImpctExt_Pc_Dsply 1;
BA_ "GenSigStartValueInteger" SG_ 1137 RngImpctDrv_Pc_Dsply 1023;
BA_ "GenSigStartValue" SG_ 1137 RngImpctDrv_Pc_Dsply 1022;
BA_ "U_CX727_MY2021_Tx" SG_ 1137 RngImpctDrv_Pc_Dsply 1;
BA_ "U_CD542_MY2021_Tx" SG_ 1137 RngImpctDrv_Pc_Dsply 1;
BA_ "GenSigStartValueInteger" SG_ 1137 RngImpctClim_Pc_Dsply 1023;
BA_ "GenSigStartValue" SG_ 1137 RngImpctClim_Pc_Dsply 1022;
BA_ "U_CX727_MY2021_Tx" SG_ 1137 RngImpctClim_Pc_Dsply 1;
BA_ "U_CD542_MY2021_Tx" SG_ 1137 RngImpctClim_Pc_Dsply 1;
BA_ "U_T6_MCA_MY2020_Tx" SG_ 1255 BalrRight4Threat_D_Stat 1;
BA_ "U_CD542_MY2021_Tx" SG_ 1255 BalrRight4Threat_D_Stat 1;
BA_ "U_U55X_MY2022_Tx" SG_ 1255 BalrRight4Threat_D_Stat 1;
BA_ "U_CD764_MY2022_Tx" SG_ 1255 BalrRight4Threat_D_Stat 1;
BA_ "GenSigStartValueInteger" SG_ 1255 BalrRight4Prev3Y_L_Actl 64;
BA_ "U_T6_MCA_MY2020_Tx" SG_ 1255 BalrRight4Prev3Y_L_Actl 1;
BA_ "U_CD542_MY2021_Tx" SG_ 1255 BalrRight4Prev3Y_L_Actl 1;
BA_ "U_U55X_MY2022_Tx" SG_ 1255 BalrRight4Prev3Y_L_Actl 1;
BA_ "U_CD764_MY2022_Tx" SG_ 1255 BalrRight4Prev3Y_L_Actl 1;
BA_ "GenSigStartValueInteger" SG_ 1255 BalrRight4Prev3X_L_Actl 64;
BA_ "U_T6_MCA_MY2020_Tx" SG_ 1255 BalrRight4Prev3X_L_Actl 1;
BA_ "U_CD542_MY2021_Tx" SG_ 1255 BalrRight4Prev3X_L_Actl 1;
BA_ "U_U55X_MY2022_Tx" SG_ 1255 BalrRight4Prev3X_L_Actl 1;
BA_ "U_CD764_MY2022_Tx" SG_ 1255 BalrRight4Prev3X_L_Actl 1;
BA_ "GenSigStartValueInteger" SG_ 1255 BalrRight4Prev2Y_L_Actl 64;
BA_ "U_T6_MCA_MY2020_Tx" SG_ 1255 BalrRight4Prev2Y_L_Actl 1;
BA_ "U_CD542_MY2021_Tx" SG_ 1255 BalrRight4Prev2Y_L_Actl 1;
BA_ "U_U55X_MY2022_Tx" SG_ 1255 BalrRight4Prev2Y_L_Actl 1;
BA_ "U_CD764_MY2022_Tx" SG_ 1255 BalrRight4Prev2Y_L_Actl 1;
BA_ "GenSigStartValueInteger" SG_ 1255 BalrRight4Prev2X_L_Actl 64;
BA_ "U_T6_MCA_MY2020_Tx" SG_ 1255 BalrRight4Prev2X_L_Actl 1;
BA_ "U_CD542_MY2021_Tx" SG_ 1255 BalrRight4Prev2X_L_Actl 1;
BA_ "U_U55X_MY2022_Tx" SG_ 1255 BalrRight4Prev2X_L_Actl 1;
BA_ "U_CD764_MY2022_Tx" SG_ 1255 BalrRight4Prev2X_L_Actl 1;
BA_ "GenSigStartValueInteger" SG_ 1255 BalrRight4Prev1Y_L_Actl 64;
BA_ "U_T6_MCA_MY2020_Tx" SG_ 1255 BalrRight4Prev1Y_L_Actl 1;
BA_ "U_CD542_MY2021_Tx" SG_ 1255 BalrRight4Prev1Y_L_Actl 1;
BA_ "U_U55X_MY2022_Tx" SG_ 1255 BalrRight4Prev1Y_L_Actl 1;
BA_ "U_CD764_MY2022_Tx" SG_ 1255 BalrRight4Prev1Y_L_Actl 1;
BA_ "GenSigStartValueInteger" SG_ 1255 BalrRight4Prev1X_L_Actl 64;
BA_ "U_T6_MCA_MY2020_Tx" SG_ 1255 BalrRight4Prev1X_L_Actl 1;
BA_ "U_CD542_MY2021_Tx" SG_ 1255 BalrRight4Prev1X_L_Actl 1;
BA_ "U_U55X_MY2022_Tx" SG_ 1255 BalrRight4Prev1X_L_Actl 1;
BA_ "U_CD764_MY2022_Tx" SG_ 1255 BalrRight4Prev1X_L_Actl 1;
BA_ "U_T6_MCA_MY2020_Tx" SG_ 1255 BalrRight4Fast_B_Stat 1;
BA_ "U_CD542_MY2021_Tx" SG_ 1255 BalrRight4Fast_B_Stat 1;
BA_ "U_U55X_MY2022_Tx" SG_ 1255 BalrRight4Fast_B_Stat 1;
BA_ "U_CD764_MY2022_Tx" SG_ 1255 BalrRight4Fast_B_Stat 1;
BA_ "U_T6_MCA_MY2020_Tx" SG_ 1255 BalrRight4Dsply_B_Stat 1;
BA_ "U_CD542_MY2021_Tx" SG_ 1255 BalrRight4Dsply_B_Stat 1;
BA_ "U_U55X_MY2022_Tx" SG_ 1255 BalrRight4Dsply_B_Stat 1;
BA_ "U_CD764_MY2022_Tx" SG_ 1255 BalrRight4Dsply_B_Stat 1;
BA_ "GenSigStartValueInteger" SG_ 1255 BalrRight4CurntY_L_Actl 64;
BA_ "U_T6_MCA_MY2020_Tx" SG_ 1255 BalrRight4CurntY_L_Actl 1;
BA_ "U_CD542_MY2021_Tx" SG_ 1255 BalrRight4CurntY_L_Actl 1;
BA_ "U_U55X_MY2022_Tx" SG_ 1255 BalrRight4CurntY_L_Actl 1;
BA_ "U_CD764_MY2022_Tx" SG_ 1255 BalrRight4CurntY_L_Actl 1;
BA_ "GenSigStartValueInteger" SG_ 1255 BalrRight4CurntX_L_Actl 64;
BA_ "U_T6_MCA_MY2020_Tx" SG_ 1255 BalrRight4CurntX_L_Actl 1;
BA_ "U_CD542_MY2021_Tx" SG_ 1255 BalrRight4CurntX_L_Actl 1;
BA_ "U_U55X_MY2022_Tx" SG_ 1255 BalrRight4CurntX_L_Actl 1;
BA_ "U_CD764_MY2022_Tx" SG_ 1255 BalrRight4CurntX_L_Actl 1;
BA_ "GenSigSendType" SG_ 1254 BalrRight3Threat_D_Stat 3;
BA_ "U_T6_MCA_MY2020_Tx" SG_ 1254 BalrRight3Threat_D_Stat 1;
BA_ "U_CD542_MY2021_Tx" SG_ 1254 BalrRight3Threat_D_Stat 1;
BA_ "U_U55X_MY2022_Tx" SG_ 1254 BalrRight3Threat_D_Stat 1;
BA_ "U_CD764_MY2022_Tx" SG_ 1254 BalrRight3Threat_D_Stat 1;
BA_ "GenSigStartValueInteger" SG_ 1254 BalrRight3Prev3Y_L_Actl 64;
BA_ "U_T6_MCA_MY2020_Tx" SG_ 1254 BalrRight3Prev3Y_L_Actl 1;
BA_ "U_CD542_MY2021_Tx" SG_ 1254 BalrRight3Prev3Y_L_Actl 1;
BA_ "U_U55X_MY2022_Tx" SG_ 1254 BalrRight3Prev3Y_L_Actl 1;
BA_ "U_CD764_MY2022_Tx" SG_ 1254 BalrRight3Prev3Y_L_Actl 1;
BA_ "GenSigStartValueInteger" SG_ 1254 BalrRight3Prev3X_L_Actl 64;
BA_ "U_T6_MCA_MY2020_Tx" SG_ 1254 BalrRight3Prev3X_L_Actl 1;
BA_ "U_CD542_MY2021_Tx" SG_ 1254 BalrRight3Prev3X_L_Actl 1;
BA_ "U_U55X_MY2022_Tx" SG_ 1254 BalrRight3Prev3X_L_Actl 1;
BA_ "U_CD764_MY2022_Tx" SG_ 1254 BalrRight3Prev3X_L_Actl 1;
BA_ "GenSigStartValueInteger" SG_ 1254 BalrRight3Prev2Y_L_Actl 64;
BA_ "U_T6_MCA_MY2020_Tx" SG_ 1254 BalrRight3Prev2Y_L_Actl 1;
BA_ "U_CD542_MY2021_Tx" SG_ 1254 BalrRight3Prev2Y_L_Actl 1;
BA_ "U_U55X_MY2022_Tx" SG_ 1254 BalrRight3Prev2Y_L_Actl 1;
BA_ "U_CD764_MY2022_Tx" SG_ 1254 BalrRight3Prev2Y_L_Actl 1;
BA_ "GenSigStartValueInteger" SG_ 1254 BalrRight3Prev2X_L_Actl 64;
BA_ "U_T6_MCA_MY2020_Tx" SG_ 1254 BalrRight3Prev2X_L_Actl 1;
BA_ "U_CD542_MY2021_Tx" SG_ 1254 BalrRight3Prev2X_L_Actl 1;
BA_ "U_U55X_MY2022_Tx" SG_ 1254 BalrRight3Prev2X_L_Actl 1;
BA_ "U_CD764_MY2022_Tx" SG_ 1254 BalrRight3Prev2X_L_Actl 1;
BA_ "GenSigStartValueInteger" SG_ 1254 BalrRight3Prev1Y_L_Actl 64;
BA_ "U_T6_MCA_MY2020_Tx" SG_ 1254 BalrRight3Prev1Y_L_Actl 1;
BA_ "U_CD542_MY2021_Tx" SG_ 1254 BalrRight3Prev1Y_L_Actl 1;
BA_ "U_U55X_MY2022_Tx" SG_ 1254 BalrRight3Prev1Y_L_Actl 1;
BA_ "U_CD764_MY2022_Tx" SG_ 1254 BalrRight3Prev1Y_L_Actl 1;
BA_ "GenSigStartValueInteger" SG_ 1254 BalrRight3Prev1X_L_Actl 64;
BA_ "U_T6_MCA_MY2020_Tx" SG_ 1254 BalrRight3Prev1X_L_Actl 1;
BA_ "U_CD542_MY2021_Tx" SG_ 1254 BalrRight3Prev1X_L_Actl 1;
BA_ "U_U55X_MY2022_Tx" SG_ 1254 BalrRight3Prev1X_L_Actl 1;
BA_ "U_CD764_MY2022_Tx" SG_ 1254 BalrRight3Prev1X_L_Actl 1;
BA_ "GenSigSendType" SG_ 1254 BalrRight3Fast_B_Stat 3;
BA_ "U_T6_MCA_MY2020_Tx" SG_ 1254 BalrRight3Fast_B_Stat 1;
BA_ "U_CD542_MY2021_Tx" SG_ 1254 BalrRight3Fast_B_Stat 1;
BA_ "U_U55X_MY2022_Tx" SG_ 1254 BalrRight3Fast_B_Stat 1;
BA_ "U_CD764_MY2022_Tx" SG_ 1254 BalrRight3Fast_B_Stat 1;
BA_ "GenSigSendType" SG_ 1254 BalrRight3Dsply_B_Stat 3;
BA_ "U_T6_MCA_MY2020_Tx" SG_ 1254 BalrRight3Dsply_B_Stat 1;
BA_ "U_CD542_MY2021_Tx" SG_ 1254 BalrRight3Dsply_B_Stat 1;
BA_ "U_U55X_MY2022_Tx" SG_ 1254 BalrRight3Dsply_B_Stat 1;
BA_ "U_CD764_MY2022_Tx" SG_ 1254 BalrRight3Dsply_B_Stat 1;
BA_ "GenSigStartValueInteger" SG_ 1254 BalrRight3CurntY_L_Actl 64;
BA_ "U_T6_MCA_MY2020_Tx" SG_ 1254 BalrRight3CurntY_L_Actl 1;
BA_ "U_CD542_MY2021_Tx" SG_ 1254 BalrRight3CurntY_L_Actl 1;
BA_ "U_U55X_MY2022_Tx" SG_ 1254 BalrRight3CurntY_L_Actl 1;
BA_ "U_CD764_MY2022_Tx" SG_ 1254 BalrRight3CurntY_L_Actl 1;
BA_ "GenSigStartValueInteger" SG_ 1254 BalrRight3CurntX_L_Actl 64;
BA_ "U_T6_MCA_MY2020_Tx" SG_ 1254 BalrRight3CurntX_L_Actl 1;
BA_ "U_CD542_MY2021_Tx" SG_ 1254 BalrRight3CurntX_L_Actl 1;
BA_ "U_U55X_MY2022_Tx" SG_ 1254 BalrRight3CurntX_L_Actl 1;
BA_ "U_CD764_MY2022_Tx" SG_ 1254 BalrRight3CurntX_L_Actl 1;
BA_ "GenSigStartValueInteger" SG_ 1253 BalrRight2Prev3Y_L_Actl 64;
BA_ "U_T6_MCA_MY2020_Tx" SG_ 1253 BalrRight2Prev3Y_L_Actl 1;
BA_ "U_CD542_MY2021_Tx" SG_ 1253 BalrRight2Prev3Y_L_Actl 1;
BA_ "U_U55X_MY2022_Tx" SG_ 1253 BalrRight2Prev3Y_L_Actl 1;
BA_ "U_CD764_MY2022_Tx" SG_ 1253 BalrRight2Prev3Y_L_Actl 1;
BA_ "GenSigStartValueInteger" SG_ 1253 BalrRight2Prev3X_L_Actl 64;
BA_ "U_T6_MCA_MY2020_Tx" SG_ 1253 BalrRight2Prev3X_L_Actl 1;
BA_ "U_CD542_MY2021_Tx" SG_ 1253 BalrRight2Prev3X_L_Actl 1;
BA_ "U_U55X_MY2022_Tx" SG_ 1253 BalrRight2Prev3X_L_Actl 1;
BA_ "U_CD764_MY2022_Tx" SG_ 1253 BalrRight2Prev3X_L_Actl 1;
BA_ "GenSigSendType" SG_ 1253 BalrRight2Threat_D_Stat 3;
BA_ "U_T6_MCA_MY2020_Tx" SG_ 1253 BalrRight2Threat_D_Stat 1;
BA_ "U_CD542_MY2021_Tx" SG_ 1253 BalrRight2Threat_D_Stat 1;
BA_ "U_U55X_MY2022_Tx" SG_ 1253 BalrRight2Threat_D_Stat 1;
BA_ "U_CD764_MY2022_Tx" SG_ 1253 BalrRight2Threat_D_Stat 1;
BA_ "GenSigStartValueInteger" SG_ 1253 BalrRight2Prev2Y_L_Actl 64;
BA_ "U_T6_MCA_MY2020_Tx" SG_ 1253 BalrRight2Prev2Y_L_Actl 1;
BA_ "U_CD542_MY2021_Tx" SG_ 1253 BalrRight2Prev2Y_L_Actl 1;
BA_ "U_U55X_MY2022_Tx" SG_ 1253 BalrRight2Prev2Y_L_Actl 1;
BA_ "U_CD764_MY2022_Tx" SG_ 1253 BalrRight2Prev2Y_L_Actl 1;
BA_ "GenSigStartValueInteger" SG_ 1253 BalrRight2Prev2X_L_Actl 64;
BA_ "U_T6_MCA_MY2020_Tx" SG_ 1253 BalrRight2Prev2X_L_Actl 1;
BA_ "U_CD542_MY2021_Tx" SG_ 1253 BalrRight2Prev2X_L_Actl 1;
BA_ "U_U55X_MY2022_Tx" SG_ 1253 BalrRight2Prev2X_L_Actl 1;
BA_ "U_CD764_MY2022_Tx" SG_ 1253 BalrRight2Prev2X_L_Actl 1;
BA_ "GenSigStartValueInteger" SG_ 1253 BalrRight2Prev1Y_L_Actl 64;
BA_ "U_T6_MCA_MY2020_Tx" SG_ 1253 BalrRight2Prev1Y_L_Actl 1;
BA_ "U_CD542_MY2021_Tx" SG_ 1253 BalrRight2Prev1Y_L_Actl 1;
BA_ "U_U55X_MY2022_Tx" SG_ 1253 BalrRight2Prev1Y_L_Actl 1;
BA_ "U_CD764_MY2022_Tx" SG_ 1253 BalrRight2Prev1Y_L_Actl 1;
BA_ "GenSigStartValueInteger" SG_ 1253 BalrRight2Prev1X_L_Actl 64;
BA_ "U_T6_MCA_MY2020_Tx" SG_ 1253 BalrRight2Prev1X_L_Actl 1;
BA_ "U_CD542_MY2021_Tx" SG_ 1253 BalrRight2Prev1X_L_Actl 1;
BA_ "U_U55X_MY2022_Tx" SG_ 1253 BalrRight2Prev1X_L_Actl 1;
BA_ "U_CD764_MY2022_Tx" SG_ 1253 BalrRight2Prev1X_L_Actl 1;
BA_ "GenSigSendType" SG_ 1253 BalrRight2Fast_B_Stat 3;
BA_ "U_T6_MCA_MY2020_Tx" SG_ 1253 BalrRight2Fast_B_Stat 1;
BA_ "U_CD542_MY2021_Tx" SG_ 1253 BalrRight2Fast_B_Stat 1;
BA_ "U_U55X_MY2022_Tx" SG_ 1253 BalrRight2Fast_B_Stat 1;
BA_ "U_CD764_MY2022_Tx" SG_ 1253 BalrRight2Fast_B_Stat 1;
BA_ "GenSigSendType" SG_ 1253 BalrRight2Dsply_B_Stat 3;
BA_ "U_T6_MCA_MY2020_Tx" SG_ 1253 BalrRight2Dsply_B_Stat 1;
BA_ "U_CD542_MY2021_Tx" SG_ 1253 BalrRight2Dsply_B_Stat 1;
BA_ "U_U55X_MY2022_Tx" SG_ 1253 BalrRight2Dsply_B_Stat 1;
BA_ "U_CD764_MY2022_Tx" SG_ 1253 BalrRight2Dsply_B_Stat 1;
BA_ "GenSigStartValueInteger" SG_ 1253 BalrRight2CurntY_L_Actl 64;
BA_ "U_T6_MCA_MY2020_Tx" SG_ 1253 BalrRight2CurntY_L_Actl 1;
BA_ "U_CD542_MY2021_Tx" SG_ 1253 BalrRight2CurntY_L_Actl 1;
BA_ "U_U55X_MY2022_Tx" SG_ 1253 BalrRight2CurntY_L_Actl 1;
BA_ "U_CD764_MY2022_Tx" SG_ 1253 BalrRight2CurntY_L_Actl 1;
BA_ "GenSigStartValueInteger" SG_ 1253 BalrRight2CurntX_L_Actl 64;
BA_ "U_T6_MCA_MY2020_Tx" SG_ 1253 BalrRight2CurntX_L_Actl 1;
BA_ "U_CD542_MY2021_Tx" SG_ 1253 BalrRight2CurntX_L_Actl 1;
BA_ "U_U55X_MY2022_Tx" SG_ 1253 BalrRight2CurntX_L_Actl 1;
BA_ "U_CD764_MY2022_Tx" SG_ 1253 BalrRight2CurntX_L_Actl 1;
BA_ "GenSigStartValueInteger" SG_ 1252 BalrRight1Prev3Y_L_Actl 64;
BA_ "U_T6_MCA_MY2020_Tx" SG_ 1252 BalrRight1Prev3Y_L_Actl 1;
BA_ "U_CD542_MY2021_Tx" SG_ 1252 BalrRight1Prev3Y_L_Actl 1;
BA_ "U_U55X_MY2022_Tx" SG_ 1252 BalrRight1Prev3Y_L_Actl 1;
BA_ "U_CD764_MY2022_Tx" SG_ 1252 BalrRight1Prev3Y_L_Actl 1;
BA_ "GenSigStartValueInteger" SG_ 1252 BalrRight1Prev3X_L_Actl 64;
BA_ "U_T6_MCA_MY2020_Tx" SG_ 1252 BalrRight1Prev3X_L_Actl 1;
BA_ "U_CD542_MY2021_Tx" SG_ 1252 BalrRight1Prev3X_L_Actl 1;
BA_ "U_U55X_MY2022_Tx" SG_ 1252 BalrRight1Prev3X_L_Actl 1;
BA_ "U_CD764_MY2022_Tx" SG_ 1252 BalrRight1Prev3X_L_Actl 1;
BA_ "GenSigSendType" SG_ 1252 BalrRight1Threat_D_Stat 3;
BA_ "U_T6_MCA_MY2020_Tx" SG_ 1252 BalrRight1Threat_D_Stat 1;
BA_ "U_CD542_MY2021_Tx" SG_ 1252 BalrRight1Threat_D_Stat 1;
BA_ "U_U55X_MY2022_Tx" SG_ 1252 BalrRight1Threat_D_Stat 1;
BA_ "U_CD764_MY2022_Tx" SG_ 1252 BalrRight1Threat_D_Stat 1;
BA_ "GenSigStartValueInteger" SG_ 1252 BalrRight1Prev2Y_L_Actl 64;
BA_ "U_T6_MCA_MY2020_Tx" SG_ 1252 BalrRight1Prev2Y_L_Actl 1;
BA_ "U_CD542_MY2021_Tx" SG_ 1252 BalrRight1Prev2Y_L_Actl 1;
BA_ "U_U55X_MY2022_Tx" SG_ 1252 BalrRight1Prev2Y_L_Actl 1;
BA_ "U_CD764_MY2022_Tx" SG_ 1252 BalrRight1Prev2Y_L_Actl 1;
BA_ "GenSigStartValueInteger" SG_ 1252 BalrRight1Prev2X_L_Actl 64;
BA_ "U_T6_MCA_MY2020_Tx" SG_ 1252 BalrRight1Prev2X_L_Actl 1;
BA_ "U_CD542_MY2021_Tx" SG_ 1252 BalrRight1Prev2X_L_Actl 1;
BA_ "U_U55X_MY2022_Tx" SG_ 1252 BalrRight1Prev2X_L_Actl 1;
BA_ "U_CD764_MY2022_Tx" SG_ 1252 BalrRight1Prev2X_L_Actl 1;
BA_ "GenSigStartValueInteger" SG_ 1252 BalrRight1Prev1Y_L_Actl 64;
BA_ "U_T6_MCA_MY2020_Tx" SG_ 1252 BalrRight1Prev1Y_L_Actl 1;
BA_ "U_CD542_MY2021_Tx" SG_ 1252 BalrRight1Prev1Y_L_Actl 1;
BA_ "U_U55X_MY2022_Tx" SG_ 1252 BalrRight1Prev1Y_L_Actl 1;
BA_ "U_CD764_MY2022_Tx" SG_ 1252 BalrRight1Prev1Y_L_Actl 1;
BA_ "GenSigStartValueInteger" SG_ 1252 BalrRight1Prev1X_L_Actl 64;
BA_ "U_T6_MCA_MY2020_Tx" SG_ 1252 BalrRight1Prev1X_L_Actl 1;
BA_ "U_CD542_MY2021_Tx" SG_ 1252 BalrRight1Prev1X_L_Actl 1;
BA_ "U_U55X_MY2022_Tx" SG_ 1252 BalrRight1Prev1X_L_Actl 1;
BA_ "U_CD764_MY2022_Tx" SG_ 1252 BalrRight1Prev1X_L_Actl 1;
BA_ "GenSigSendType" SG_ 1252 BalrRight1Fast_B_Stat 3;
BA_ "U_T6_MCA_MY2020_Tx" SG_ 1252 BalrRight1Fast_B_Stat 1;
BA_ "U_CD542_MY2021_Tx" SG_ 1252 BalrRight1Fast_B_Stat 1;
BA_ "U_U55X_MY2022_Tx" SG_ 1252 BalrRight1Fast_B_Stat 1;
BA_ "U_CD764_MY2022_Tx" SG_ 1252 BalrRight1Fast_B_Stat 1;
BA_ "GenSigSendType" SG_ 1252 BalrRight1Dsply_B_Stat 3;
BA_ "U_T6_MCA_MY2020_Tx" SG_ 1252 BalrRight1Dsply_B_Stat 1;
BA_ "U_CD542_MY2021_Tx" SG_ 1252 BalrRight1Dsply_B_Stat 1;
BA_ "U_U55X_MY2022_Tx" SG_ 1252 BalrRight1Dsply_B_Stat 1;
BA_ "U_CD764_MY2022_Tx" SG_ 1252 BalrRight1Dsply_B_Stat 1;
BA_ "GenSigStartValueInteger" SG_ 1252 BalrRight1CurntY_L_Actl 64;
BA_ "U_T6_MCA_MY2020_Tx" SG_ 1252 BalrRight1CurntY_L_Actl 1;
BA_ "U_CD542_MY2021_Tx" SG_ 1252 BalrRight1CurntY_L_Actl 1;
BA_ "U_U55X_MY2022_Tx" SG_ 1252 BalrRight1CurntY_L_Actl 1;
BA_ "U_CD764_MY2022_Tx" SG_ 1252 BalrRight1CurntY_L_Actl 1;
BA_ "GenSigStartValueInteger" SG_ 1252 BalrRight1CurntX_L_Actl 64;
BA_ "U_T6_MCA_MY2020_Tx" SG_ 1252 BalrRight1CurntX_L_Actl 1;
BA_ "U_CD542_MY2021_Tx" SG_ 1252 BalrRight1CurntX_L_Actl 1;
BA_ "U_U55X_MY2022_Tx" SG_ 1252 BalrRight1CurntX_L_Actl 1;
BA_ "U_CD764_MY2022_Tx" SG_ 1252 BalrRight1CurntX_L_Actl 1;
BA_ "U_T6_MCA_MY2020_Tx" SG_ 1251 BalrLeft4Threat_D_Stat 1;
BA_ "U_CD542_MY2021_Tx" SG_ 1251 BalrLeft4Threat_D_Stat 1;
BA_ "U_U55X_MY2022_Tx" SG_ 1251 BalrLeft4Threat_D_Stat 1;
BA_ "U_CD764_MY2022_Tx" SG_ 1251 BalrLeft4Threat_D_Stat 1;
BA_ "GenSigStartValueInteger" SG_ 1251 BalrLeft4Prev3Y_L_Actl 64;
BA_ "U_T6_MCA_MY2020_Tx" SG_ 1251 BalrLeft4Prev3Y_L_Actl 1;
BA_ "U_CD542_MY2021_Tx" SG_ 1251 BalrLeft4Prev3Y_L_Actl 1;
BA_ "U_U55X_MY2022_Tx" SG_ 1251 BalrLeft4Prev3Y_L_Actl 1;
BA_ "U_CD764_MY2022_Tx" SG_ 1251 BalrLeft4Prev3Y_L_Actl 1;
BA_ "GenSigStartValueInteger" SG_ 1251 BalrLeft4Prev3X_L_Actl 64;
BA_ "U_T6_MCA_MY2020_Tx" SG_ 1251 BalrLeft4Prev3X_L_Actl 1;
BA_ "U_CD542_MY2021_Tx" SG_ 1251 BalrLeft4Prev3X_L_Actl 1;
BA_ "U_U55X_MY2022_Tx" SG_ 1251 BalrLeft4Prev3X_L_Actl 1;
BA_ "U_CD764_MY2022_Tx" SG_ 1251 BalrLeft4Prev3X_L_Actl 1;
BA_ "GenSigStartValueInteger" SG_ 1251 BalrLeft4Prev2Y_L_Actl 64;
BA_ "U_T6_MCA_MY2020_Tx" SG_ 1251 BalrLeft4Prev2Y_L_Actl 1;
BA_ "U_CD542_MY2021_Tx" SG_ 1251 BalrLeft4Prev2Y_L_Actl 1;
BA_ "U_U55X_MY2022_Tx" SG_ 1251 BalrLeft4Prev2Y_L_Actl 1;
BA_ "U_CD764_MY2022_Tx" SG_ 1251 BalrLeft4Prev2Y_L_Actl 1;
BA_ "GenSigStartValueInteger" SG_ 1251 BalrLeft4Prev2X_L_Actl 64;
BA_ "U_T6_MCA_MY2020_Tx" SG_ 1251 BalrLeft4Prev2X_L_Actl 1;
BA_ "U_CD542_MY2021_Tx" SG_ 1251 BalrLeft4Prev2X_L_Actl 1;
BA_ "U_U55X_MY2022_Tx" SG_ 1251 BalrLeft4Prev2X_L_Actl 1;
BA_ "U_CD764_MY2022_Tx" SG_ 1251 BalrLeft4Prev2X_L_Actl 1;
BA_ "GenSigStartValueInteger" SG_ 1251 BalrLeft4Prev1Y_L_Actl 64;
BA_ "U_T6_MCA_MY2020_Tx" SG_ 1251 BalrLeft4Prev1Y_L_Actl 1;
BA_ "U_CD542_MY2021_Tx" SG_ 1251 BalrLeft4Prev1Y_L_Actl 1;
BA_ "U_U55X_MY2022_Tx" SG_ 1251 BalrLeft4Prev1Y_L_Actl 1;
BA_ "U_CD764_MY2022_Tx" SG_ 1251 BalrLeft4Prev1Y_L_Actl 1;
BA_ "GenSigStartValueInteger" SG_ 1251 BalrLeft4Prev1X_L_Actl 64;
BA_ "U_T6_MCA_MY2020_Tx" SG_ 1251 BalrLeft4Prev1X_L_Actl 1;
BA_ "U_CD542_MY2021_Tx" SG_ 1251 BalrLeft4Prev1X_L_Actl 1;
BA_ "U_U55X_MY2022_Tx" SG_ 1251 BalrLeft4Prev1X_L_Actl 1;
BA_ "U_CD764_MY2022_Tx" SG_ 1251 BalrLeft4Prev1X_L_Actl 1;
BA_ "U_T6_MCA_MY2020_Tx" SG_ 1251 BalrLeft4Fast_B_Stat 1;
BA_ "U_CD542_MY2021_Tx" SG_ 1251 BalrLeft4Fast_B_Stat 1;
BA_ "U_U55X_MY2022_Tx" SG_ 1251 BalrLeft4Fast_B_Stat 1;
BA_ "U_CD764_MY2022_Tx" SG_ 1251 BalrLeft4Fast_B_Stat 1;
BA_ "U_T6_MCA_MY2020_Tx" SG_ 1251 BalrLeft4Dsply_B_Stat 1;
BA_ "U_CD542_MY2021_Tx" SG_ 1251 BalrLeft4Dsply_B_Stat 1;
BA_ "U_U55X_MY2022_Tx" SG_ 1251 BalrLeft4Dsply_B_Stat 1;
BA_ "U_CD764_MY2022_Tx" SG_ 1251 BalrLeft4Dsply_B_Stat 1;
BA_ "GenSigStartValueInteger" SG_ 1251 BalrLeft4CurntY_L_Actl 64;
BA_ "U_T6_MCA_MY2020_Tx" SG_ 1251 BalrLeft4CurntY_L_Actl 1;
BA_ "U_CD542_MY2021_Tx" SG_ 1251 BalrLeft4CurntY_L_Actl 1;
BA_ "U_U55X_MY2022_Tx" SG_ 1251 BalrLeft4CurntY_L_Actl 1;
BA_ "U_CD764_MY2022_Tx" SG_ 1251 BalrLeft4CurntY_L_Actl 1;
BA_ "GenSigStartValueInteger" SG_ 1251 BalrLeft4CurntX_L_Actl 64;
BA_ "U_T6_MCA_MY2020_Tx" SG_ 1251 BalrLeft4CurntX_L_Actl 1;
BA_ "U_CD542_MY2021_Tx" SG_ 1251 BalrLeft4CurntX_L_Actl 1;
BA_ "U_U55X_MY2022_Tx" SG_ 1251 BalrLeft4CurntX_L_Actl 1;
BA_ "U_CD764_MY2022_Tx" SG_ 1251 BalrLeft4CurntX_L_Actl 1;
BA_ "U_T6_MCA_MY2020_Tx" SG_ 1250 BalrLeft3Threat_D_Stat 1;
BA_ "U_CD542_MY2021_Tx" SG_ 1250 BalrLeft3Threat_D_Stat 1;
BA_ "U_U55X_MY2022_Tx" SG_ 1250 BalrLeft3Threat_D_Stat 1;
BA_ "U_CD764_MY2022_Tx" SG_ 1250 BalrLeft3Threat_D_Stat 1;
BA_ "GenSigStartValueInteger" SG_ 1250 BalrLeft3Prev3Y_L_Actl 64;
BA_ "U_T6_MCA_MY2020_Tx" SG_ 1250 BalrLeft3Prev3Y_L_Actl 1;
BA_ "U_CD542_MY2021_Tx" SG_ 1250 BalrLeft3Prev3Y_L_Actl 1;
BA_ "U_U55X_MY2022_Tx" SG_ 1250 BalrLeft3Prev3Y_L_Actl 1;
BA_ "U_CD764_MY2022_Tx" SG_ 1250 BalrLeft3Prev3Y_L_Actl 1;
BA_ "GenSigStartValueInteger" SG_ 1250 BalrLeft3Prev3X_L_Actl 64;
BA_ "U_T6_MCA_MY2020_Tx" SG_ 1250 BalrLeft3Prev3X_L_Actl 1;
BA_ "U_CD542_MY2021_Tx" SG_ 1250 BalrLeft3Prev3X_L_Actl 1;
BA_ "U_U55X_MY2022_Tx" SG_ 1250 BalrLeft3Prev3X_L_Actl 1;
BA_ "U_CD764_MY2022_Tx" SG_ 1250 BalrLeft3Prev3X_L_Actl 1;
BA_ "GenSigStartValueInteger" SG_ 1250 BalrLeft3Prev2Y_L_Actl 64;
BA_ "U_T6_MCA_MY2020_Tx" SG_ 1250 BalrLeft3Prev2Y_L_Actl 1;
BA_ "U_CD542_MY2021_Tx" SG_ 1250 BalrLeft3Prev2Y_L_Actl 1;
BA_ "U_U55X_MY2022_Tx" SG_ 1250 BalrLeft3Prev2Y_L_Actl 1;
BA_ "U_CD764_MY2022_Tx" SG_ 1250 BalrLeft3Prev2Y_L_Actl 1;
BA_ "GenSigStartValueInteger" SG_ 1250 BalrLeft3Prev2X_L_Actl 64;
BA_ "U_T6_MCA_MY2020_Tx" SG_ 1250 BalrLeft3Prev2X_L_Actl 1;
BA_ "U_CD542_MY2021_Tx" SG_ 1250 BalrLeft3Prev2X_L_Actl 1;
BA_ "U_U55X_MY2022_Tx" SG_ 1250 BalrLeft3Prev2X_L_Actl 1;
BA_ "U_CD764_MY2022_Tx" SG_ 1250 BalrLeft3Prev2X_L_Actl 1;
BA_ "GenSigStartValueInteger" SG_ 1250 BalrLeft3Prev1Y_L_Actl 64;
BA_ "U_T6_MCA_MY2020_Tx" SG_ 1250 BalrLeft3Prev1Y_L_Actl 1;
BA_ "U_CD542_MY2021_Tx" SG_ 1250 BalrLeft3Prev1Y_L_Actl 1;
BA_ "U_U55X_MY2022_Tx" SG_ 1250 BalrLeft3Prev1Y_L_Actl 1;
BA_ "U_CD764_MY2022_Tx" SG_ 1250 BalrLeft3Prev1Y_L_Actl 1;
BA_ "GenSigStartValueInteger" SG_ 1250 BalrLeft3Prev1X_L_Actl 64;
BA_ "U_T6_MCA_MY2020_Tx" SG_ 1250 BalrLeft3Prev1X_L_Actl 1;
BA_ "U_CD542_MY2021_Tx" SG_ 1250 BalrLeft3Prev1X_L_Actl 1;
BA_ "U_U55X_MY2022_Tx" SG_ 1250 BalrLeft3Prev1X_L_Actl 1;
BA_ "U_CD764_MY2022_Tx" SG_ 1250 BalrLeft3Prev1X_L_Actl 1;
BA_ "U_T6_MCA_MY2020_Tx" SG_ 1250 BalrLeft3Fast_B_Stat 1;
BA_ "U_CD542_MY2021_Tx" SG_ 1250 BalrLeft3Fast_B_Stat 1;
BA_ "U_U55X_MY2022_Tx" SG_ 1250 BalrLeft3Fast_B_Stat 1;
BA_ "U_CD764_MY2022_Tx" SG_ 1250 BalrLeft3Fast_B_Stat 1;
BA_ "U_T6_MCA_MY2020_Tx" SG_ 1250 BalrLeft3Dsply_B_Stat 1;
BA_ "U_CD542_MY2021_Tx" SG_ 1250 BalrLeft3Dsply_B_Stat 1;
BA_ "U_U55X_MY2022_Tx" SG_ 1250 BalrLeft3Dsply_B_Stat 1;
BA_ "U_CD764_MY2022_Tx" SG_ 1250 BalrLeft3Dsply_B_Stat 1;
BA_ "GenSigStartValueInteger" SG_ 1250 BalrLeft3CurntY_L_Actl 64;
BA_ "U_T6_MCA_MY2020_Tx" SG_ 1250 BalrLeft3CurntY_L_Actl 1;
BA_ "U_CD542_MY2021_Tx" SG_ 1250 BalrLeft3CurntY_L_Actl 1;
BA_ "U_U55X_MY2022_Tx" SG_ 1250 BalrLeft3CurntY_L_Actl 1;
BA_ "U_CD764_MY2022_Tx" SG_ 1250 BalrLeft3CurntY_L_Actl 1;
BA_ "GenSigStartValueInteger" SG_ 1250 BalrLeft3CurntX_L_Actl 64;
BA_ "U_T6_MCA_MY2020_Tx" SG_ 1250 BalrLeft3CurntX_L_Actl 1;
BA_ "U_CD542_MY2021_Tx" SG_ 1250 BalrLeft3CurntX_L_Actl 1;
BA_ "U_U55X_MY2022_Tx" SG_ 1250 BalrLeft3CurntX_L_Actl 1;
BA_ "U_CD764_MY2022_Tx" SG_ 1250 BalrLeft3CurntX_L_Actl 1;
BA_ "GenSigStartValueInteger" SG_ 1249 BalrLeft2Prev3Y_L_Actl 64;
BA_ "U_T6_MCA_MY2020_Tx" SG_ 1249 BalrLeft2Prev3Y_L_Actl 1;
BA_ "U_CD542_MY2021_Tx" SG_ 1249 BalrLeft2Prev3Y_L_Actl 1;
BA_ "U_U55X_MY2022_Tx" SG_ 1249 BalrLeft2Prev3Y_L_Actl 1;
BA_ "U_CD764_MY2022_Tx" SG_ 1249 BalrLeft2Prev3Y_L_Actl 1;
BA_ "GenSigStartValueInteger" SG_ 1249 BalrLeft2Prev3X_L_Actl 64;
BA_ "U_T6_MCA_MY2020_Tx" SG_ 1249 BalrLeft2Prev3X_L_Actl 1;
BA_ "U_CD542_MY2021_Tx" SG_ 1249 BalrLeft2Prev3X_L_Actl 1;
BA_ "U_U55X_MY2022_Tx" SG_ 1249 BalrLeft2Prev3X_L_Actl 1;
BA_ "U_CD764_MY2022_Tx" SG_ 1249 BalrLeft2Prev3X_L_Actl 1;
BA_ "U_T6_MCA_MY2020_Tx" SG_ 1249 BalrLeft2Threat_D_Stat 1;
BA_ "U_CD542_MY2021_Tx" SG_ 1249 BalrLeft2Threat_D_Stat 1;
BA_ "U_U55X_MY2022_Tx" SG_ 1249 BalrLeft2Threat_D_Stat 1;
BA_ "U_CD764_MY2022_Tx" SG_ 1249 BalrLeft2Threat_D_Stat 1;
BA_ "GenSigStartValueInteger" SG_ 1249 BalrLeft2Prev2Y_L_Actl 64;
BA_ "U_T6_MCA_MY2020_Tx" SG_ 1249 BalrLeft2Prev2Y_L_Actl 1;
BA_ "U_CD542_MY2021_Tx" SG_ 1249 BalrLeft2Prev2Y_L_Actl 1;
BA_ "U_U55X_MY2022_Tx" SG_ 1249 BalrLeft2Prev2Y_L_Actl 1;
BA_ "U_CD764_MY2022_Tx" SG_ 1249 BalrLeft2Prev2Y_L_Actl 1;
BA_ "GenSigStartValueInteger" SG_ 1249 BalrLeft2Prev2X_L_Actl 64;
BA_ "U_T6_MCA_MY2020_Tx" SG_ 1249 BalrLeft2Prev2X_L_Actl 1;
BA_ "U_CD542_MY2021_Tx" SG_ 1249 BalrLeft2Prev2X_L_Actl 1;
BA_ "U_U55X_MY2022_Tx" SG_ 1249 BalrLeft2Prev2X_L_Actl 1;
BA_ "U_CD764_MY2022_Tx" SG_ 1249 BalrLeft2Prev2X_L_Actl 1;
BA_ "GenSigStartValueInteger" SG_ 1249 BalrLeft2Prev1Y_L_Actl 64;
BA_ "U_T6_MCA_MY2020_Tx" SG_ 1249 BalrLeft2Prev1Y_L_Actl 1;
BA_ "U_CD542_MY2021_Tx" SG_ 1249 BalrLeft2Prev1Y_L_Actl 1;
BA_ "U_U55X_MY2022_Tx" SG_ 1249 BalrLeft2Prev1Y_L_Actl 1;
BA_ "U_CD764_MY2022_Tx" SG_ 1249 BalrLeft2Prev1Y_L_Actl 1;
BA_ "GenSigStartValueInteger" SG_ 1249 BalrLeft2Prev1X_L_Actl 64;
BA_ "U_T6_MCA_MY2020_Tx" SG_ 1249 BalrLeft2Prev1X_L_Actl 1;
BA_ "U_CD542_MY2021_Tx" SG_ 1249 BalrLeft2Prev1X_L_Actl 1;
BA_ "U_U55X_MY2022_Tx" SG_ 1249 BalrLeft2Prev1X_L_Actl 1;
BA_ "U_CD764_MY2022_Tx" SG_ 1249 BalrLeft2Prev1X_L_Actl 1;
BA_ "U_T6_MCA_MY2020_Tx" SG_ 1249 BalrLeft2Fast_B_Stat 1;
BA_ "U_CD542_MY2021_Tx" SG_ 1249 BalrLeft2Fast_B_Stat 1;
BA_ "U_U55X_MY2022_Tx" SG_ 1249 BalrLeft2Fast_B_Stat 1;
BA_ "U_CD764_MY2022_Tx" SG_ 1249 BalrLeft2Fast_B_Stat 1;
BA_ "U_T6_MCA_MY2020_Tx" SG_ 1249 BalrLeft2Dsply_B_Stat 1;
BA_ "U_CD542_MY2021_Tx" SG_ 1249 BalrLeft2Dsply_B_Stat 1;
BA_ "U_U55X_MY2022_Tx" SG_ 1249 BalrLeft2Dsply_B_Stat 1;
BA_ "U_CD764_MY2022_Tx" SG_ 1249 BalrLeft2Dsply_B_Stat 1;
BA_ "GenSigStartValueInteger" SG_ 1249 BalrLeft2CurntY_L_Actl 64;
BA_ "U_T6_MCA_MY2020_Tx" SG_ 1249 BalrLeft2CurntY_L_Actl 1;
BA_ "U_CD542_MY2021_Tx" SG_ 1249 BalrLeft2CurntY_L_Actl 1;
BA_ "U_U55X_MY2022_Tx" SG_ 1249 BalrLeft2CurntY_L_Actl 1;
BA_ "U_CD764_MY2022_Tx" SG_ 1249 BalrLeft2CurntY_L_Actl 1;
BA_ "GenSigStartValueInteger" SG_ 1249 BalrLeft2CurntX_L_Actl 64;
BA_ "U_T6_MCA_MY2020_Tx" SG_ 1249 BalrLeft2CurntX_L_Actl 1;
BA_ "U_CD542_MY2021_Tx" SG_ 1249 BalrLeft2CurntX_L_Actl 1;
BA_ "U_U55X_MY2022_Tx" SG_ 1249 BalrLeft2CurntX_L_Actl 1;
BA_ "U_CD764_MY2022_Tx" SG_ 1249 BalrLeft2CurntX_L_Actl 1;
BA_ "GenSigSendType" SG_ 1248 BalrLeft1Threat_D_Stat 3;
BA_ "U_T6_MCA_MY2020_Tx" SG_ 1248 BalrLeft1Threat_D_Stat 1;
BA_ "U_CD542_MY2021_Tx" SG_ 1248 BalrLeft1Threat_D_Stat 1;
BA_ "U_U55X_MY2022_Tx" SG_ 1248 BalrLeft1Threat_D_Stat 1;
BA_ "U_CD764_MY2022_Tx" SG_ 1248 BalrLeft1Threat_D_Stat 1;
BA_ "GenSigStartValueInteger" SG_ 1248 BalrLeft1Prev3Y_L_Actl 64;
BA_ "U_T6_MCA_MY2020_Tx" SG_ 1248 BalrLeft1Prev3Y_L_Actl 1;
BA_ "U_CD542_MY2021_Tx" SG_ 1248 BalrLeft1Prev3Y_L_Actl 1;
BA_ "U_U55X_MY2022_Tx" SG_ 1248 BalrLeft1Prev3Y_L_Actl 1;
BA_ "U_CD764_MY2022_Tx" SG_ 1248 BalrLeft1Prev3Y_L_Actl 1;
BA_ "GenSigStartValueInteger" SG_ 1248 BalrLeft1Prev3X_L_Actl 64;
BA_ "U_T6_MCA_MY2020_Tx" SG_ 1248 BalrLeft1Prev3X_L_Actl 1;
BA_ "U_CD542_MY2021_Tx" SG_ 1248 BalrLeft1Prev3X_L_Actl 1;
BA_ "U_U55X_MY2022_Tx" SG_ 1248 BalrLeft1Prev3X_L_Actl 1;
BA_ "U_CD764_MY2022_Tx" SG_ 1248 BalrLeft1Prev3X_L_Actl 1;
BA_ "GenSigStartValueInteger" SG_ 1248 BalrLeft1Prev2Y_L_Actl 64;
BA_ "U_T6_MCA_MY2020_Tx" SG_ 1248 BalrLeft1Prev2Y_L_Actl 1;
BA_ "U_CD542_MY2021_Tx" SG_ 1248 BalrLeft1Prev2Y_L_Actl 1;
BA_ "U_U55X_MY2022_Tx" SG_ 1248 BalrLeft1Prev2Y_L_Actl 1;
BA_ "U_CD764_MY2022_Tx" SG_ 1248 BalrLeft1Prev2Y_L_Actl 1;
BA_ "GenSigStartValueInteger" SG_ 1248 BalrLeft1Prev2X_L_Actl 64;
BA_ "U_T6_MCA_MY2020_Tx" SG_ 1248 BalrLeft1Prev2X_L_Actl 1;
BA_ "U_CD542_MY2021_Tx" SG_ 1248 BalrLeft1Prev2X_L_Actl 1;
BA_ "U_U55X_MY2022_Tx" SG_ 1248 BalrLeft1Prev2X_L_Actl 1;
BA_ "U_CD764_MY2022_Tx" SG_ 1248 BalrLeft1Prev2X_L_Actl 1;
BA_ "GenSigStartValueInteger" SG_ 1248 BalrLeft1Prev1Y_L_Actl 64;
BA_ "U_T6_MCA_MY2020_Tx" SG_ 1248 BalrLeft1Prev1Y_L_Actl 1;
BA_ "U_CD542_MY2021_Tx" SG_ 1248 BalrLeft1Prev1Y_L_Actl 1;
BA_ "U_U55X_MY2022_Tx" SG_ 1248 BalrLeft1Prev1Y_L_Actl 1;
BA_ "U_CD764_MY2022_Tx" SG_ 1248 BalrLeft1Prev1Y_L_Actl 1;
BA_ "GenSigStartValueInteger" SG_ 1248 BalrLeft1Prev1X_L_Actl 64;
BA_ "U_T6_MCA_MY2020_Tx" SG_ 1248 BalrLeft1Prev1X_L_Actl 1;
BA_ "U_CD542_MY2021_Tx" SG_ 1248 BalrLeft1Prev1X_L_Actl 1;
BA_ "U_U55X_MY2022_Tx" SG_ 1248 BalrLeft1Prev1X_L_Actl 1;
BA_ "U_CD764_MY2022_Tx" SG_ 1248 BalrLeft1Prev1X_L_Actl 1;
BA_ "GenSigSendType" SG_ 1248 BalrLeft1Fast_B_Stat 3;
BA_ "U_T6_MCA_MY2020_Tx" SG_ 1248 BalrLeft1Fast_B_Stat 1;
BA_ "U_CD542_MY2021_Tx" SG_ 1248 BalrLeft1Fast_B_Stat 1;
BA_ "U_U55X_MY2022_Tx" SG_ 1248 BalrLeft1Fast_B_Stat 1;
BA_ "U_CD764_MY2022_Tx" SG_ 1248 BalrLeft1Fast_B_Stat 1;
BA_ "GenSigSendType" SG_ 1248 BalrLeft1Dsply_B_Stat 3;
BA_ "U_T6_MCA_MY2020_Tx" SG_ 1248 BalrLeft1Dsply_B_Stat 1;
BA_ "U_CD542_MY2021_Tx" SG_ 1248 BalrLeft1Dsply_B_Stat 1;
BA_ "U_U55X_MY2022_Tx" SG_ 1248 BalrLeft1Dsply_B_Stat 1;
BA_ "U_CD764_MY2022_Tx" SG_ 1248 BalrLeft1Dsply_B_Stat 1;
BA_ "GenSigStartValueInteger" SG_ 1248 BalrLeft1CurntY_L_Actl 64;
BA_ "U_T6_MCA_MY2020_Tx" SG_ 1248 BalrLeft1CurntY_L_Actl 1;
BA_ "U_CD542_MY2021_Tx" SG_ 1248 BalrLeft1CurntY_L_Actl 1;
BA_ "U_U55X_MY2022_Tx" SG_ 1248 BalrLeft1CurntY_L_Actl 1;
BA_ "U_CD764_MY2022_Tx" SG_ 1248 BalrLeft1CurntY_L_Actl 1;
BA_ "GenSigStartValueInteger" SG_ 1248 BalrLeft1CurntX_L_Actl 64;
BA_ "U_T6_MCA_MY2020_Tx" SG_ 1248 BalrLeft1CurntX_L_Actl 1;
BA_ "U_CD542_MY2021_Tx" SG_ 1248 BalrLeft1CurntX_L_Actl 1;
BA_ "U_U55X_MY2022_Tx" SG_ 1248 BalrLeft1CurntX_L_Actl 1;
BA_ "U_CD764_MY2022_Tx" SG_ 1248 BalrLeft1CurntX_L_Actl 1;
BA_ "GenSigSendType" SG_ 2610988248 PARSEDPhysGWM_ECGtoIPMA 3;
BA_ "U_T6_MCA_MY2020_Rx" SG_ 2610988248 PARSEDPhysGWM_ECGtoIPMA 1;
BA_ "U_CD542_MY2021_Rx" SG_ 2610988248 PARSEDPhysGWM_ECGtoIPMA 1;
BA_ "U_U55X_MY2022_Rx" SG_ 2610988248 PARSEDPhysGWM_ECGtoIPMA 1;
BA_ "U_CD764_MY2022_Rx" SG_ 2610988248 PARSEDPhysGWM_ECGtoIPMA 1;
BA_ "U_CDX706_MY2023_Rx" SG_ 2610988248 PARSEDPhysGWM_ECGtoIPMA 1;
BA_ "U_T6_MCA_MY2020_Tx" SG_ 2610988248 PARSEDPhysGWM_ECGtoIPMA 1;
BA_ "ECGUsedTxSignal" SG_ 2610988248 PARSEDPhysGWM_ECGtoIPMA 1;
BA_ "U_CD542_MY2021_Tx" SG_ 2610988248 PARSEDPhysGWM_ECGtoIPMA 1;
BA_ "U_U55X_MY2022_Tx" SG_ 2610988248 PARSEDPhysGWM_ECGtoIPMA 1;
BA_ "U_CD764_MY2022_Tx" SG_ 2610988248 PARSEDPhysGWM_ECGtoIPMA 1;
BA_ "U_CDX706_MY2023_Tx" SG_ 2610988248 PARSEDPhysGWM_ECGtoIPMA 1;
BA_ "U_P702_MY2021_Rx" SG_ 1113 TrlrTrgtAcquire_D_Stat 1;
BA_ "U_T6_MCA_MY2020_Rx" SG_ 1113 TrlrTrgtAcquire_D_Stat 1;
BA_ "U_U55X_MY2022_Rx" SG_ 1113 TrlrTrgtAcquire_D_Stat 1;
BA_ "U_T6_MCA_MY2020_Tx" SG_ 1113 TrlrTrgtAcquire_D_Stat 1;
BA_ "U_CD542_MY2021_Tx" SG_ 1113 TrlrTrgtAcquire_D_Stat 1;
BA_ "U_U55X_MY2022_Tx" SG_ 1113 TrlrTrgtAcquire_D_Stat 1;
BA_ "U_CD764_MY2022_Tx" SG_ 1113 TrlrTrgtAcquire_D_Stat 1;
BA_ "U_CDX706_MY2023_Tx" SG_ 1113 TrlrTrgtAcquire_D_Stat 1;
BA_ "U_T6_MCA_MY2020_Tx" SG_ 1113 TrlrAnOffst_An_Calc 1;
BA_ "U_CD542_MY2021_Tx" SG_ 1113 TrlrAnOffst_An_Calc 1;
BA_ "U_U55X_MY2022_Tx" SG_ 1113 TrlrAnOffst_An_Calc 1;
BA_ "U_CD764_MY2022_Tx" SG_ 1113 TrlrAnOffst_An_Calc 1;
BA_ "U_CDX706_MY2023_Tx" SG_ 1113 TrlrAnOffst_An_Calc 1;
BA_ "U_T6_MCA_MY2020_Tx" SG_ 1113 TrlrAnOffstDir_D_Calc 1;
BA_ "U_CD542_MY2021_Tx" SG_ 1113 TrlrAnOffstDir_D_Calc 1;
BA_ "U_U55X_MY2022_Tx" SG_ 1113 TrlrAnOffstDir_D_Calc 1;
BA_ "U_CD764_MY2022_Tx" SG_ 1113 TrlrAnOffstDir_D_Calc 1;
BA_ "U_CDX706_MY2023_Tx" SG_ 1113 TrlrAnOffstDir_D_Calc 1;
BA_ "U_T6_MCA_MY2020_Tx" SG_ 1113 TrlrAnCalib_B_Complt 1;
BA_ "U_CD542_MY2021_Tx" SG_ 1113 TrlrAnCalib_B_Complt 1;
BA_ "U_U55X_MY2022_Tx" SG_ 1113 TrlrAnCalib_B_Complt 1;
BA_ "U_CD764_MY2022_Tx" SG_ 1113 TrlrAnCalib_B_Complt 1;
BA_ "U_CDX706_MY2023_Tx" SG_ 1113 TrlrAnCalib_B_Complt 1;
BA_ "U_P702_MY2021_Rx" SG_ 1113 TrlrRvrse_D_Stat 1;
BA_ "U_T6_MCA_MY2020_Rx" SG_ 1113 TrlrRvrse_D_Stat 1;
BA_ "U_U55X_MY2022_Rx" SG_ 1113 TrlrRvrse_D_Stat 1;
BA_ "U_T6_MCA_MY2020_Tx" SG_ 1113 TrlrRvrse_D_Stat 1;
BA_ "U_CD542_MY2021_Tx" SG_ 1113 TrlrRvrse_D_Stat 1;
BA_ "U_U55X_MY2022_Tx" SG_ 1113 TrlrRvrse_D_Stat 1;
BA_ "U_CD764_MY2022_Tx" SG_ 1113 TrlrRvrse_D_Stat 1;
BA_ "U_CDX706_MY2023_Tx" SG_ 1113 TrlrRvrse_D_Stat 1;
BA_ "U_P702_MY2021_Rx" SG_ 1113 TrlrAid_D2_Stat 1;
BA_ "U_T6_MCA_MY2020_Rx" SG_ 1113 TrlrAid_D2_Stat 1;
BA_ "U_U55X_MY2022_Rx" SG_ 1113 TrlrAid_D2_Stat 1;
BA_ "U_T6_MCA_MY2020_Tx" SG_ 1113 TrlrAid_D2_Stat 1;
BA_ "U_CD542_MY2021_Tx" SG_ 1113 TrlrAid_D2_Stat 1;
BA_ "U_U55X_MY2022_Tx" SG_ 1113 TrlrAid_D2_Stat 1;
BA_ "U_CD764_MY2022_Tx" SG_ 1113 TrlrAid_D2_Stat 1;
BA_ "U_CDX706_MY2023_Tx" SG_ 1113 TrlrAid_D2_Stat 1;
BA_ "U_P702_MY2021_Rx" SG_ 1113 TrlrAidTrgtId_No_Actl 1;
BA_ "U_T6_MCA_MY2020_Rx" SG_ 1113 TrlrAidTrgtId_No_Actl 1;
BA_ "U_U55X_MY2022_Rx" SG_ 1113 TrlrAidTrgtId_No_Actl 1;
BA_ "U_T6_MCA_MY2020_Tx" SG_ 1113 TrlrAidTrgtId_No_Actl 1;
BA_ "U_CD542_MY2021_Tx" SG_ 1113 TrlrAidTrgtId_No_Actl 1;
BA_ "U_U55X_MY2022_Tx" SG_ 1113 TrlrAidTrgtId_No_Actl 1;
BA_ "U_CD764_MY2022_Tx" SG_ 1113 TrlrAidTrgtId_No_Actl 1;
BA_ "U_CDX706_MY2023_Tx" SG_ 1113 TrlrAidTrgtId_No_Actl 1;
BA_ "GenSigStartValueInteger" SG_ 1113 TrlrAid_An3_Actl 720;
BA_ "U_P702_MY2021_Rx" SG_ 1113 TrlrAid_An3_Actl 1;
BA_ "U_T6_MCA_MY2020_Rx" SG_ 1113 TrlrAid_An3_Actl 1;
BA_ "U_U55X_MY2022_Rx" SG_ 1113 TrlrAid_An3_Actl 1;
BA_ "U_T6_MCA_MY2020_Tx" SG_ 1113 TrlrAid_An3_Actl 1;
BA_ "U_CD542_MY2021_Tx" SG_ 1113 TrlrAid_An3_Actl 1;
BA_ "U_U55X_MY2022_Tx" SG_ 1113 TrlrAid_An3_Actl 1;
BA_ "U_CD764_MY2022_Tx" SG_ 1113 TrlrAid_An3_Actl 1;
BA_ "U_CDX706_MY2023_Tx" SG_ 1113 TrlrAid_An3_Actl 1;
BA_ "GenSigStartValueInteger" SG_ 1113 TrlrAid_AnRate2_Actl 400;
BA_ "U_P702_MY2021_Rx" SG_ 1113 TrlrAid_AnRate2_Actl 1;
BA_ "U_T6_MCA_MY2020_Rx" SG_ 1113 TrlrAid_AnRate2_Actl 1;
BA_ "U_U55X_MY2022_Rx" SG_ 1113 TrlrAid_AnRate2_Actl 1;
BA_ "U_T6_MCA_MY2020_Tx" SG_ 1113 TrlrAid_AnRate2_Actl 1;
BA_ "U_CD542_MY2021_Tx" SG_ 1113 TrlrAid_AnRate2_Actl 1;
BA_ "U_U55X_MY2022_Tx" SG_ 1113 TrlrAid_AnRate2_Actl 1;
BA_ "U_CD764_MY2022_Tx" SG_ 1113 TrlrAid_AnRate2_Actl 1;
BA_ "U_CDX706_MY2023_Tx" SG_ 1113 TrlrAid_AnRate2_Actl 1;
BA_ "GenSigStartValueInteger" SG_ 1113 HitchToVehAxle_L_Calc 255;
BA_ "GenSigStartValue" SG_ 1113 HitchToVehAxle_L_Calc 255;
BA_ "U_P702_MY2021_Rx" SG_ 1113 HitchToVehAxle_L_Calc 1;
BA_ "U_T6_MCA_MY2020_Rx" SG_ 1113 HitchToVehAxle_L_Calc 1;
BA_ "U_U55X_MY2022_Rx" SG_ 1113 HitchToVehAxle_L_Calc 1;
BA_ "U_T6_MCA_MY2020_Tx" SG_ 1113 HitchToVehAxle_L_Calc 1;
BA_ "U_CD542_MY2021_Tx" SG_ 1113 HitchToVehAxle_L_Calc 1;
BA_ "U_U55X_MY2022_Tx" SG_ 1113 HitchToVehAxle_L_Calc 1;
BA_ "U_CD764_MY2022_Tx" SG_ 1113 HitchToVehAxle_L_Calc 1;
BA_ "U_CDX706_MY2023_Tx" SG_ 1113 HitchToVehAxle_L_Calc 1;
BA_ "U_T6_MCA_MY2020_Tx" SG_ 1113 HitchToTrlrAxle_L_Calc2 1;
BA_ "U_CD542_MY2021_Tx" SG_ 1113 HitchToTrlrAxle_L_Calc2 1;
BA_ "U_U55X_MY2022_Tx" SG_ 1113 HitchToTrlrAxle_L_Calc2 1;
BA_ "U_CD764_MY2022_Tx" SG_ 1113 HitchToTrlrAxle_L_Calc2 1;
BA_ "U_CDX706_MY2023_Tx" SG_ 1113 HitchToTrlrAxle_L_Calc2 1;
BA_ "GenSigSendType" SG_ 1105 SpeedChngChime_D_Stat 3;
BA_ "GenSigSendType" SG_ 1105 ClrExitAsstMsgTxt2_D_Rq 3;
BA_ "U_U55X_MY2022_Tx" SG_ 1105 ClrExitAsstMsgTxt2_D_Rq 1;
BA_ "U_CD764_MY2022_Tx" SG_ 1105 ClrExitAsstMsgTxt2_D_Rq 1;
BA_ "U_CDX706_MY2023_Tx" SG_ 1105 ClrExitAsstMsgTxt2_D_Rq 1;
BA_ "GenSigSendType" SG_ 1105 ClrExitAsstActv_B_Rq 3;
BA_ "U_U55X_MY2022_Tx" SG_ 1105 ClrExitAsstActv_B_Rq 1;
BA_ "U_CD764_MY2022_Tx" SG_ 1105 ClrExitAsstActv_B_Rq 1;
BA_ "U_CDX706_MY2023_Tx" SG_ 1105 ClrExitAsstActv_B_Rq 1;
BA_ "GenSigSendType" SG_ 1105 TrlrRvrseMsgTxt_D2_Rq 3;
BA_ "U_P702_MY2021_Rx" SG_ 1105 TrlrRvrseMsgTxt_D2_Rq 1;
BA_ "U_T6_MCA_MY2020_Rx" SG_ 1105 TrlrRvrseMsgTxt_D2_Rq 1;
BA_ "U_U55X_MY2022_Rx" SG_ 1105 TrlrRvrseMsgTxt_D2_Rq 1;
BA_ "U_T6_MCA_MY2020_Tx" SG_ 1105 TrlrRvrseMsgTxt_D2_Rq 1;
BA_ "U_CD542_MY2021_Tx" SG_ 1105 TrlrRvrseMsgTxt_D2_Rq 1;
BA_ "U_U55X_MY2022_Tx" SG_ 1105 TrlrRvrseMsgTxt_D2_Rq 1;
BA_ "U_CD764_MY2022_Tx" SG_ 1105 TrlrRvrseMsgTxt_D2_Rq 1;
BA_ "U_CDX706_MY2023_Tx" SG_ 1105 TrlrRvrseMsgTxt_D2_Rq 1;
BA_ "GenSigSendType" SG_ 1105 TrlrRvrseEnbl_D2_Stat 3;
BA_ "U_P702_MY2021_Rx" SG_ 1105 TrlrRvrseEnbl_D2_Stat 1;
BA_ "U_T6_MCA_MY2020_Rx" SG_ 1105 TrlrRvrseEnbl_D2_Stat 1;
BA_ "U_U55X_MY2022_Rx" SG_ 1105 TrlrRvrseEnbl_D2_Stat 1;
BA_ "U_T6_MCA_MY2020_Tx" SG_ 1105 TrlrRvrseEnbl_D2_Stat 1;
BA_ "U_CD542_MY2021_Tx" SG_ 1105 TrlrRvrseEnbl_D2_Stat 1;
BA_ "U_U55X_MY2022_Tx" SG_ 1105 TrlrRvrseEnbl_D2_Stat 1;
BA_ "U_CD764_MY2022_Tx" SG_ 1105 TrlrRvrseEnbl_D2_Stat 1;
BA_ "U_CDX706_MY2023_Tx" SG_ 1105 TrlrRvrseEnbl_D2_Stat 1;
BA_ "GenSigSendType" SG_ 1105 RbaMsg_D_Rq 3;
BA_ "U_T6_MCA_MY2020_Tx" SG_ 1105 RbaMsg_D_Rq 1;
BA_ "U_CD542_MY2021_Tx" SG_ 1105 RbaMsg_D_Rq 1;
BA_ "U_U55X_MY2022_Tx" SG_ 1105 RbaMsg_D_Rq 1;
BA_ "U_CD764_MY2022_Tx" SG_ 1105 RbaMsg_D_Rq 1;
BA_ "U_CDX706_MY2023_Tx" SG_ 1105 RbaMsg_D_Rq 1;
BA_ "GenSigSendType" SG_ 1105 BrkDecel_B_RqRba 3;
BA_ "WakeupSignal" SG_ 1105 BrkDecel_B_RqRba 1;
BA_ "U_P702_MY2021_Rx" SG_ 1105 BrkDecel_B_RqRba 1;
BA_ "U_T6_MCA_MY2020_Rx" SG_ 1105 BrkDecel_B_RqRba 1;
BA_ "U_CD542_MY2021_Rx" SG_ 1105 BrkDecel_B_RqRba 1;
BA_ "U_U55X_MY2022_Rx" SG_ 1105 BrkDecel_B_RqRba 1;
BA_ "U_CD764_MY2022_Rx" SG_ 1105 BrkDecel_B_RqRba 1;
BA_ "U_CDX706_MY2023_Rx" SG_ 1105 BrkDecel_B_RqRba 1;
BA_ "U_T6_MCA_MY2020_Tx" SG_ 1105 BrkDecel_B_RqRba 1;
BA_ "U_CD542_MY2021_Tx" SG_ 1105 BrkDecel_B_RqRba 1;
BA_ "U_U55X_MY2022_Tx" SG_ 1105 BrkDecel_B_RqRba 1;
BA_ "U_CD764_MY2022_Tx" SG_ 1105 BrkDecel_B_RqRba 1;
BA_ "U_CDX706_MY2023_Tx" SG_ 1105 BrkDecel_B_RqRba 1;
BA_ "GenSigSendType" SG_ 1105 BrkEnbl_B_RqRba 3;
BA_ "WakeupSignal" SG_ 1105 BrkEnbl_B_RqRba 1;
BA_ "U_P702_MY2021_Rx" SG_ 1105 BrkEnbl_B_RqRba 1;
BA_ "U_T6_MCA_MY2020_Rx" SG_ 1105 BrkEnbl_B_RqRba 1;
BA_ "U_CD542_MY2021_Rx" SG_ 1105 BrkEnbl_B_RqRba 1;
BA_ "U_U55X_MY2022_Rx" SG_ 1105 BrkEnbl_B_RqRba 1;
BA_ "U_CD764_MY2022_Rx" SG_ 1105 BrkEnbl_B_RqRba 1;
BA_ "U_CDX706_MY2023_Rx" SG_ 1105 BrkEnbl_B_RqRba 1;
BA_ "U_T6_MCA_MY2020_Tx" SG_ 1105 BrkEnbl_B_RqRba 1;
BA_ "U_CD542_MY2021_Tx" SG_ 1105 BrkEnbl_B_RqRba 1;
BA_ "U_U55X_MY2022_Tx" SG_ 1105 BrkEnbl_B_RqRba 1;
BA_ "U_CD764_MY2022_Tx" SG_ 1105 BrkEnbl_B_RqRba 1;
BA_ "U_CDX706_MY2023_Tx" SG_ 1105 BrkEnbl_B_RqRba 1;
BA_ "GenSigSendType" SG_ 1105 Rba_D_Stat 3;
BA_ "GenSigStartValueInteger" SG_ 1105 Rba_D_Stat 1;
BA_ "GenSigStartValue" SG_ 1105 Rba_D_Stat 1;
BA_ "U_T6_MCA_MY2020_Tx" SG_ 1105 Rba_D_Stat 1;
BA_ "U_CD542_MY2021_Tx" SG_ 1105 Rba_D_Stat 1;
BA_ "U_U55X_MY2022_Tx" SG_ 1105 Rba_D_Stat 1;
BA_ "U_CD764_MY2022_Tx" SG_ 1105 Rba_D_Stat 1;
BA_ "U_CDX706_MY2023_Tx" SG_ 1105 Rba_D_Stat 1;
BA_ "GenSigSendType" SG_ 1105 RbaAlrt_D_Dsply 3;
BA_ "U_T6_MCA_MY2020_Tx" SG_ 1105 RbaAlrt_D_Dsply 1;
BA_ "U_CD542_MY2021_Tx" SG_ 1105 RbaAlrt_D_Dsply 1;
BA_ "U_U55X_MY2022_Tx" SG_ 1105 RbaAlrt_D_Dsply 1;
BA_ "U_CD764_MY2022_Tx" SG_ 1105 RbaAlrt_D_Dsply 1;
BA_ "U_CDX706_MY2023_Tx" SG_ 1105 RbaAlrt_D_Dsply 1;
BA_ "GenSigSendType" SG_ 1105 RbaMnu_D_Rq 3;
BA_ "U_T6_MCA_MY2020_Tx" SG_ 1105 RbaMnu_D_Rq 1;
BA_ "U_CD542_MY2021_Tx" SG_ 1105 RbaMnu_D_Rq 1;
BA_ "U_U55X_MY2022_Tx" SG_ 1105 RbaMnu_D_Rq 1;
BA_ "U_CD764_MY2022_Tx" SG_ 1105 RbaMnu_D_Rq 1;
BA_ "U_CDX706_MY2023_Tx" SG_ 1105 RbaMnu_D_Rq 1;
BA_ "GenSigSendType" SG_ 1105 CamraFrntStat_D_Stat 3;
BA_ "U_T6_MCA_MY2020_Tx" SG_ 1105 CamraFrntStat_D_Stat 1;
BA_ "U_CD542_MY2021_Tx" SG_ 1105 CamraFrntStat_D_Stat 1;
BA_ "U_U55X_MY2022_Tx" SG_ 1105 CamraFrntStat_D_Stat 1;
BA_ "U_CD764_MY2022_Tx" SG_ 1105 CamraFrntStat_D_Stat 1;
BA_ "U_CDX706_MY2023_Tx" SG_ 1105 CamraFrntStat_D_Stat 1;
BA_ "GenSigSendType" SG_ 1105 TrlrHitchLamp_D_Rq2 3;
BA_ "U_T6_MCA_MY2020_Tx" SG_ 1105 TrlrHitchLamp_D_Rq2 1;
BA_ "U_CD542_MY2021_Tx" SG_ 1105 TrlrHitchLamp_D_Rq2 1;
BA_ "U_U55X_MY2022_Tx" SG_ 1105 TrlrHitchLamp_D_Rq2 1;
BA_ "U_CD764_MY2022_Tx" SG_ 1105 TrlrHitchLamp_D_Rq2 1;
BA_ "U_CDX706_MY2023_Tx" SG_ 1105 TrlrHitchLamp_D_Rq2 1;
BA_ "GenSigSendType" SG_ 1105 CamraFrntOffRd_B_Stat 3;
BA_ "U_T6_MCA_MY2020_Tx" SG_ 1105 CamraFrntOffRd_B_Stat 1;
BA_ "U_U55X_MY2022_Tx" SG_ 1105 CamraFrntOffRd_B_Stat 1;
BA_ "U_CDX706_MY2023_Tx" SG_ 1105 CamraFrntOffRd_B_Stat 1;
BA_ "GenSigSendType" SG_ 1105 TrlrAidSwtchLamp_B_Rq 3;
BA_ "U_T6_MCA_MY2020_Tx" SG_ 1105 TrlrAidSwtchLamp_B_Rq 1;
BA_ "U_CD542_MY2021_Tx" SG_ 1105 TrlrAidSwtchLamp_B_Rq 1;
BA_ "U_U55X_MY2022_Tx" SG_ 1105 TrlrAidSwtchLamp_B_Rq 1;
BA_ "U_CD764_MY2022_Tx" SG_ 1105 TrlrAidSwtchLamp_B_Rq 1;
BA_ "U_CDX706_MY2023_Tx" SG_ 1105 TrlrAidSwtchLamp_B_Rq 1;
BA_ "GenSigSendType" SG_ 1105 TrlrAidEnbl_D_RqAdas 3;
BA_ "U_P702_MY2021_Rx" SG_ 1105 TrlrAidEnbl_D_RqAdas 1;
BA_ "U_T6_MCA_MY2020_Rx" SG_ 1105 TrlrAidEnbl_D_RqAdas 1;
BA_ "U_U55X_MY2022_Rx" SG_ 1105 TrlrAidEnbl_D_RqAdas 1;
BA_ "U_T6_MCA_MY2020_Tx" SG_ 1105 TrlrAidEnbl_D_RqAdas 1;
BA_ "U_CD542_MY2021_Tx" SG_ 1105 TrlrAidEnbl_D_RqAdas 1;
BA_ "U_U55X_MY2022_Tx" SG_ 1105 TrlrAidEnbl_D_RqAdas 1;
BA_ "U_CD764_MY2022_Tx" SG_ 1105 TrlrAidEnbl_D_RqAdas 1;
BA_ "U_CDX706_MY2023_Tx" SG_ 1105 TrlrAidEnbl_D_RqAdas 1;
BA_ "GenSigSendType" SG_ 1105 TrlrHitchMsgTxt_D_Rq 3;
BA_ "U_T6_MCA_MY2020_Tx" SG_ 1105 TrlrHitchMsgTxt_D_Rq 1;
BA_ "U_CD542_MY2021_Tx" SG_ 1105 TrlrHitchMsgTxt_D_Rq 1;
BA_ "U_U55X_MY2022_Tx" SG_ 1105 TrlrHitchMsgTxt_D_Rq 1;
BA_ "U_CD764_MY2022_Tx" SG_ 1105 TrlrHitchMsgTxt_D_Rq 1;
BA_ "U_CDX706_MY2023_Tx" SG_ 1105 TrlrHitchMsgTxt_D_Rq 1;
BA_ "GenSigSendType" SG_ 1105 TrlrHitchIcon_D_Rq 3;
BA_ "U_T6_MCA_MY2020_Tx" SG_ 1105 TrlrHitchIcon_D_Rq 1;
BA_ "U_CD542_MY2021_Tx" SG_ 1105 TrlrHitchIcon_D_Rq 1;
BA_ "U_U55X_MY2022_Tx" SG_ 1105 TrlrHitchIcon_D_Rq 1;
BA_ "U_CD764_MY2022_Tx" SG_ 1105 TrlrHitchIcon_D_Rq 1;
BA_ "U_CDX706_MY2023_Tx" SG_ 1105 TrlrHitchIcon_D_Rq 1;
BA_ "GenSigSendType" SG_ 1105 TrlrHitchChime_D_Rq 3;
BA_ "U_T6_MCA_MY2020_Tx" SG_ 1105 TrlrHitchChime_D_Rq 1;
BA_ "U_CD542_MY2021_Tx" SG_ 1105 TrlrHitchChime_D_Rq 1;
BA_ "U_U55X_MY2022_Tx" SG_ 1105 TrlrHitchChime_D_Rq 1;
BA_ "U_CD764_MY2022_Tx" SG_ 1105 TrlrHitchChime_D_Rq 1;
BA_ "U_CDX706_MY2023_Tx" SG_ 1105 TrlrHitchChime_D_Rq 1;
BA_ "GenSigSendType" SG_ 938 SidePrkSnsR2_D_Stat 3;
BA_ "U_T6_MCA_MY2020_Tx" SG_ 938 SidePrkSnsR2_D_Stat 1;
BA_ "U_CD542_MY2021_Tx" SG_ 938 SidePrkSnsR2_D_Stat 1;
BA_ "U_U55X_MY2022_Tx" SG_ 938 SidePrkSnsR2_D_Stat 1;
BA_ "U_CD764_MY2022_Tx" SG_ 938 SidePrkSnsR2_D_Stat 1;
BA_ "U_CDX706_MY2023_Tx" SG_ 938 SidePrkSnsR2_D_Stat 1;
BA_ "GenSigSendType" SG_ 938 SidePrkSnsR1_D_Stat 3;
BA_ "U_T6_MCA_MY2020_Tx" SG_ 938 SidePrkSnsR1_D_Stat 1;
BA_ "U_CD542_MY2021_Tx" SG_ 938 SidePrkSnsR1_D_Stat 1;
BA_ "U_U55X_MY2022_Tx" SG_ 938 SidePrkSnsR1_D_Stat 1;
BA_ "U_CD764_MY2022_Tx" SG_ 938 SidePrkSnsR1_D_Stat 1;
BA_ "U_CDX706_MY2023_Tx" SG_ 938 SidePrkSnsR1_D_Stat 1;
BA_ "GenSigSendType" SG_ 938 SidePrkSnsL2_D_Stat 3;
BA_ "U_T6_MCA_MY2020_Tx" SG_ 938 SidePrkSnsL2_D_Stat 1;
BA_ "U_CD542_MY2021_Tx" SG_ 938 SidePrkSnsL2_D_Stat 1;
BA_ "U_U55X_MY2022_Tx" SG_ 938 SidePrkSnsL2_D_Stat 1;
BA_ "U_CD764_MY2022_Tx" SG_ 938 SidePrkSnsL2_D_Stat 1;
BA_ "U_CDX706_MY2023_Tx" SG_ 938 SidePrkSnsL2_D_Stat 1;
BA_ "GenSigSendType" SG_ 938 ApaMde_D_Stat 3;
BA_ "U_T6_MCA_MY2020_Tx" SG_ 938 ApaMde_D_Stat 1;
BA_ "U_CD542_MY2021_Tx" SG_ 938 ApaMde_D_Stat 1;
BA_ "U_U55X_MY2022_Tx" SG_ 938 ApaMde_D_Stat 1;
BA_ "U_CD764_MY2022_Tx" SG_ 938 ApaMde_D_Stat 1;
BA_ "U_CDX706_MY2023_Tx" SG_ 938 ApaMde_D_Stat 1;
BA_ "GenSigSendType" SG_ 938 ApaActvSd_D_Actl 3;
BA_ "GenSigStartValueInteger" SG_ 938 ApaActvSd_D_Actl 1;
BA_ "GenSigStartValue" SG_ 938 ApaActvSd_D_Actl 1;
BA_ "U_T6_MCA_MY2020_Tx" SG_ 938 ApaActvSd_D_Actl 1;
BA_ "U_CD542_MY2021_Tx" SG_ 938 ApaActvSd_D_Actl 1;
BA_ "U_U55X_MY2022_Tx" SG_ 938 ApaActvSd_D_Actl 1;
BA_ "U_CD764_MY2022_Tx" SG_ 938 ApaActvSd_D_Actl 1;
BA_ "U_CDX706_MY2023_Tx" SG_ 938 ApaActvSd_D_Actl 1;
BA_ "GenSigSendType" SG_ 938 PrkAidSwtch_B_Stat 3;
BA_ "U_T6_MCA_MY2020_Tx" SG_ 938 PrkAidSwtch_B_Stat 1;
BA_ "U_CD542_MY2021_Tx" SG_ 938 PrkAidSwtch_B_Stat 1;
BA_ "U_U55X_MY2022_Tx" SG_ 938 PrkAidSwtch_B_Stat 1;
BA_ "U_CD764_MY2022_Tx" SG_ 938 PrkAidSwtch_B_Stat 1;
BA_ "U_CDX706_MY2023_Tx" SG_ 938 PrkAidSwtch_B_Stat 1;
BA_ "GenSigSendType" SG_ 938 ApaMde_D_Avail 3;
BA_ "U_T6_MCA_MY2020_Tx" SG_ 938 ApaMde_D_Avail 1;
BA_ "U_CD542_MY2021_Tx" SG_ 938 ApaMde_D_Avail 1;
BA_ "U_U55X_MY2022_Tx" SG_ 938 ApaMde_D_Avail 1;
BA_ "U_CD764_MY2022_Tx" SG_ 938 ApaMde_D_Avail 1;
BA_ "U_CDX706_MY2023_Tx" SG_ 938 ApaMde_D_Avail 1;
BA_ "GenSigSendType" SG_ 938 PrkAidSnsFrCrnr_D_Stat 3;
BA_ "U_T6_MCA_MY2020_Tx" SG_ 938 PrkAidSnsFrCrnr_D_Stat 1;
BA_ "U_CD542_MY2021_Tx" SG_ 938 PrkAidSnsFrCrnr_D_Stat 1;
BA_ "U_U55X_MY2022_Tx" SG_ 938 PrkAidSnsFrCrnr_D_Stat 1;
BA_ "U_CD764_MY2022_Tx" SG_ 938 PrkAidSnsFrCrnr_D_Stat 1;
BA_ "U_CDX706_MY2023_Tx" SG_ 938 PrkAidSnsFrCrnr_D_Stat 1;
BA_ "GenSigSendType" SG_ 938 PrkAidSnsFrCntr_D_Stat 3;
BA_ "U_T6_MCA_MY2020_Tx" SG_ 938 PrkAidSnsFrCntr_D_Stat 1;
BA_ "U_CD542_MY2021_Tx" SG_ 938 PrkAidSnsFrCntr_D_Stat 1;
BA_ "U_U55X_MY2022_Tx" SG_ 938 PrkAidSnsFrCntr_D_Stat 1;
BA_ "U_CD764_MY2022_Tx" SG_ 938 PrkAidSnsFrCntr_D_Stat 1;
BA_ "U_CDX706_MY2023_Tx" SG_ 938 PrkAidSnsFrCntr_D_Stat 1;
BA_ "GenSigSendType" SG_ 938 PrkAidSnsFlCrnr_D_Stat 3;
BA_ "U_T6_MCA_MY2020_Tx" SG_ 938 PrkAidSnsFlCrnr_D_Stat 1;
BA_ "U_CD542_MY2021_Tx" SG_ 938 PrkAidSnsFlCrnr_D_Stat 1;
BA_ "U_U55X_MY2022_Tx" SG_ 938 PrkAidSnsFlCrnr_D_Stat 1;
BA_ "U_CD764_MY2022_Tx" SG_ 938 PrkAidSnsFlCrnr_D_Stat 1;
BA_ "U_CDX706_MY2023_Tx" SG_ 938 PrkAidSnsFlCrnr_D_Stat 1;
BA_ "GenSigSendType" SG_ 938 PrkAidSnsFlCntr_D_Stat 3;
BA_ "U_T6_MCA_MY2020_Tx" SG_ 938 PrkAidSnsFlCntr_D_Stat 1;
BA_ "U_CD542_MY2021_Tx" SG_ 938 PrkAidSnsFlCntr_D_Stat 1;
BA_ "U_U55X_MY2022_Tx" SG_ 938 PrkAidSnsFlCntr_D_Stat 1;
BA_ "U_CD764_MY2022_Tx" SG_ 938 PrkAidSnsFlCntr_D_Stat 1;
BA_ "U_CDX706_MY2023_Tx" SG_ 938 PrkAidSnsFlCntr_D_Stat 1;
BA_ "GenSigSendType" SG_ 938 PrkBrkEl_B_RqFap 3;
BA_ "U_CX727_MY2021_Rx" SG_ 938 PrkBrkEl_B_RqFap 1;
BA_ "U_P702_MY2021_Rx" SG_ 938 PrkBrkEl_B_RqFap 1;
BA_ "U_T6_MCA_MY2020_Rx" SG_ 938 PrkBrkEl_B_RqFap 1;
BA_ "U_CD542_MY2021_Rx" SG_ 938 PrkBrkEl_B_RqFap 1;
BA_ "U_U55X_MY2022_Rx" SG_ 938 PrkBrkEl_B_RqFap 1;
BA_ "U_CD764_MY2022_Rx" SG_ 938 PrkBrkEl_B_RqFap 1;
BA_ "U_CDX706_MY2023_Rx" SG_ 938 PrkBrkEl_B_RqFap 1;
BA_ "U_T6_MCA_MY2020_Tx" SG_ 938 PrkBrkEl_B_RqFap 1;
BA_ "U_CD542_MY2021_Tx" SG_ 938 PrkBrkEl_B_RqFap 1;
BA_ "U_U55X_MY2022_Tx" SG_ 938 PrkBrkEl_B_RqFap 1;
BA_ "U_CD764_MY2022_Tx" SG_ 938 PrkBrkEl_B_RqFap 1;
BA_ "U_CDX706_MY2023_Tx" SG_ 938 PrkBrkEl_B_RqFap 1;
BA_ "GenSigSendType" SG_ 938 RpaChime_D_Rq 3;
BA_ "U_T6_MCA_MY2020_Tx" SG_ 938 RpaChime_D_Rq 1;
BA_ "U_CD542_MY2021_Tx" SG_ 938 RpaChime_D_Rq 1;
BA_ "U_U55X_MY2022_Tx" SG_ 938 RpaChime_D_Rq 1;
BA_ "U_CD764_MY2022_Tx" SG_ 938 RpaChime_D_Rq 1;
BA_ "U_CDX706_MY2023_Tx" SG_ 938 RpaChime_D_Rq 1;
BA_ "GenSigSendType" SG_ 938 FpaChime_D_Rq 3;
BA_ "U_T6_MCA_MY2020_Tx" SG_ 938 FpaChime_D_Rq 1;
BA_ "U_CD542_MY2021_Tx" SG_ 938 FpaChime_D_Rq 1;
BA_ "U_U55X_MY2022_Tx" SG_ 938 FpaChime_D_Rq 1;
BA_ "U_CD764_MY2022_Tx" SG_ 938 FpaChime_D_Rq 1;
BA_ "U_CDX706_MY2023_Tx" SG_ 938 FpaChime_D_Rq 1;
BA_ "GenSigSendType" SG_ 938 PrkAidMsgTxt_D_Rq 3;
BA_ "U_P702_MY2021_Rx" SG_ 938 PrkAidMsgTxt_D_Rq 1;
BA_ "U_T6_MCA_MY2020_Rx" SG_ 938 PrkAidMsgTxt_D_Rq 1;
BA_ "U_U55X_MY2022_Rx" SG_ 938 PrkAidMsgTxt_D_Rq 1;
BA_ "U_T6_MCA_MY2020_Tx" SG_ 938 PrkAidMsgTxt_D_Rq 1;
BA_ "U_CD542_MY2021_Tx" SG_ 938 PrkAidMsgTxt_D_Rq 1;
BA_ "U_U55X_MY2022_Tx" SG_ 938 PrkAidMsgTxt_D_Rq 1;
BA_ "U_CD764_MY2022_Tx" SG_ 938 PrkAidMsgTxt_D_Rq 1;
BA_ "U_CDX706_MY2023_Tx" SG_ 938 PrkAidMsgTxt_D_Rq 1;
BA_ "GenSigSendType" SG_ 938 SidePrkSnsL1_D_Stat 3;
BA_ "U_T6_MCA_MY2020_Tx" SG_ 938 SidePrkSnsL1_D_Stat 1;
BA_ "U_CD542_MY2021_Tx" SG_ 938 SidePrkSnsL1_D_Stat 1;
BA_ "U_U55X_MY2022_Tx" SG_ 938 SidePrkSnsL1_D_Stat 1;
BA_ "U_CD764_MY2022_Tx" SG_ 938 SidePrkSnsL1_D_Stat 1;
BA_ "U_CDX706_MY2023_Tx" SG_ 938 SidePrkSnsL1_D_Stat 1;
BA_ "GenSigSendType" SG_ 938 PrkAidAudioMute_B_Rq 3;
BA_ "U_T6_MCA_MY2020_Tx" SG_ 938 PrkAidAudioMute_B_Rq 1;
BA_ "U_CD542_MY2021_Tx" SG_ 938 PrkAidAudioMute_B_Rq 1;
BA_ "U_U55X_MY2022_Tx" SG_ 938 PrkAidAudioMute_B_Rq 1;
BA_ "U_CD764_MY2022_Tx" SG_ 938 PrkAidAudioMute_B_Rq 1;
BA_ "U_CDX706_MY2023_Tx" SG_ 938 PrkAidAudioMute_B_Rq 1;
BA_ "GenSigSendType" SG_ 939 SidePrkSnsR4_D_Stat 3;
BA_ "U_T6_MCA_MY2020_Tx" SG_ 939 SidePrkSnsR4_D_Stat 1;
BA_ "U_CD542_MY2021_Tx" SG_ 939 SidePrkSnsR4_D_Stat 1;
BA_ "U_U55X_MY2022_Tx" SG_ 939 SidePrkSnsR4_D_Stat 1;
BA_ "U_CD764_MY2022_Tx" SG_ 939 SidePrkSnsR4_D_Stat 1;
BA_ "U_CDX706_MY2023_Tx" SG_ 939 SidePrkSnsR4_D_Stat 1;
BA_ "GenSigSendType" SG_ 939 SidePrkSnsR3_D_Stat 3;
BA_ "U_T6_MCA_MY2020_Tx" SG_ 939 SidePrkSnsR3_D_Stat 1;
BA_ "U_CD542_MY2021_Tx" SG_ 939 SidePrkSnsR3_D_Stat 1;
BA_ "U_U55X_MY2022_Tx" SG_ 939 SidePrkSnsR3_D_Stat 1;
BA_ "U_CD764_MY2022_Tx" SG_ 939 SidePrkSnsR3_D_Stat 1;
BA_ "U_CDX706_MY2023_Tx" SG_ 939 SidePrkSnsR3_D_Stat 1;
BA_ "GenSigSendType" SG_ 939 SidePrkSnsL4_D_Stat 3;
BA_ "U_T6_MCA_MY2020_Tx" SG_ 939 SidePrkSnsL4_D_Stat 1;
BA_ "U_CD542_MY2021_Tx" SG_ 939 SidePrkSnsL4_D_Stat 1;
BA_ "U_U55X_MY2022_Tx" SG_ 939 SidePrkSnsL4_D_Stat 1;
BA_ "U_CD764_MY2022_Tx" SG_ 939 SidePrkSnsL4_D_Stat 1;
BA_ "U_CDX706_MY2023_Tx" SG_ 939 SidePrkSnsL4_D_Stat 1;
BA_ "GenSigSendType" SG_ 939 SidePrkSnsL3_D_Stat 3;
BA_ "U_T6_MCA_MY2020_Tx" SG_ 939 SidePrkSnsL3_D_Stat 1;
BA_ "U_CD542_MY2021_Tx" SG_ 939 SidePrkSnsL3_D_Stat 1;
BA_ "U_U55X_MY2022_Tx" SG_ 939 SidePrkSnsL3_D_Stat 1;
BA_ "U_CD764_MY2022_Tx" SG_ 939 SidePrkSnsL3_D_Stat 1;
BA_ "U_CDX706_MY2023_Tx" SG_ 939 SidePrkSnsL3_D_Stat 1;
BA_ "GenSigSendType" SG_ 939 PrkAidChime_D_Stat 3;
BA_ "U_T6_MCA_MY2020_Tx" SG_ 939 PrkAidChime_D_Stat 1;
BA_ "U_CD542_MY2021_Tx" SG_ 939 PrkAidChime_D_Stat 1;
BA_ "U_U55X_MY2022_Tx" SG_ 939 PrkAidChime_D_Stat 1;
BA_ "U_CD764_MY2022_Tx" SG_ 939 PrkAidChime_D_Stat 1;
BA_ "U_CDX706_MY2023_Tx" SG_ 939 PrkAidChime_D_Stat 1;
BA_ "GenSigSendType" SG_ 939 PrkAidSnsRlCntr_D_Stat 3;
BA_ "U_T6_MCA_MY2020_Tx" SG_ 939 PrkAidSnsRlCntr_D_Stat 1;
BA_ "U_CD542_MY2021_Tx" SG_ 939 PrkAidSnsRlCntr_D_Stat 1;
BA_ "U_U55X_MY2022_Tx" SG_ 939 PrkAidSnsRlCntr_D_Stat 1;
BA_ "U_CD764_MY2022_Tx" SG_ 939 PrkAidSnsRlCntr_D_Stat 1;
BA_ "U_CDX706_MY2023_Tx" SG_ 939 PrkAidSnsRlCntr_D_Stat 1;
BA_ "GenSigSendType" SG_ 939 PrkAidSnsRrCrnr_D_Stat 3;
BA_ "U_T6_MCA_MY2020_Tx" SG_ 939 PrkAidSnsRrCrnr_D_Stat 1;
BA_ "U_CD542_MY2021_Tx" SG_ 939 PrkAidSnsRrCrnr_D_Stat 1;
BA_ "U_U55X_MY2022_Tx" SG_ 939 PrkAidSnsRrCrnr_D_Stat 1;
BA_ "U_CD764_MY2022_Tx" SG_ 939 PrkAidSnsRrCrnr_D_Stat 1;
BA_ "U_CDX706_MY2023_Tx" SG_ 939 PrkAidSnsRrCrnr_D_Stat 1;
BA_ "GenSigSendType" SG_ 939 PrkAidSnsRrCntr_D_Stat 3;
BA_ "U_T6_MCA_MY2020_Tx" SG_ 939 PrkAidSnsRrCntr_D_Stat 1;
BA_ "U_CD542_MY2021_Tx" SG_ 939 PrkAidSnsRrCntr_D_Stat 1;
BA_ "U_U55X_MY2022_Tx" SG_ 939 PrkAidSnsRrCntr_D_Stat 1;
BA_ "U_CD764_MY2022_Tx" SG_ 939 PrkAidSnsRrCntr_D_Stat 1;
BA_ "U_CDX706_MY2023_Tx" SG_ 939 PrkAidSnsRrCntr_D_Stat 1;
BA_ "GenSigSendType" SG_ 939 PrkAidSnsRlCrnr_D_Stat 3;
BA_ "U_T6_MCA_MY2020_Tx" SG_ 939 PrkAidSnsRlCrnr_D_Stat 1;
BA_ "U_CD542_MY2021_Tx" SG_ 939 PrkAidSnsRlCrnr_D_Stat 1;
BA_ "U_U55X_MY2022_Tx" SG_ 939 PrkAidSnsRlCrnr_D_Stat 1;
BA_ "U_CD764_MY2022_Tx" SG_ 939 PrkAidSnsRlCrnr_D_Stat 1;
BA_ "U_CDX706_MY2023_Tx" SG_ 939 PrkAidSnsRlCrnr_D_Stat 1;
BA_ "GenSigSendType" SG_ 939 PrkAidRear_D_Stat 3;
BA_ "U_T6_MCA_MY2020_Tx" SG_ 939 PrkAidRear_D_Stat 1;
BA_ "U_CD542_MY2021_Tx" SG_ 939 PrkAidRear_D_Stat 1;
BA_ "U_U55X_MY2022_Tx" SG_ 939 PrkAidRear_D_Stat 1;
BA_ "U_CD764_MY2022_Tx" SG_ 939 PrkAidRear_D_Stat 1;
BA_ "U_CDX706_MY2023_Tx" SG_ 939 PrkAidRear_D_Stat 1;
BA_ "GenSigSendType" SG_ 939 PrkAidFront_D_Stat 3;
BA_ "U_T6_MCA_MY2020_Tx" SG_ 939 PrkAidFront_D_Stat 1;
BA_ "U_CD542_MY2021_Tx" SG_ 939 PrkAidFront_D_Stat 1;
BA_ "U_U55X_MY2022_Tx" SG_ 939 PrkAidFront_D_Stat 1;
BA_ "U_CD764_MY2022_Tx" SG_ 939 PrkAidFront_D_Stat 1;
BA_ "U_CDX706_MY2023_Tx" SG_ 939 PrkAidFront_D_Stat 1;
BA_ "GenSigSendType" SG_ 939 PrkAid_D_Falt 3;
BA_ "U_T6_MCA_MY2020_Tx" SG_ 939 PrkAid_D_Falt 1;
BA_ "U_CD542_MY2021_Tx" SG_ 939 PrkAid_D_Falt 1;
BA_ "U_U55X_MY2022_Tx" SG_ 939 PrkAid_D_Falt 1;
BA_ "U_CD764_MY2022_Tx" SG_ 939 PrkAid_D_Falt 1;
BA_ "U_CDX706_MY2023_Tx" SG_ 939 PrkAid_D_Falt 1;
BA_ "GenSigSendType" SG_ 939 ApaLongCtrlEnbl_D_Rq 3;
BA_ "U_CX727_MY2021_Rx" SG_ 939 ApaLongCtrlEnbl_D_Rq 1;
BA_ "U_P702_MY2021_Rx" SG_ 939 ApaLongCtrlEnbl_D_Rq 1;
BA_ "U_T6_MCA_MY2020_Rx" SG_ 939 ApaLongCtrlEnbl_D_Rq 1;
BA_ "U_CD542_MY2021_Rx" SG_ 939 ApaLongCtrlEnbl_D_Rq 1;
BA_ "U_U55X_MY2022_Rx" SG_ 939 ApaLongCtrlEnbl_D_Rq 1;
BA_ "U_CD764_MY2022_Rx" SG_ 939 ApaLongCtrlEnbl_D_Rq 1;
BA_ "U_CDX706_MY2023_Rx" SG_ 939 ApaLongCtrlEnbl_D_Rq 1;
BA_ "U_T6_MCA_MY2020_Tx" SG_ 939 ApaLongCtrlEnbl_D_Rq 1;
BA_ "U_CD542_MY2021_Tx" SG_ 939 ApaLongCtrlEnbl_D_Rq 1;
BA_ "U_U55X_MY2022_Tx" SG_ 939 ApaLongCtrlEnbl_D_Rq 1;
BA_ "U_CD764_MY2022_Tx" SG_ 939 ApaLongCtrlEnbl_D_Rq 1;
BA_ "U_CDX706_MY2023_Tx" SG_ 939 ApaLongCtrlEnbl_D_Rq 1;
BA_ "GenSigStartValueInteger" SG_ 939 ApaBrk_A_Rq 255;
BA_ "GenSigStartValue" SG_ 939 ApaBrk_A_Rq 255;
BA_ "U_CX727_MY2021_Rx" SG_ 939 ApaBrk_A_Rq 1;
BA_ "U_P702_MY2021_Rx" SG_ 939 ApaBrk_A_Rq 1;
BA_ "U_T6_MCA_MY2020_Rx" SG_ 939 ApaBrk_A_Rq 1;
BA_ "U_CD542_MY2021_Rx" SG_ 939 ApaBrk_A_Rq 1;
BA_ "U_U55X_MY2022_Rx" SG_ 939 ApaBrk_A_Rq 1;
BA_ "U_CD764_MY2022_Rx" SG_ 939 ApaBrk_A_Rq 1;
BA_ "U_CDX706_MY2023_Rx" SG_ 939 ApaBrk_A_Rq 1;
BA_ "U_T6_MCA_MY2020_Tx" SG_ 939 ApaBrk_A_Rq 1;
BA_ "U_CD542_MY2021_Tx" SG_ 939 ApaBrk_A_Rq 1;
BA_ "U_U55X_MY2022_Tx" SG_ 939 ApaBrk_A_Rq 1;
BA_ "U_CD764_MY2022_Tx" SG_ 939 ApaBrk_A_Rq 1;
BA_ "U_CDX706_MY2023_Tx" SG_ 939 ApaBrk_A_Rq 1;
BA_ "GenSigSendType" SG_ 939 PrkAidLamp_D_Rq 3;
BA_ "U_T6_MCA_MY2020_Tx" SG_ 939 PrkAidLamp_D_Rq 1;
BA_ "U_CD542_MY2021_Tx" SG_ 939 PrkAidLamp_D_Rq 1;
BA_ "U_U55X_MY2022_Tx" SG_ 939 PrkAidLamp_D_Rq 1;
BA_ "U_CD764_MY2022_Tx" SG_ 939 PrkAidLamp_D_Rq 1;
BA_ "U_CDX706_MY2023_Tx" SG_ 939 PrkAidLamp_D_Rq 1;
BA_ "GenSigSendType" SG_ 939 ApaBrk_D_Rq 3;
BA_ "U_T6_MCA_MY2020_Tx" SG_ 939 ApaBrk_D_Rq 1;
BA_ "U_CD542_MY2021_Tx" SG_ 939 ApaBrk_D_Rq 1;
BA_ "U_U55X_MY2022_Tx" SG_ 939 ApaBrk_D_Rq 1;
BA_ "U_CD764_MY2022_Tx" SG_ 939 ApaBrk_D_Rq 1;
BA_ "U_CDX706_MY2023_Tx" SG_ 939 ApaBrk_D_Rq 1;
BA_ "U_CX727_MY2021_Rx" SG_ 937 Veh_V_RqFap 1;
BA_ "U_P702_MY2021_Rx" SG_ 937 Veh_V_RqFap 1;
BA_ "U_T6_MCA_MY2020_Rx" SG_ 937 Veh_V_RqFap 1;
BA_ "U_CD542_MY2021_Rx" SG_ 937 Veh_V_RqFap 1;
BA_ "U_CD764_MY2022_Rx" SG_ 937 Veh_V_RqFap 1;
BA_ "U_CDX706_MY2023_Rx" SG_ 937 Veh_V_RqFap 1;
BA_ "U_T6_MCA_MY2020_Tx" SG_ 937 Veh_V_RqFap 1;
BA_ "U_CD542_MY2021_Tx" SG_ 937 Veh_V_RqFap 1;
BA_ "U_U55X_MY2022_Tx" SG_ 937 Veh_V_RqFap 1;
BA_ "U_CD764_MY2022_Tx" SG_ 937 Veh_V_RqFap 1;
BA_ "U_CDX706_MY2023_Tx" SG_ 937 Veh_V_RqFap 1;
BA_ "MetaData" SG_ 937 TrnRngDRqFap_No_Cs 1;
BA_ "U_CX727_MY2021_Rx" SG_ 937 TrnRngDRqFap_No_Cs 1;
BA_ "U_P702_MY2021_Rx" SG_ 937 TrnRngDRqFap_No_Cs 1;
BA_ "U_T6_MCA_MY2020_Rx" SG_ 937 TrnRngDRqFap_No_Cs 1;
BA_ "U_CD542_MY2021_Rx" SG_ 937 TrnRngDRqFap_No_Cs 1;
BA_ "U_CD764_MY2022_Rx" SG_ 937 TrnRngDRqFap_No_Cs 1;
BA_ "U_CDX706_MY2023_Rx" SG_ 937 TrnRngDRqFap_No_Cs 1;
BA_ "U_T6_MCA_MY2020_Tx" SG_ 937 TrnRngDRqFap_No_Cs 1;
BA_ "U_CD542_MY2021_Tx" SG_ 937 TrnRngDRqFap_No_Cs 1;
BA_ "U_U55X_MY2022_Tx" SG_ 937 TrnRngDRqFap_No_Cs 1;
BA_ "U_CD764_MY2022_Tx" SG_ 937 TrnRngDRqFap_No_Cs 1;
BA_ "U_CDX706_MY2023_Tx" SG_ 937 TrnRngDRqFap_No_Cs 1;
BA_ "MetaData" SG_ 937 TrnRngDRqFap_No_Cnt 1;
BA_ "U_CX727_MY2021_Rx" SG_ 937 TrnRngDRqFap_No_Cnt 1;
BA_ "U_P702_MY2021_Rx" SG_ 937 TrnRngDRqFap_No_Cnt 1;
BA_ "U_T6_MCA_MY2020_Rx" SG_ 937 TrnRngDRqFap_No_Cnt 1;
BA_ "U_CD542_MY2021_Rx" SG_ 937 TrnRngDRqFap_No_Cnt 1;
BA_ "U_CD764_MY2022_Rx" SG_ 937 TrnRngDRqFap_No_Cnt 1;
BA_ "U_CDX706_MY2023_Rx" SG_ 937 TrnRngDRqFap_No_Cnt 1;
BA_ "U_T6_MCA_MY2020_Tx" SG_ 937 TrnRngDRqFap_No_Cnt 1;
BA_ "U_CD542_MY2021_Tx" SG_ 937 TrnRngDRqFap_No_Cnt 1;
BA_ "U_U55X_MY2022_Tx" SG_ 937 TrnRngDRqFap_No_Cnt 1;
BA_ "U_CD764_MY2022_Tx" SG_ 937 TrnRngDRqFap_No_Cnt 1;
BA_ "U_CDX706_MY2023_Tx" SG_ 937 TrnRngDRqFap_No_Cnt 1;
BA_ "U_CX727_MY2021_Rx" SG_ 937 TrnRng_D_RqFap 1;
BA_ "U_P702_MY2021_Rx" SG_ 937 TrnRng_D_RqFap 1;
BA_ "U_T6_MCA_MY2020_Rx" SG_ 937 TrnRng_D_RqFap 1;
BA_ "U_CD542_MY2021_Rx" SG_ 937 TrnRng_D_RqFap 1;
BA_ "U_CD764_MY2022_Rx" SG_ 937 TrnRng_D_RqFap 1;
BA_ "U_CDX706_MY2023_Rx" SG_ 937 TrnRng_D_RqFap 1;
BA_ "U_T6_MCA_MY2020_Tx" SG_ 937 TrnRng_D_RqFap 1;
BA_ "U_CD542_MY2021_Tx" SG_ 937 TrnRng_D_RqFap 1;
BA_ "U_U55X_MY2022_Tx" SG_ 937 TrnRng_D_RqFap 1;
BA_ "U_CD764_MY2022_Tx" SG_ 937 TrnRng_D_RqFap 1;
BA_ "U_CDX706_MY2023_Tx" SG_ 937 TrnRng_D_RqFap 1;
BA_ "GenSigStartValueInteger" SG_ 937 FapLcDistToObj_L_Actl 254;
BA_ "GenSigStartValue" SG_ 937 FapLcDistToObj_L_Actl 254;
BA_ "U_CX727_MY2021_Rx" SG_ 937 FapLcDistToObj_L_Actl 1;
BA_ "U_P702_MY2021_Rx" SG_ 937 FapLcDistToObj_L_Actl 1;
BA_ "U_T6_MCA_MY2020_Rx" SG_ 937 FapLcDistToObj_L_Actl 1;
BA_ "U_CD542_MY2021_Rx" SG_ 937 FapLcDistToObj_L_Actl 1;
BA_ "U_CD764_MY2022_Rx" SG_ 937 FapLcDistToObj_L_Actl 1;
BA_ "U_CDX706_MY2023_Rx" SG_ 937 FapLcDistToObj_L_Actl 1;
BA_ "U_T6_MCA_MY2020_Tx" SG_ 937 FapLcDistToObj_L_Actl 1;
BA_ "U_CD542_MY2021_Tx" SG_ 937 FapLcDistToObj_L_Actl 1;
BA_ "U_U55X_MY2022_Tx" SG_ 937 FapLcDistToObj_L_Actl 1;
BA_ "U_CD764_MY2022_Tx" SG_ 937 FapLcDistToObj_L_Actl 1;
BA_ "U_CDX706_MY2023_Tx" SG_ 937 FapLcDistToObj_L_Actl 1;
VAL_ 992 MsgCntrPersIndex_D_Rq 7 "Unused_3" 6 "Unused_2" 5 "Unused_1" 4 "Vehicle" 3 "PERS_4" 2 "PERS_3" 1 "PERS_2" 0 "PERS_1" ;
VAL_ 992 MsgCntrDsplyOp_D_Rq 7 "Unused_2" 6 "Unused_1" 5 "Copy" 4 "Restore" 3 "Upload" 2 "Set" 1 "Query" 0 "Null" ;
VAL_ 835 AirSprngRateRr_D_Stat 3 "Faulty" 2 "Firm" 1 "Medium" 0 "Soft" ;
VAL_ 835 AirSprngRateRl_D_Stat 3 "Faulty" 2 "Firm" 1 "Medium" 0 "Soft" ;
VAL_ 835 AirSprngRateFr_D_Stat 3 "Faulty" 2 "Firm" 1 "Medium" 0 "Soft" ;
VAL_ 835 AirSprngRateFl_D_Stat 3 "Faulty" 2 "Firm" 1 "Medium" 0 "Soft" ;
VAL_ 835 RideHghtMde_D_Stat 15 "Faulty" 14 "NotUsed_5" 13 "NotUsed_4" 12 "NotUsed_3" 11 "NotUsed_2" 10 "NotUsed_1" 9 "AdjUpAero" 8 "AdjUpOffRoad" 7 "AdjUpNormal" 6 "AdjDownKneel" 5 "AdjDownAero" 4 "AdjDownNormal" 3 "OffRoad" 2 "Kneel" 1 "Aero" 0 "Normal" ;
VAL_ 820 TailLghtAnmtn_D_Stat 15 "Faulty" 14 "NotUsed_8" 13 "NotUsed_7" 12 "NotUsed_6" 11 "NotUsed_5" 10 "NotUsed_4" 9 "NotUsed_3" 8 "NotUsed_2" 7 "NotUsed_1" 6 "Type6" 5 "Type5" 4 "Type4" 3 "Type3" 2 "Type2" 1 "Type1" 0 "Null" ;
VAL_ 820 AhbStatGfhbFdbk_D_Actl 3 "GfhbHighBeamFullyOn" 2 "GfhbHighBeamPartlyOn" 1 "GfhbHighBeamOff" 0 "GfhbUnavailable" ;
VAL_ 820 HeadLghtDrvSide_B_Stat 1 "Left_Hand_Traffic" 0 "Right_Hand_Traffic" ;
VAL_ 820 HeadLghtHiOn_B_StatHcm 1 "On" 0 "Off" ;
VAL_ 820 Adaptive_Hdlmp_Fault 1 "Yes" 0 "No" ;
VAL_ 820 TurnLampFrOut_B_Stat 1 "Out" 0 "Null" ;
VAL_ 820 TurnLampFlOut_B_Stat 1 "Out" 0 "Null" ;
VAL_ 817 ChildLckMde_B_Stat 1 "Enable" 0 "Disable" ;
VAL_ 817 VehLckInd_D_Rq 3 "NotUsed" 2 "On_Day" 1 "On_Night" 0 "Off" ;
VAL_ 817 DrTgateOpen_B_Rq 1 "Open" 0 "Null" ;
VAL_ 817 DrTgateExtSwMde_B_Stat 1 "Enable" 0 "Disable" ;
VAL_ 817 Remote_Device_Feedback 7 "Unused3" 6 "Unused2" 5 "Unused1" 4 "Shutdown" 3 "Running" 2 "Starting" 1 "Acknowledge" 0 "Null" ;
VAL_ 817 Veh_Lock_Requestor 31 "Walk_Away_Locking" 30 "Remote_Park_Assist" 29 "DoorsOffToOn_Smart_Unlock" 28 "Rgtm_Shutlock_Switch" 27 "Boundary_Alert" 26 "Transit_Vehicle_Relock" 25 "Transit_Cargo_Relock" 24 "Transit_Ajar_Lock" 23 "Diagnostics" 22 "Console_Lock" 21 "Child_Lock" 20 "Double_Lock" 19 "Passive_Pasenger" 18 "Passive_Driver" 17 "Slam_Lock_Protect" 16 "SYNC" 15 "Passport" 14 "Passive_Smart_Unlock" 13 "Autorelock" 12 "RemoteStart" 0 "Null" 1 "Autolock" 11 "Smart_Unlock" 10 "Sliding_Door" 9 "Passive" 8 "Remote" 7 "Programming" 6 "Powerslide" 5 "Keypad" 4 "Key_Cylinder" 3 "Interior" 2 "Auto_Unlock" ;
VAL_ 817 R_Pwr_Sliding_Dr_Rqst 1 "Active" 0 "Null" ;
VAL_ 817 Power_Liftgate_Rqst 1 "Active" 0 "Null" ;
VAL_ 817 Power_Decklid_Rqst 1 "Active" 0 "Null" ;
VAL_ 817 L_Pwr_Sliding_Dr_Rqst 1 "Active" 0 "Null" ;
VAL_ 817 Veh_Lock_Sub_Id 15 "Unused7" 14 "Unused6" 13 "Unused5" 12 "Unused4" 11 "Unused3" 10 "Unused2" 9 "Unused1" 8 "Customer_8" 7 "Customer_7" 6 "Customer_6" 5 "Customer_5" 4 "Customer_4" 3 "Customer_3" 2 "Customer_2" 1 "Customer_1" 0 "Null" ;
VAL_ 817 Veh_Lock_Status 3 "UNLOCK_DRV" 2 "UNLOCK_ALL" 1 "LOCK_ALL" 0 "LOCK_DBL" ;
VAL_ 817 ChildLck_D_Dsply 3 "NOT_SUPPORTED" 2 "ERROR" 1 "CHILD_UNLOCK" 0 "CHILD_LOCK" ;
VAL_ 817 WindowLockout_B_Stat 1 "Locked" 0 "Unlock" ;
VAL_ 817 Lockmsgtxt_D_Rq 7 "MSG7" 6 "MSG6" 5 "MSG5" 4 "MSG4" 3 "MSG3" 2 "MSG2" 1 "MSG1" 0 "NO_WARNING" ;
VAL_ 817 FobComm_D_Stat 3 "NotUsed" 2 "RemEngStartOK" 1 "RemEngStartFail" 0 "Null" ;
VAL_ 817 LockInhibit 1 "Inhibit" 0 "No_Inhibit" ;
VAL_ 137 SteWhlOffstRq_D_Stat 3 "Faulty" 2 "NoDataExists" 1 "Allow_External_Angle_Req" 0 "Deny_External_Angle_Req" ;
VAL_ 137 SteWhlOffst_An_TotActl 32767 "Faulty" 32766 "NoDataExists" ;
VAL_ 137 SteWhlBrkOffst_An_Actl 32767 "Faulty" 32766 "NoDataExists" ;
VAL_ 129 SelDrvMdeSwtch4_D_Stat4 3 "Faulty" 2 "Pressed" 1 "NotPressed" 0 "Null" ;
VAL_ 129 EngExhMdeQuiet_B_RqDrv2 1 "Pressed" 0 "Not_Pressed" ;
VAL_ 129 SelDrvMdeSwtch_D_Stat4 3 "Faulty" 2 "SwitchState2" 1 "SwitchState1" 0 "NotPressed" ;
VAL_ 129 SteWhlSwtchView_B_Stat 1 "Pressed" 0 "Not_Pressed" ;
VAL_ 129 SteWhlSwtchSet_B_Stat 1 "Pressed" 0 "Not_Pressed" ;
VAL_ 129 SteWhlSwtchPhon_B_Stat 1 "Pressed" 0 "Not_Pressed" ;
VAL_ 129 SteWhlSwtchNav_B_Stat 1 "Pressed" 0 "Not_Pressed" ;
VAL_ 129 SteWhlSwtchMed_B_Stat 1 "Pressed" 0 "Not_Pressed" ;
VAL_ 129 SteWhlSwtchIod_B_Stat 1 "Pressed" 0 "Not_Pressed" ;
VAL_ 129 SteWhlSwtchHud_B_Stat 1 "Pressed" 0 "Not_Pressed" ;
VAL_ 129 SteWhlSwtchBack_B_Stat 1 "Pressed" 0 "Not_Pressed" ;
VAL_ 129 SteWhlSwtchMenu_B_Stat 1 "Pressed" 0 "Not_Pressed" ;
VAL_ 129 SteEffortInc_B_RqDrv 1 "Pressed" 0 "Not_Pressed" ;
VAL_ 129 SelDrvMdeInc_B_RqDrv 1 "Pressed" 0 "Not_Pressed" ;
VAL_ 129 SelDrvMdeDec_B_RqDrv 1 "Pressed" 0 "Not_Pressed" ;
VAL_ 129 SuspDampInc_B_RqDrv 1 "Pressed" 0 "Not_Pressed" ;
VAL_ 129 SteWhlSwtchUp_B_Stat 1 "Pressed" 0 "Not_Pressed" ;
VAL_ 129 SteWhlSwtchRght_B_Stat 1 "Pressed" 0 "Not_Pressed" ;
VAL_ 129 SteWhlSwtchOk_B_Stat 1 "Pressed" 0 "Not_Pressed" ;
VAL_ 129 SteWhlSwtchLeft_B_Stat 1 "Pressed" 0 "Not_Pressed" ;
VAL_ 129 SteWhlSwtchDown_B_Stat 1 "Pressed" 0 "Not_Pressed" ;
VAL_ 129 SteWhlSwtchHome_B_Stat 1 "Pressed" 0 "Not_Pressed" ;
VAL_ 129 SteWhlSwtchInfo_B_Stat 1 "Pressed" 0 "Not_Pressed" ;
VAL_ 129 PoliceAux4Swtch_B_Stat 1 "Switch_Active" 0 "Switch_Not_Active" ;
VAL_ 129 PoliceAux3Swtch_B_Stat 1 "Switch_Active" 0 "Switch_Not_Active" ;
VAL_ 129 PoliceAux2Swtch_B_Stat 1 "Switch_Active" 0 "Switch_Not_Active" ;
VAL_ 129 PoliceAux1Swtch_B_Stat 1 "Switch_Active" 0 "Switch_Not_Active" ;
VAL_ 129 SelDrvMdeSwtch3_D_Stat4 3 "Faulty" 2 "Pressed" 1 "NotPressed" 0 "Null" ;
VAL_ 129 SelDrvMdeSwtch2_D_Stat4 3 "Faulty" 2 "Pressed" 1 "NotPressed" 0 "Null" ;
VAL_ 129 SelDrvMdeSwtch1_D_Stat4 3 "Faulty" 2 "Pressed" 1 "NotPressed" 0 "Null" ;
VAL_ 854 Dsp_RotAddrBtnEv_St 15 "NotUsed_1" 14 "Pos_7Steps" 13 "Pos_6Steps" 12 "Pos_5Steps" 11 "Pos_4Steps" 10 "Pos_3Steps" 9 "Pos_2Steps" 8 "Pos_1Step" 7 "NotPressed" 6 "Neg_1Steps" 5 "Neg_2Steps" 4 "Neg_3Steps" 3 "Neg_4Steps" 2 "Neg_5Steps" 1 "Neg_6Steps" 0 "Neg_7Steps" ;
VAL_ 854 SelDrvMdeButtn_B_Stat 1 "Pressed" 0 "Not_Pressed" ;
VAL_ 854 SteEffortButtn_B_Stat 1 "Pressed" 0 "Not_Pressed" ;
VAL_ 854 SelDrvMdeSwtch_D_Stat2 3 "Faulty" 2 "SwitchState2" 1 "SwitchState1" 0 "NotPressed" ;
VAL_ 854 CC_Fr_Stat_User_Adj 7 "Unused4" 6 "RHS_AUTO_St_Selection" 5 "LHS_AUTO_St_Selection" 4 "DrvrFcsdMde_Selection" 3 "Fr_Blwr_Spd_Selection" 2 "FRHS_SetPt_Selection" 1 "FLHS_SetPt_Selection" 0 "None" ;
VAL_ 854 EngExhMdeQuiet_B_RqDrv 1 "Pressed" 0 "Not_Pressed" ;
VAL_ 854 LnchCtlSys_B_RqDrv 1 "Pressed" 0 "Not_Pressed" ;
VAL_ 854 Front_Blower_Indicate 15 "Display_Blank" 14 "14_Indicators_On" 13 "13_Indicators_On" 12 "12_Indicators_On" 11 "11_Indicators_On" 10 "10_Indicators_On" 9 "9_Indicators_On" 8 "8_Indicators_On" 7 "7_Indicators_On" 6 "6_Indicators_On" 5 "5_Indicators_On" 4 "4_Indicators_On" 3 "3_Indicators_On" 2 "2_Indicators_On" 1 "1_Indicator_On" 0 "Indicators_Off" ;
VAL_ 854 CC_Diagnostics_Active 1 "Yes" 0 "No" ;
VAL_ 854 RHS_Temp_Display_Digit3 2 "_5" 1 "_0" 0 "OFF" ;
VAL_ 854 LHS_Temp_Display_Digit3 2 "_5" 1 "_0" 0 "OFF" ;
VAL_ 854 EATC_RHS_Units 2 "Fahrenheit" 1 "Celsius" 0 "Off" ;
VAL_ 854 EATC_LHS_Units 2 "Fahrenheit" 1 "Celsius" 0 "Off" ;
VAL_ 854 LHS_Auto_Seat_Btn_Stt 3 "Unused" 2 "Disabled" 1 "Active" 0 "Enabled_Inactive" ;
VAL_ 854 RHS_Auto_Seat_Btn_Stt 3 "Unused" 2 "Disabled" 1 "Active" 0 "Enabled_Inactive" ;
VAL_ 549 SpeedChngChime_D_Rq2 3 "NotUsed" 2 "On" 1 "Off" 0 "Null" ;
VAL_ 549 CCOI_PolicyClient_St2 15 "NotUsed_4" 14 "NotUsed_3" 13 "NotUsed_2" 12 "NotUsed_1" 11 "DataStorageError" 10 "StateMachineInconsistent" 9 "UnrecoverableSyncError" 8 "OnBoardSyncFailed" 7 "OnBoardImplemented" 6 "OnBoardSynchronized" 5 "OnBoardSynchronizing" 4 "OnBoardSyncNeeded" 3 "OffBoardUpdatePending" 2 "OnBoardUpdatePending" 1 "Waiting" 0 "Null" ;
VAL_ 549 FactoryReset_Rq2 1 "ResetFactoryDefaults" 0 "Inactive" ;
VAL_ 549 TjaLcEnbl_D_DrvRq 0 "Inactive" 1 "Off" 2 "On" 3 "NotUsed" ;
VAL_ 549 BattTracLoThres_D_Rq2 7 "NotUsed" 6 "Thres80km_50mi" 5 "Thres50km_31mi" 4 "Thres30km_18mi" 3 "Thres50mi_80km" 2 "Thres30mi_48km" 1 "Thres20mi_32km" 0 "Null" ;
VAL_ 549 NavIod_D_Rq 7 "NotUsed_5" 6 "NotUsed_4" 5 "NotUsed_3" 4 "NotUsed_2" 3 "NotUsed_1" 2 "ModeChange" 1 "VideoOutput" 0 "NoRequest" ;
VAL_ 549 IPC_MyKeyVolLimit_St 0 "Invalid" 1 "Off" 2 "On" ;
VAL_ 549 HdcOn_B_Rq 1 "On" 0 "Off" ;
VAL_ 549 IPC_Attn_Info_Audio 7 "Unknown" 6 "Attenuation_6" 5 "Attenuation_5" 4 "Attenuation_4" 3 "Attenuation_3" 2 "Attenuation_2" 1 "Attenuation_1" 0 "No_Attenuation_of_Audio" ;
VAL_ 549 BeltminderAudioMute 2 "On" 1 "Off" 0 "Invalid" ;
VAL_ 549 Power_Up_Chime_Modules 1 "Active" 0 "Inactive" ;
VAL_ 549 Chime_Source 2 "Cluster" 1 "Infotainment_Sys" 0 "Invalid" ;
VAL_ 549 IPC_New_Attn_Event 1 "Active" 0 "Inactive" ;
VAL_ 549 WwaActv_B_Stat 1 "Active" 0 "Inactive" ;
VAL_ 549 MetricActv_B_Dsply 1 "Active" 0 "Inactive" ;
VAL_ 549 HudVertSzMnuOn_B_Rq 1 "On" 0 "Off" ;
VAL_ 549 HudVertMnuOn_B_Rq 1 "Yes" 0 "No" ;
VAL_ 549 HudRotatMnuOn_B_Rq 1 "Yes" 0 "No" ;
VAL_ 549 HudCntntMnuOn_B_Rq 1 "On" 0 "Off" ;
VAL_ 549 HudBrightMnuOn_B_Rq 1 "Yes" 0 "No" ;
VAL_ 549 StrtInGearOk_D_Stat 3 "NotUsed" 2 "Accepted" 1 "NotAccepted" 0 "Null" ;
VAL_ 935 CtaAlrtRight2_D_Stat 7 "NotUsed3" 6 "NotUsed2" 5 "NotUsed1" 4 "AlertZone4" 3 "AlertZone3" 2 "AlertZone2" 1 "AlertZone1" 0 "Off" ;
VAL_ 935 BttRight_D_Stat 7 "BTT5GFault" 6 "Disabled" 5 "Off" 4 "OffTemp" 3 "NotConnected" 2 "Pending" 1 "Connected" 0 "NotDetermined" ;
VAL_ 935 BttRight_D_RqDrv 3 "NotUsed" 2 "Request" 1 "NoRequest" 0 "Null" ;
VAL_ 935 CtaBrkRightMsgTxt_B_Rq 1 "Enable" 0 "Disable" ;
VAL_ 935 CtaRightBrkEnbl_B_Rq 1 "Enable" 0 "Disable" ;
VAL_ 935 CtaRightBrkDecel_B_Rq 1 "Enable" 0 "Disable" ;
VAL_ 935 CtaSnsRight_D_Stat 3 "Invalid" 2 "System_Failure" 1 "Blocked" 0 "Clear" ;
VAL_ 935 CtaAlrtRight_D_Stat 1 "On" 0 "Off" ;
VAL_ 935 CtaRight_D_Stat 7 "NotUsed_3" 6 "NotUsed_2" 5 "NotUsed_1" 4 "Invalid" 3 "Disabled" 2 "On" 1 "Trailer_Tow_Off" 0 "Off" ;
VAL_ 935 SodRight_D_Stat 7 "NotUsed_3" 6 "NotUsed_2" 5 "NotUsed_1" 4 "Invalid" 3 "Disabled" 2 "On" 1 "Trailer_Tow_Off" 0 "Off" ;
VAL_ 935 SodSnsRight_D_Stat 3 "Second_Warning_Audio" 2 "System_Failure" 1 "Blocked" 0 "Clear" ;
VAL_ 935 SodAlrtRight_D_Stat 3 "Bulb_Proveout" 2 "Flash" 1 "On" 0 "Off" ;
VAL_ 935 SodDetctRight_D_Stat 4 "Sensor_Blocked" 3 "Sensor_Fault" 2 "Flash_On" 1 "Alert_On" 0 "AlertOff_FlashOff_SensrClr" ;
VAL_ 1108 RCMSerialNoByte8 255 "Invalid" 254 "Unknown" ;
VAL_ 1108 RCMSerialNoByte7 255 "Invalid" 254 "Unknown" ;
VAL_ 1108 RCMSerialNoByte6 255 "Invalid" 254 "Unknown" ;
VAL_ 1108 RCMSerialNoByte5 255 "Invalid" 254 "Unknown" ;
VAL_ 1108 RCMSerialNoByte4 255 "Invalid" 254 "Unknown" ;
VAL_ 1108 RCMSerialNoByte3 255 "Invalid" 254 "Unknown" ;
VAL_ 1108 RCMSerialNoByte2 255 "Invalid" 254 "Unknown" ;
VAL_ 1108 RCMSerialNoByte1 255 "Invalid" 254 "Unknown" ;
VAL_ 261 ChrgStatDsply_D_Rq 3 "NotUsed_2" 2 "NotUsed_1" 1 "On" 0 "Off" ;
VAL_ 261 NextUsageTimeToggle_Rq 0 "Inactive" 2 "Disable" 1 "Enable" ;
VAL_ 261 LongTermParking_Rq 2 "On" 1 "Off" 0 "Inactive" ;
VAL_ 261 ModemReset_D_Rq 15 "NotUsed_11" 14 "NotUsed_10" 13 "NotUsed_9" 12 "NotUsed_8" 11 "NotUsed_7" 10 "NotUsed_6" 9 "NotUsed_5" 8 "NotUsed_4" 7 "NotUsed_3" 6 "BrandConnectReset2" 5 "BrandConnectReset1" 4 "CcsReset" 3 "OnlineTrafficReset" 2 "PaakReset" 1 "WifiHotspotReset" 0 "Null" ;
VAL_ 261 StopStrtDrvMde_B_RqBtn3 1 "Pressed" 0 "Not_Pressed" ;
VAL_ 261 TCU_ESN_D_Rq 3 "NotUsed" 2 "TCU_ESN_Request" 1 "NoRequest" 0 "Inactive" ;
VAL_ 261 FactoryReset_Rq 1 "ResetFactoryDefaults" 0 "Inactive" ;
VAL_ 1146 TrlrAidSwtch_D_RqDrv 3 "Faulty" 2 "NotUsed" 1 "Pressed" 0 "Not_Pressed" ;
VAL_ 1146 TrlrAidCtl_U_RqDrv 4095 "Faulty" 4094 "NoDataExists" ;
VAL_ 533 TjaLcEnbl_D_RqMnu 3 "NotUsed" 2 "On" 1 "Off" 0 "Null" ;
VAL_ 533 ExtLghtRvrseOn_B_Rq 1 "On" 0 "Off" ;
VAL_ 533 ClrExitAsstEnbl_D_RqMnu 3 "NotUsed" 0 "Inactive" 2 "Enable" 1 "Disable" ;
VAL_ 533 TrlrAidMde_D_Rq 3 "Mode_3" 2 "Mode_2" 1 "Mode_1" 0 "NoRequest" ;
VAL_ 533 TCU_Init_Actvtn_St 3 "NotUsed" 2 "InitialActivateDeny" 1 "InitialActivateAccept" 0 "Invalid" ;
VAL_ 533 TCU_Final_Actvtn_St 3 "NotUsed" 2 "FinalActivateDeny" 1 "FinalActivateAccept" 0 "Invalid" ;
VAL_ 533 OtaTrg_D_Stat 3 "NotUsed_1" 2 "Accepted" 1 "NotAccepted" 0 "Null" ;
VAL_ 533 OnbChrgGoTTouch_D_Rq 3 "NotUsed" 2 "On" 1 "Off" 0 "Null" ;
VAL_ 533 OnbChrgGoTPrcond_D_Rq 3 "High" 2 "Medium" 1 "Low" 0 "Off" ;
VAL_ 533 OnbChrgGoTOn_D_Rq 3 "NotUsed" 2 "On" 1 "Off" 0 "Null" ;
VAL_ 533 OnbChrgGoTMnte_D_Rq 15 "NotUsed_4" 14 "NotUsed_3" 13 "NotUsed_2" 12 "NotUsed_1" 11 "Minute_55" 10 "Minute_50" 9 "Minute_45" 8 "Minute_40" 7 "Minute_35" 6 "Minute_30" 5 "Minute_25" 4 "Minute_20" 3 "Minute_15" 2 "Minute_10" 1 "Minute_5" 0 "Minute_0" ;
VAL_ 533 OnbChrgGoTHr_T_Rq 31 "Faulty" 30 "NoDataExists" ;
VAL_ 533 OnbChrgGoTExtHtr_D_Rq 3 "NotUsed" 2 "On" 1 "Off" 0 "Null" ;
VAL_ 533 OnbChrgGoTDelete_B_Rq 1 "Request" 0 "NoRequest" ;
VAL_ 533 OnbChrgClearAll_B_Rq 1 "Request" 0 "NoRequest" ;
VAL_ 533 PaakMyKey_D_Rq 3 "NotUsed" 2 "ConfirmNewPaakMyKey" 1 "RequestNewPaakMyKey" 0 "None" ;
VAL_ 533 AutoEpbZoomView_B_Stat 1 "Active" 0 "Inactive" ;
VAL_ 533 AutoEpbButtn_B_Stat 1 "Pressed" 0 "Not_Pressed" ;
VAL_ 533 DcacPw_D_Rq 3 "High" 2 "Low" 1 "Off" 0 "Null" ;
VAL_ 533 DcacPwReset_B_Rq 1 "Reset" 0 "Null" ;
VAL_ 533 LghtAmbDrvMde_D_Rq 3 "NotUsed" 2 "Automatic" 1 "Manual" 0 "Null" ;
VAL_ 533 DcacPwLoButtn_B_Stat 1 "Pressed" 0 "Not_Pressed" ;
VAL_ 533 DcacPwOffButtn_B_Stat 1 "Pressed" 0 "Not_Pressed" ;
VAL_ 533 DcacPwHiButtn_B_Stat 1 "Pressed" 0 "Not_Pressed" ;
VAL_ 533 DcacPwResetButtn_B_Stat 1 "Pressed" 0 "Not_Pressed" ;
VAL_ 533 DcacPwButtn_B_Falt 1 "Faulted" 0 "NotFaulted" ;
VAL_ 533 OnbChrgGoTUpdate_B_Rq 1 "Request" 0 "NoRequest" ;
VAL_ 533 TrlrAlarmButtn_B_Stat 1 "On" 0 "Off" ;
VAL_ 533 DcacMdeButtn_B_Stat 1 "Pressed" 0 "Not_Pressed" ;
VAL_ 533 DcacGfciTestBttn_B_Stat 1 "Pressed" 0 "Not_Pressed" ;
VAL_ 533 TrlrHitch_D_RqMnu 15 "NotUsed_10" 14 "NotUsed_9" 13 "NotUsed_8" 12 "NotUsed_7" 11 "NotUsed_6" 10 "NotUsed_5" 9 "NotUsed_4" 8 "NotUsed_3" 7 "NotUsed_2" 6 "NotUsed_1" 5 "GoToTraileringDomain" 4 "Confirm" 3 "TurnOnTba" 2 "TurnOnAutohitch" 1 "CancelAutohitch" 0 "NoRequest" ;
VAL_ 533 DcacPwButtn_B_Stat 1 "Pressed" 0 "Not_Pressed" ;
VAL_ 778 PrkAidAcsyRear_D_RqDrv 3 "NotUsed" 2 "On" 1 "Off" 0 "Null" ;
VAL_ 778 PrkAidAcsyFront_D_RqDrv 3 "NotUsed" 2 "On" 1 "Off" 0 "Null" ;
VAL_ 778 Cta_D_Rq 3 "Unused" 2 "NoDataExists" 1 "On" 0 "Off" ;
VAL_ 778 PrkAidRear_D_RqDrv 2 "Status" 3 "NotUsed" 1 "Enabled" 0 "Disabled" ;
VAL_ 778 PrkAidFront_D_RqDrv 2 "Status" 3 "NotUsed" 1 "Enabled" 0 "Disabled" ;
VAL_ 778 SteEffort_D_Rq 7 "NotUsed_3" 6 "NotUsed_2" 5 "NotUsed_1" 4 "SpecialMode_2" 3 "SpecialMode_1" 2 "Comfort" 1 "Sport" 0 "Normal" ;
VAL_ 778 Sod_D_Rq 3 "No_Selection_Made" 2 "BLIS_On_Second_Warning_ON" 1 "BLIS_On_Second_Warning_OFF" 0 "Off" ;
VAL_ 778 ClrExitAsstEnbl_D_RqDrv 3 "NotUsed" 0 "Inactive" 2 "Enable" 1 "Disable" ;
VAL_ 1041 ElCmprUHi_D_Stat 3 "Overvoltage" 2 "Undervoltage" 1 "InRange" 0 "Undetermined" ;
VAL_ 1041 ElCmprOverTe_D_Stat 3 "OverTempStop" 2 "OverTempWarning" 1 "Normal" 0 "Undefined" ;
VAL_ 1041 ElCmpr_N_Actl 255 "Invalid" ;
VAL_ 1041 ElCmpr_Pw_Actl 255 "Invalid" ;
VAL_ 1041 ElCmpr_D_Stat 7 "Signal_Invalid" 6 "Comp_Off_ActlSpd_Abnormal" 5 "Comp_Off_TrgtSpd_OutRange" 4 "Comp_Shutdown" 3 "Comp_Stopped_Self_Protect" 2 "Comp_Degraded" 1 "Comp_On" 0 "Comp_Off" ;
VAL_ 1041 ElCmprPerfErr_D_Falt 3 "NotUsed" 2 "Pass" 1 "Fail" 0 "Not_Diagnose_Yet" ;
VAL_ 1041 ElCmprInnrErr_D_Falt 3 "NotUsed" 2 "Pass" 1 "Fail" 0 "Not_Diagnose_Yet" ;
VAL_ 1041 ElCmprLostComm_D_Falt 3 "NotUsed" 2 "Pass" 1 "Fail" 0 "Not_Diagnose_Yet" ;
VAL_ 1041 ElCmprOverLoad_D_Falt 3 "NotUsed" 2 "Pass" 1 "Fail" 0 "Not_Diagnose_Yet" ;
VAL_ 1041 ElCmprOverTe_D_Falt 3 "NotUsed" 2 "Pass" 1 "Fail" 0 "Not_Diagnose_Yet" ;
VAL_ 1041 ElCmprBattURng_D_Falt 3 "NotUsed" 2 "Pass" 1 "Fail" 0 "Not_Diagnose_Yet" ;
VAL_ 1041 ElCmprBattSysU_D_Falt 3 "NotUsed" 2 "Pass" 1 "Fail" 0 "Not_Diagnose_Yet" ;
VAL_ 1041 ElCmprSysU_D_Falt 3 "NotUsed" 2 "Pass" 1 "Fail" 0 "Not_Diagnose_Yet" ;
VAL_ 1067 BattULoAux_U_Rq 4095 "Faulty" ;
VAL_ 1067 BattULoAuxIsol_D_Rq 3 "Undefined" 2 "Retain" 1 "Close" 0 "Open" ;
VAL_ 1067 BattULoAux_I_Actl 4095 "Faulty" ;
VAL_ 1067 BattULoAux_D_Qlty 3 "OK" 2 "Not_Within_Specifications" 1 "Eval_In_Progress" 0 "Faulty" ;
VAL_ 1067 BattULoAux_U_Actl 255 "Faulty" ;
VAL_ 1067 BattULoAux_B_Falt 1 "Fault" 0 "No_Fault" ;
VAL_ 1118 BptTgl_B_Complt 1 "Yes" 0 "No" ;
VAL_ 1118 AcChrgRdy_B_Stat 1 "True" 0 "False" ;
VAL_ 1118 DgtlCommGtwyMde_D_Rq 15 "NotUsed_10" 14 "NotUsed_9" 13 "NotUsed_8" 12 "NotUsed_7" 11 "NotUsed_6" 10 "NotUsed_5" 9 "NotUsed_4" 8 "NotUsed_3" 7 "NotUsed_2" 6 "NotUsed_1" 5 "AcPnC" 4 "AcEIM" 3 "DcPnC" 2 "DcEIM" 1 "AttemptDgtlComm" 0 "NoDgtlComm" ;
VAL_ 1118 ExtChrgNowButtn_B_Rq 1 "Request" 0 "NoRequest" ;
VAL_ 1118 CoolFanChrgr_D_Rq 3 "High" 2 "Medium" 1 "Low" 0 "Off" ;
VAL_ 1118 ChrgrClntFlw_D_Rq 3 "High" 2 "Medium" 1 "Low" 0 "Off" ;
VAL_ 1118 PlgStatEvnt_B_Stat 1 "Active" 0 "Inactive" ;
VAL_ 1118 ChrgrCnnctPwr_B_Stat 1 "Asserted" 0 "NotAsserted" ;
VAL_ 1118 ChrgrAvailEvnt_B_Stat 1 "Active" 0 "Inactive" ;
VAL_ 1118 ChrgrSrvcRqd_B_Rq 1 "On" 0 "Off" ;
VAL_ 1118 ChrgrS2Swtch_B_Stat 1 "Close" 0 "Open" ;
VAL_ 1118 ChrgChngEvnt_B_Stat 1 "Active" 0 "Inactive" ;
VAL_ 1118 ChrgCordLck_D_Stat 7 "Faulty" 6 "LockFail" 5 "UnlockFail" 4 "LockInProgress" 3 "UnlockInProgress" 2 "Lock" 1 "Unlock" 0 "Retain" ;
VAL_ 1118 ChrgrInPwMde_D_Actl 15 "NotUsed_5" 14 "NotUsed_4" 13 "NotUsed_3" 12 "NotUsed_2" 11 "NotUsed_1" 10 "DcBpt" 9 "DigitalCommEnd" 8 "EvseFault" 7 "EvseNotCompatible" 6 "IcCharging" 5 "DcCharging" 4 "AcDigital" 3 "AcBasic" 2 "DigitalCommDetected" 1 "EvsePaused" 0 "EvseNotDetected" ;
VAL_ 1118 ChrgPortDrOpen_B_Stat 1 "True" 0 "False" ;
VAL_ 1118 ChrgrDcOvrVolt_B_Falt 1 "Yes" 0 "No" ;
VAL_ 1118 ChrgrDcOvrCurnt_B_Falt 1 "Yes" 0 "No" ;
VAL_ 1118 ChrgrPncEnbl_D_Stat 3 "NotUsed" 2 "Enable" 1 "Disable" 0 "Null" ;
VAL_ 1118 ChrgrCc2Cnnct_B_Falt 1 "Yes" 0 "No" ;
VAL_ 1118 ChrgPortDcTeMx_B_Falt 1 "Yes" 0 "No" ;
VAL_ 1118 ChrgCrdLck_D_Falt 3 "NotUsed" 2 "HardwareFault" 1 "CsiFault" 0 "NoFault" ;
VAL_ 1040 RoadGrd_Pc_Est 1023 "Faulty" ;
VAL_ 1040 ElCmpr2Enbl_B_Rq 1 "Enable" 0 "Disable" ;
VAL_ 1040 ElCmprEnbl_B_Rq 1 "Enable" 0 "Disable" ;
VAL_ 1040 BattTrac_I2_EstVsc 262143 "Faulty" 262142 "NoDataExists" ;
VAL_ 1144 AwdLckMde_D_Stat 7 "NotUsed_2" 6 "NotUsed_1" 5 "PrimaryAxleSpeedControl" 4 "DualAxleSpeedControl" 3 "EfficiencySplit" 2 "SecondaryAxleTorqueCtrl" 1 "SecondaryAxleSpeedCtrl" 0 "Off" ;
VAL_ 1144 BattTracCool_B_Actl 1 "On" 0 "Off" ;
VAL_ 1144 BattChrgTrgtSoC_D_Rq 7 "Percent_50" 6 "Percent_60" 5 "Percent_70" 4 "Percent_80" 3 "Percent_85" 2 "Percent_90" 1 "Percent_95" 0 "Percent_100" ;
VAL_ 1144 CabnEvapSovFront_B_Rq 1 "On" 0 "Off" ;
VAL_ 1144 HeatCoreSovRear_B_Rq 1 "On" 0 "Off" ;
VAL_ 1144 BattChlrSov_B_Rq 1 "On" 0 "Off" ;
VAL_ 1144 CabnEvapSovRear_B_Rq 1 "On" 0 "Off" ;
VAL_ 1144 BrkAppl_D_RqPt 3 "BrakesSlowRelease" 2 "BrakesFastRelease" 1 "BrakesEngage" 0 "NotActive" ;
VAL_ 1144 BattClntVlvOvrrd_D_Rq 3 "NotUsed" 2 "OverrideTbcvToChiller" 1 "OverrideTbcvToRadiator" 0 "NoOverrideToTbcvCLogic" ;
VAL_ 1144 BattTracChillerOn_B_Rq 1 "On" 0 "Off" ;
VAL_ 1144 BattTracChiller_D_Stat 3 "NotUsed" 2 "ChillerNotAvailable" 1 "ChillerBrieflyAvailable" 0 "ChillerAvailable" ;
VAL_ 1144 HtrnDcdcDis_B_Rq 1 "Yes" 0 "No" ;
VAL_ 1144 HtrnCnnctPwr_B_Stat 1 "Asserted" 0 "NotAsserted" ;
VAL_ 1144 PtcHtr_D_Stat 3 "Faulty" 2 "NotUsed" 1 "On" 0 "Off" ;
VAL_ 1144 WakeAlarm0_B_Typ 1 "CanAndEcuDriveCircuit" 0 "CanOnly" ;
VAL_ 1144 HtrnClntFlw_D_Rq 3 "High" 2 "Medium" 1 "Low" 0 "Off" ;
VAL_ 1144 BattTracDrvSustn_B_Rq 1 "Active" 0 "Inactive" ;
VAL_ 1144 CabinDrvSustn_B_Rq 1 "Active" 0 "Inactive" ;
VAL_ 1144 ChrgNowEvnt_B_Stat 1 "Active" 0 "Inactive" ;
VAL_ 1144 PreCondBatt_B_Actl 1 "On" 0 "Off" ;
VAL_ 1144 BattTracClntVlv_B_Rq 1 "On" 0 "Off" ;
VAL_ 1144 ULoBattTrnsfrSustn_B_Rq 1 "Active" 0 "Inactive" ;
VAL_ 1144 ULoBattTransfer_D_Stat 7 "NotUsed_2" 6 "NotUsed_1" 5 "TransferError" 4 "TransferComplete" 3 "TransferThroughGridEnergy" 2 "InsufficientEnergyToXfer" 1 "TransferInProgress" 0 "NoTransfer" ;
VAL_ 1144 BattChrgInhbt_D2_Rq 7 "NotUsed_4" 6 "NotUsed_3" 5 "NotUsed_2" 4 "NotUsed_1" 3 "MaintainTargetSoc" 2 "EndAtTarget" 1 "InhibitCharging" 0 "Enable_Charging" ;
VAL_ 1144 BattTracClimtDis_B_Stat 1 "Enable" 0 "Disable" ;
VAL_ 1112 BattDcCnnct_D_Cmd 7 "NotUsed_3" 6 "NotUsed_2" 5 "NotUsed_1" 4 "WeldCheck" 3 "OkToDischarge" 2 "Closed" 1 "Precharge" 0 "Open" ;
VAL_ 1112 BattTrac2_E_Avail 4095 "Faulty" 4094 "NoDataExists" ;
VAL_ 1112 BattTracCnnct_D_Cmd 7 "NotUsed_3" 6 "NotUsed_2" 5 "NotUsed_1" 4 "WeldCheck" 3 "OkToDischarge" 2 "Closed" 1 "Precharge" 0 "Open" ;
VAL_ 1112 BattTracHvilOpen_B_Stat 1 "Open" 0 "Closed" ;
VAL_ 1112 BattTracCoolLvl_D_Rq 7 "Faulty" 6 "NotUsed" 5 "ChillerCoolingBattFirst" 4 "ChillerCoolingCabinFirst" 3 "ForcedCoolingRadiator" 2 "OpportunisticCoolingRad" 1 "CoolantFlowBypassLine" 0 "Off" ;
VAL_ 1112 BattTracTeSustn_B_Rq 1 "Active" 0 "Inactive" ;
VAL_ 1112 BattTracTeEvnt_B_Stat 1 "Active" 0 "Inactive" ;
VAL_ 1112 BattTracDcdcDis_B_Rq 1 "Yes" 0 "No" ;
VAL_ 1112 BattChrgTrgtEvnt_B_Stat 1 "Active" 0 "Inactive" ;
VAL_ 1112 BattTracChrgSustn_B_Rq 1 "Active" 0 "Inactive" ;
VAL_ 1112 HtrnClntPump_D_Stat 3 "Faulty" 2 "No_Data_Exists" 1 "On" 0 "Off" ;
VAL_ 1112 BattTracIsoDis_B_Stat 1 "Yes" 0 "No" ;
VAL_ 1112 BattTrac2_E_Max 4095 "Faulty" 4094 "NoDataExists" ;
VAL_ 1112 BattTracHeat_D_Rq 3 "Faulty" 2 "NotUsed" 1 "On" 0 "Off" ;
VAL_ 1112 BattTracDcFstSustn_B_Rq 1 "Active" 0 "Inactive" ;
VAL_ 1112 BattTracDiagClr_B_Rq 1 "On" 0 "Off" ;
VAL_ 1112 BattTracHazrd_D_Stat 3 "Disabled" 2 "HazardConfirmed" 1 "ExternalMonitoringRequired" 0 "NoHazardDetected" ;
VAL_ 1112 BattTracDelta_Te_Actl 255 "Faulty" 254 "NoDataExists" ;
VAL_ 1112 BattTracClntPmp_D_Stat 3 "Faulty" 2 "No_Data_Exists" 1 "On" 0 "Off" ;
VAL_ 139 AccButtnGpTogglePress2 1 "Pressed" 0 "Not_Pressed" ;
VAL_ 139 TjaButtnOnOffPress2 1 "Pressed" 0 "Not_Pressed" ;
VAL_ 139 ActvFrontSteMsgTxt_D_Rq 7 "Message7" 6 "Message6" 5 "Message5" 4 "Message4" 3 "Message3" 2 "Message2" 1 "Message1" 0 "NoMessage" ;
VAL_ 139 ActvFrontSteLck_D_Stat 3 "Test_passed" 2 "Test_failed" 1 "Test_cannot_run" 0 "Test_incomplete" ;
VAL_ 139 SelDrvMdeAdptSte_D_Stat 3 "Faulty" 2 "TemporarilyNotAvailable" 1 "Available" 0 "NotAvailable" ;
VAL_ 139 AslButtnOnOffPress2 1 "Button_Pressed" 0 "Button_Not_Pressed" ;
VAL_ 139 AslButtnOnOffCnclPres2 1 "Button_Pressed" 0 "Button_Not_Pressed" ;
VAL_ 139 CcButtnOnPress2 1 "Button_Pressed" 0 "Button_Not_Pressed" ;
VAL_ 139 CcButtnOnOffPress2 1 "Button_Pressed" 0 "Button_Not_Pressed" ;
VAL_ 139 CcButtnOnOffCnclPress2 1 "Button_Pressed" 0 "Button_Not_Pressed" ;
VAL_ 139 CcButtnOffPress2 1 "Button_Pressed" 0 "Button_Not_Pressed" ;
VAL_ 139 CcAsllButtnResPress2 1 "Button_Pressed" 0 "Button_Not_Pressed" ;
VAL_ 139 CcAslButtnSetPress2 1 "Button_Pressed" 0 "Button_Not_Pressed" ;
VAL_ 139 CcAslButtnSetIncPress2 1 "Button_Pressed" 0 "Button_Not_Pressed" ;
VAL_ 139 CcAslButtnSetDecPress2 1 "Button_Pressed" 0 "Button_Not_Pressed" ;
VAL_ 139 CcAslButtnResIncPress2 1 "Button_Pressed" 0 "Button_Not_Pressed" ;
VAL_ 139 CcAslButtnResDecPress2 1 "Button_Pressed" 0 "Button_Not_Pressed" ;
VAL_ 139 CcAslButtnOnPress2 1 "Button_Pressed" 0 "Button_Not_Pressed" ;
VAL_ 139 CcAslButtnOnOffCncl2 1 "Button_Pressed" 0 "Button_Not_Pressed" ;
VAL_ 139 CcAslButtnOffCnclPres2 1 "Button_Pressed" 0 "Button_Not_Pressed" ;
VAL_ 139 CcAslButtnIndxIncPres2 1 "Button_Pressed" 0 "Button_Not_Pressed" ;
VAL_ 139 CcAslButtnIndxDecPres2 1 "Button_Pressed" 0 "Button_Not_Pressed" ;
VAL_ 139 CcAslButtnDeny_B_Actl2 1 "Yes" 0 "No" ;
VAL_ 139 CcAslButtnCnclResPres2 1 "Button_Pressed" 0 "Button_Not_Pressed" ;
VAL_ 139 CcAslButtnCnclPress2 1 "Button_Pressed" 0 "Button_Not_Pressed" ;
VAL_ 139 AccButtnGapIncPress2 1 "Button_Pressed" 0 "Button_Not_Pressed" ;
VAL_ 139 AccButtnGapDecPress2 1 "Button_Pressed" 0 "Button_Not_Pressed" ;
VAL_ 139 AfsPw_B_Rq 1 "Yes" 0 "No" ;
VAL_ 1121 OffRdSwtch_D_RqMnu 3 "Faulty" 2 "NoRequest" 1 "On" 0 "Off" ;
VAL_ 1121 SelDrvMdeSwtchOk_D_Stat 3 "Faulty" 2 "Pressed" 1 "NotPressed" 0 "Null" ;
VAL_ 1121 AutoHoldSwtch_D_Stat2 3 "Faulty" 2 "NotUsed" 1 "Pressed" 0 "Not_Pressed" ;
VAL_ 1121 PrkAidSwtch_D_RqDrv3 1 "Pressed" 0 "Not_Pressed" ;
VAL_ 1121 ApaSwtch_D_RqDrv3 3 "NotUsed2" 2 "NotUsed1" 1 "Pressed" 0 "Not_Pressed" ;
VAL_ 1121 StopStrtDrvMde_B_RqBtn2 1 "Pressed" 0 "Not_Pressed" ;
VAL_ 1121 SelDrvMdeSwtch_D_Stat 3 "Faulty" 2 "SwitchState2" 1 "SwitchState1" 0 "NotPressed" ;
VAL_ 1121 SelDrvMdeCnt_D_Stat 4 "FourCounts" 3 "ThreeCounts" 2 "TwoCounts" 1 "OneCount" 0 "ZeroCounts" 7 "SevenOrMoreCounts" 6 "SixCounts" 5 "FiveCounts" ;
VAL_ 1189 PwStepMsgTxt_D_Rq 1 "DriveInhibited" 0 "NoMessage" 3 "NotUsed" 2 "Malfunction" ;
VAL_ 1189 Running_Board_Stat 3 "Unused" 2 "Manually_Deployed" 1 "All_Enabled" 0 "All_Disabled" ;
VAL_ 1189 PwStep_D_Stat 3 "PositionNotKnown" 2 "StepsNotStowed" 1 "StepsStowed" 0 "Off" ;
VAL_ 1120 StabBarCnncButtn_D_Stat 3 "Faulty" 2 "NotUsed" 1 "Pressed" 0 "Not_Pressed" ;
VAL_ 1120 DrvSlipCtlMde_B_Rq3 1 "Pressed" 0 "Not_Pressed" ;
VAL_ 1120 HybMdeSwtch_B_Rq 1 "Pressed" 0 "Not_Pressed" ;
VAL_ 1120 AwdLck_D_RqDrv 3 "Faulty" 2 "NoRequest" 1 "On" 0 "Off" ;
VAL_ 1120 TrailCtlSwtch_B_Stat3 1 "Pressed" 0 "Not_Pressed" ;
VAL_ 1120 RearDiffLck_D_RqDrv 3 "Faulty" 2 "NoRequest" 1 "On" 0 "Off" ;
VAL_ 1120 AwdMde_D_RqDrv 7 "Faulty" 6 "NotUsed2" 5 "NoRequest" 4 "Neutral" 3 "FourByFourLow" 2 "FourByFourHigh" 1 "FourByFourAuto" 0 "FourByTwo" ;
VAL_ 1120 HdcSwtchPos_B_Actl 1 "Pressed" 0 "Not_Pressed" ;
VAL_ 1120 FrontDiffLck_D_RqDrv 3 "Faulty" 2 "NoRequest" 1 "On" 0 "Off" ;
VAL_ 1050 RearDiffLck_D_RqDrv4 3 "Faulty" 2 "NoRequest" 1 "On" 0 "Off" ;
VAL_ 1050 CamraRearBttn_D_Stat 1 "Pressed" 0 "Not_Pressed" ;
VAL_ 1050 TrailCtlSwtch_B_Stat 1 "Pressed" 0 "Not_Pressed" ;
VAL_ 1050 AutoHoldSwtch_D_Stat 3 "Faulty" 2 "NotUsed" 1 "Pressed" 0 "Not_Pressed" ;
VAL_ 1050 EcoInhbt_B_RqHvac 1 "Yes" 0 "No" ;
VAL_ 1050 LpdbPtc3_B_Rq 1 "On" 0 "Off" ;
VAL_ 1050 LpdbPtc2_B_Rq 1 "On" 0 "Off" ;
VAL_ 1050 LpdbPtc1_B_Rq 1 "On" 0 "Off" ;
VAL_ 1050 LpdbHeatWiprPrk_B_Rq 1 "On" 0 "Off" ;
VAL_ 1050 LpdbDfrstRearOn_B_Rq 1 "On" 0 "Off" ;
VAL_ 1050 LpdbDfrstFrOn_B_Rq 1 "On" 0 "Off" ;
VAL_ 1050 LpdbDfrstFlOn_B_Rq 1 "On" 0 "Off" ;
VAL_ 1050 LpdbAuxBlwr_B_Rq 1 "On" 0 "Off" ;
VAL_ 1050 PrkAidSwtch_D_RqDrv 1 "Pressed" 0 "Not_Pressed" ;
VAL_ 1050 SteWhlHeat_D_Rq 15 "NotUsed6" 14 "NotUsed5" 13 "NotUsed4" 12 "NotUsed3" 11 "NotUsed2" 10 "NotUsed1" 9 "Reserved_3" 8 "Reserved_2" 7 "Reserved_1" 6 "Level_3_Heating" 5 "Level_3_Heating_LS" 4 "Level_2_Heating" 3 "Level_2_Heating_LS" 2 "Level_1_Heating" 1 "Level_1_Heating_LS" 0 "Off" ;
VAL_ 1050 MirrorHeatOn_B_Rq 1 "True" 0 "False" ;
VAL_ 1050 Remote_Start_QuietMode 1 "Quiet" 0 "Not_Quiet" ;
VAL_ 1050 DrvSlipCtlMde_B_Rq 1 "Pressed" 0 "Not_Pressed" ;
VAL_ 1050 Outside_Air_Temp_Stat 255 "Invalid" 254 "Unknown" ;
VAL_ 1050 CamraFrntBttn_D_Stat 1 "Pressed" 0 "Not_Pressed" ;
VAL_ 621 IgnPsswrdActv_B_Stat 1 "Active" 0 "Inactive" ;
VAL_ 621 FobTrgtZone_D_Rq 15 "NotUsed_9" 14 "NotUsed_8" 13 "NotUsed_7" 12 "NotUsed_6" 11 "NotUsed_5" 10 "NotUsed_4" 9 "NotUsed_3" 8 "NotUsed_2" 7 "NotUsed_1" 6 "Approach" 5 "RearInterior" 4 "RearExterior" 3 "Passenger" 2 "Driver" 1 "Interior" 0 "Null" ;
VAL_ 621 FobTrgtType_D_Rq 7 "NotUsed_4" 6 "NotUsed_3" 5 "NotUsed_2" 4 "NotUsed_1" 3 "Polling" 2 "Registry" 1 "Crypto" 0 "Null" ;
VAL_ 621 RmtCtlSelSlot_D_Rq 7 "NotUsed_3" 6 "NotUsed_2" 5 "NotUsed_1" 4 "Right" 3 "Left" 2 "Rear" 1 "Front" 0 "None" ;
VAL_ 621 RmtCtlSelPrkMde_D_Rq 3 "NotUsed" 2 "FreeDrive" 1 "ParkIn" 0 "None" ;
VAL_ 621 RmtCtlSelMoveDir_D_Rq 3 "NotUsed" 2 "Backward" 1 "Forward" 0 "None" ;
VAL_ 621 RmtCtlRjctAutoCfg_B_Rq 1 "Yes" 0 "No" ;
VAL_ 1124 GPS_Vdop 31 "Invalid" 30 "Unknown" ;
VAL_ 1124 GPS_Speed 255 "Invalid" 254 "Unknown" ;
VAL_ 1124 GPS_Sat_num_in_view 31 "Invalid" 30 "Unknown" ;
VAL_ 1124 GPS_MSL_altitude 4095 "Fault" 4094 "Unknown" ;
VAL_ 1124 GPS_Heading 65535 "Fault" 65534 "Unknown" ;
VAL_ 1124 GPS_Hdop 31 "Invalid" 30 "Unknown" ;
VAL_ 1124 GPS_dimension 2 "_3D" 1 "_2D" 0 "No_Fix" ;
VAL_ 1137 RngPerChrgLbl_L_Dsply 4095 "Faulty" 4094 "NoDataExists" ;
VAL_ 1137 RngPerChrgAvg_L_Dsply 4095 "Faulty" 4094 "NoDataExists" ;
VAL_ 1137 RngImpctTot_Pc_Dsply 1023 "Faulty" ;
VAL_ 1137 RngImpctExt_Pc_Dsply 1023 "Faulty" ;
VAL_ 1137 RngImpctDrv_Pc_Dsply 1023 "Faulty" ;
VAL_ 1137 RngImpctClim_Pc_Dsply 1023 "Faulty" ;
VAL_ 1255 BalrRight4Threat_D_Stat 1 "Yes" 0 "No" ;
VAL_ 1255 BalrRight4Fast_B_Stat 1 "Yes" 0 "No" ;
VAL_ 1255 BalrRight4Dsply_B_Stat 1 "Yes" 0 "No" ;
VAL_ 1254 BalrRight3Threat_D_Stat 1 "Yes" 0 "No" ;
VAL_ 1254 BalrRight3Fast_B_Stat 1 "Yes" 0 "No" ;
VAL_ 1254 BalrRight3Dsply_B_Stat 1 "Yes" 0 "No" ;
VAL_ 1253 BalrRight2Threat_D_Stat 1 "Yes" 0 "No" ;
VAL_ 1253 BalrRight2Fast_B_Stat 1 "Yes" 0 "No" ;
VAL_ 1253 BalrRight2Dsply_B_Stat 1 "Yes" 0 "No" ;
VAL_ 1252 BalrRight1Threat_D_Stat 1 "Yes" 0 "No" ;
VAL_ 1252 BalrRight1Fast_B_Stat 1 "Yes" 0 "No" ;
VAL_ 1252 BalrRight1Dsply_B_Stat 1 "Yes" 0 "No" ;
VAL_ 1251 BalrLeft4Threat_D_Stat 1 "Yes" 0 "No" ;
VAL_ 1251 BalrLeft4Fast_B_Stat 1 "Yes" 0 "No" ;
VAL_ 1251 BalrLeft4Dsply_B_Stat 1 "Yes" 0 "No" ;
VAL_ 1250 BalrLeft3Threat_D_Stat 1 "Yes" 0 "No" ;
VAL_ 1250 BalrLeft3Fast_B_Stat 1 "Yes" 0 "No" ;
VAL_ 1250 BalrLeft3Dsply_B_Stat 1 "Yes" 0 "No" ;
VAL_ 1249 BalrLeft2Threat_D_Stat 1 "Yes" 0 "No" ;
VAL_ 1249 BalrLeft2Fast_B_Stat 1 "Yes" 0 "No" ;
VAL_ 1249 BalrLeft2Dsply_B_Stat 1 "Yes" 0 "No" ;
VAL_ 1248 BalrLeft1Threat_D_Stat 1 "Yes" 0 "No" ;
VAL_ 1248 BalrLeft1Fast_B_Stat 1 "Yes" 0 "No" ;
VAL_ 1248 BalrLeft1Dsply_B_Stat 1 "Yes" 0 "No" ;
VAL_ 1113 TrlrTrgtAcquire_D_Stat 7 "Faulty" 6 "NotUsed_2" 5 "NotUsed_1" 4 "RVCforTBA_Activated" 3 "Processing" 2 "TargetNotAcquired" 1 "TargetAcquired" 0 "Null" ;
VAL_ 1113 TrlrAnOffstDir_D_Calc 3 "NotUSed" 2 "Right" 1 "Left_or_Center" 0 "Null" ;
VAL_ 1113 TrlrAnCalib_B_Complt 1 "Yes" 0 "No" ;
VAL_ 1113 TrlrRvrse_D_Stat 3 "Faulty" 2 "TrailerReverseGuidanceLite" 1 "On" 0 "Off" ;
VAL_ 1113 TrlrAid_D2_Stat 15 "Faulty" 14 "NotUsed_4" 13 "NotUsed_3" 12 "NotUsed_2" 11 "NotUsed_1" 10 "DirtyCamera" 9 "IncorrectLighting" 8 "TrackingLost" 7 "TrackingUnknownConfidence" 6 "TrackingHighConfidence" 5 "TrackingMediumConfidence" 4 "TrackingLowConfidence" 3 "TurnRequested" 2 "DriveStraighRequested" 1 "Initializing" 0 "NotTracking" ;
VAL_ 1113 TrlrAid_An3_Actl 2047 "Faulty" ;
VAL_ 1113 TrlrAid_AnRate2_Actl 1023 "Faulty" ;
VAL_ 1113 HitchToVehAxle_L_Calc 255 "Faulty" ;
VAL_ 1105 SpeedChngChime_D_Stat 3 "NotUsed" 2 "On" 1 "Off" 0 "Null" ;
VAL_ 1105 ClrExitAsstMsgTxt2_D_Rq 15 "NotUsed_7" 14 "NotUsed_6" 13 "NotUsed_5" 12 "NotUsed_4" 11 "NotUsed_3" 10 "NotUsed_2" 9 "NotUsed_1" 8 "FrontLeftRearRight" 7 "RearLeftFrontRight" 6 "FrontLeftFrontRight" 5 "RearLeftRearRight" 4 "FrontRight" 3 "FrontLeft" 2 "RearRight" 1 "RearLeft" 0 "NoMessage" ;
VAL_ 1105 ClrExitAsstActv_B_Rq 1 "Active" 0 "Inactive" ;
VAL_ 1105 TrlrRvrseMsgTxt_D2_Rq 31 "Message31" 30 "Message30" 29 "Message29" 28 "Message28" 27 "Message27" 26 "Message26" 25 "Message25" 24 "Message24" 23 "Message23" 22 "Message22" 21 "Message21" 20 "Message20" 19 "Message19" 18 "Message18" 17 "Message17" 16 "Message16" 15 "Message15" 14 "Message14" 13 "Message13" 12 "Message12" 11 "Message11" 10 "Message10" 9 "Message9" 8 "Message8" 7 "Message7" 6 "Message6" 5 "Message5" 4 "Message4" 3 "Message3" 2 "Message2" 1 "Message1" 0 "NoMessage" 63 "Message63" 47 "Message47" ;
VAL_ 1105 TrlrRvrseEnbl_D2_Stat 7 "NotUsed" 6 "TbaActiveExpertActive" 5 "TbaActiveExpertAvail" 4 "TbaOffTrgActive" 3 "TbaOffTrgSetup" 2 "TbaSetup" 1 "TbaActive" 0 "Inactive" ;
VAL_ 1105 RbaMsg_D_Rq 3 "Faulty" 2 "Unavailable" 1 "Off" 0 "Null" ;
VAL_ 1105 BrkDecel_B_RqRba 1 "Enable" 0 "Disable" ;
VAL_ 1105 BrkEnbl_B_RqRba 1 "Enable" 0 "Disable" ;
VAL_ 1105 Rba_D_Stat 3 "NotUsed" 2 "Disabled" 1 "On" 0 "Off" ;
VAL_ 1105 RbaAlrt_D_Dsply 3 "Both" 2 "Text" 1 "Graphic" 0 "Off" ;
VAL_ 1105 RbaMnu_D_Rq 3 "NotUsed" 2 "Active" 1 "Inactive" 0 "None" ;
VAL_ 1105 CamraFrntStat_D_Stat 3 "No_Data_Present" 2 "NotUsed" 1 "On" 0 "Off" ;
VAL_ 1105 TrlrHitchLamp_D_Rq2 1 "On" 0 "Off" ;
VAL_ 1105 CamraFrntOffRd_B_Stat 1 "Active" 0 "Inactive" ;
VAL_ 1105 TrlrAidSwtchLamp_B_Rq 1 "On" 0 "Off" ;
VAL_ 1105 TrlrAidEnbl_D_RqAdas 7 "NotUsed_4" 6 "NotUsed_3" 5 "NotUsed_2" 4 "NotUsed_1" 3 "Deactivate" 2 "NotAvailable" 1 "ActiveTba" 0 "Inactive" ;
VAL_ 1105 TrlrHitchMsgTxt_D_Rq 31 "Message31" 30 "Message30" 29 "Message29" 28 "Message28" 27 "Message27" 26 "Message26" 25 "Message25" 24 "Message24" 23 "Message23" 22 "Message22" 21 "Message21" 20 "Message20" 19 "Message19" 18 "Message18" 17 "Message17" 16 "Message16" 15 "Message15" 14 "Message14" 13 "Message13" 12 "Message12" 11 "Message11" 10 "Message10" 9 "Message9" 8 "Message8" 7 "Message7" 6 "Message6" 5 "Message5" 4 "Message4" 3 "Message3" 2 "Message2" 1 "Message1" 0 "NoMessage" 63 "Message63" 47 "Message47" ;
VAL_ 1105 TrlrHitchIcon_D_Rq 15 "Icon15" 14 "Icon14" 13 "Icon13" 12 "Icon12" 11 "Icon11" 10 "Icon10" 9 "Icon9" 8 "Icon8" 7 "Icon7" 6 "Icon6" 5 "Icon5" 4 "Icon4" 3 "Icon3" 2 "Icon2" 1 "Icon1" 0 "NoIcon" ;
VAL_ 1105 TrlrHitchChime_D_Rq 7 "NotUsed_1" 6 "NotUsed_1" 5 "WarningChime" 4 "NonCriticalAlertChime" 3 "StopNowChime" 2 "ManeuveringReadyChime" 1 "TrailerFoundChime" 0 "NoChime" ;
VAL_ 938 SidePrkSnsR2_D_Stat 15 "NotUsed" 14 "NotFullyScannedYet" 13 "NoObjectInSector" 12 "Zone12" 11 "Zone11" 10 "Zone10" 9 "Zone9" 8 "Zone8" 7 "Zone7" 6 "Zone6" 5 "Zone5" 4 "Zone4" 3 "Zone3" 2 "Zone2" 1 "Zone1" 0 "Off" ;
VAL_ 938 SidePrkSnsR1_D_Stat 15 "NotUsed" 14 "NotFullyScannedYet" 13 "NoObjectInSector" 12 "Zone12" 11 "Zone11" 10 "Zone10" 9 "Zone9" 8 "Zone8" 7 "Zone7" 6 "Zone6" 5 "Zone5" 4 "Zone4" 3 "Zone3" 2 "Zone2" 1 "Zone1" 0 "Off" ;
VAL_ 938 SidePrkSnsL2_D_Stat 15 "NotUsed" 14 "NotFullyScannedYet" 13 "NoObjectInSector" 12 "Zone12" 11 "Zone11" 10 "Zone10" 9 "Zone9" 8 "Zone8" 7 "Zone7" 6 "Zone6" 5 "Zone5" 4 "Zone4" 3 "Zone3" 2 "Zone2" 1 "Zone1" 0 "Off" ;
VAL_ 938 ApaMde_D_Stat 7 "NotUsed" 6 "RePA" 5 "ParkIn" 4 "POA" 3 "PPA" 2 "SAPP" 1 "Off" 0 "Null" ;
VAL_ 938 ApaActvSd_D_Actl 3 "Dirver_Side" 2 "Passenger_Side" 1 "No_Side" 0 "Null" ;
VAL_ 938 PrkAidSwtch_B_Stat 1 "Pressed" 0 "Not_Pressed" ;
VAL_ 938 ApaMde_D_Avail 15 "NotUsed7" 14 "NotUsed6" 13 "NotUsed5" 12 "NotUsed4" 11 "NotUsed3" 10 "NotUsed2" 9 "NotUsed1" 8 "PPA_POA" 7 "SAPP_POA" 6 "POA" 5 "PPA" 4 "SAPP" 3 "SAPP_PPA_POA" 2 "SAPP_PPA" 1 "None" 0 "Null" ;
VAL_ 938 PrkAidSnsFrCrnr_D_Stat 15 "Zone_15" 14 "Zone_14" 13 "Zone_13" 12 "Zone_12" 11 "Zone_11" 10 "Zone_10" 9 "Zone_9" 8 "Zone_8" 7 "Zone_7" 6 "Zone_6" 5 "Zone_5" 4 "Zone_4" 3 "Zone_3" 2 "Zone_2" 1 "Zone_1" 0 "Off" ;
VAL_ 938 PrkAidSnsFrCntr_D_Stat 15 "Zone_15" 14 "Zone_14" 13 "Zone_13" 12 "Zone_12" 11 "Zone_11" 10 "Zone_10" 9 "Zone_9" 8 "Zone_8" 7 "Zone_7" 6 "Zone_6" 5 "Zone_5" 4 "Zone_4" 3 "Zone_3" 2 "Zone_2" 1 "Zone_1" 0 "Off" ;
VAL_ 938 PrkAidSnsFlCrnr_D_Stat 15 "Zone_15" 14 "Zone_14" 13 "Zone_13" 12 "Zone_12" 11 "Zone_11" 10 "Zone_10" 9 "Zone_9" 8 "Zone_8" 7 "Zone_7" 6 "Zone_6" 5 "Zone_5" 4 "Zone_4" 3 "Zone_3" 2 "Zone_2" 1 "Zone_1" 0 "Off" ;
VAL_ 938 PrkAidSnsFlCntr_D_Stat 15 "Zone_15" 14 "Zone_14" 13 "Zone_13" 12 "Zone_12" 11 "Zone_11" 10 "Zone_10" 9 "Zone_9" 8 "Zone_8" 7 "Zone_7" 6 "Zone_6" 5 "Zone_5" 4 "Zone_4" 3 "Zone_3" 2 "Zone_2" 1 "Zone_1" 0 "Off" ;
VAL_ 938 PrkBrkEl_B_RqFap 1 "Yes" 0 "No" ;
VAL_ 938 RpaChime_D_Rq 15 "Zone15_Chime" 14 "Zone14_Chime" 13 "Zone13_Chime" 12 "Zone12_Chime" 11 "Zone11_Chime" 10 "Zone10_Chime" 9 "Zone9_Chime" 8 "Zone8_Chime" 7 "Zone7_Chime" 6 "Zone6_Chime" 5 "Zone5_Chime" 4 "Zone4_Chime" 3 "Zone3_Chime" 2 "Zone2_Chime" 1 "Zone1_Chime" 0 "No_Chime" ;
VAL_ 938 FpaChime_D_Rq 15 "Zone15_Chime" 14 "Zone14_Chime" 13 "Zone13_Chime" 12 "Zone12_Chime" 11 "Zone11_Chime" 10 "Zone10_Chime" 9 "Zone9_Chime" 8 "Zone8_Chime" 7 "Zone7_Chime" 6 "Zone6_Chime" 5 "Zone5_Chime" 4 "Zone4_Chime" 3 "Zone3_Chime" 2 "Zone2_Chime" 1 "Zone1_Chime" 0 "No_Chime" ;
VAL_ 938 PrkAidMsgTxt_D_Rq 15 "All_Sns_Blk" 14 "R_Sns_ON_F_Sns_Blk" 13 "R_Sns_Blk_F_Sns_ON" 12 "R_Sns_Inactive_Trlr_atch" 11 "Not_Avail_Trlr_attchd" 10 "Fail_Mode_no_Chime" 9 "Fail_Mode_with_Chime" 8 "R_Sns_Trlr_F_Sns_Blk" 7 "NotUsed3" 6 "Park_Sys_Alternate_Mode" 5 "R_Snsrs_On_F_Snsrs_On" 4 "NotUsed2" 3 "Reset_Message_Warn" 2 "R_Snsrs_Off_F_Snsrs_On" 1 "R_Snsrs_On_F_Snsrs_Off" 0 "All_Park_Sensors_Off" ;
VAL_ 938 SidePrkSnsL1_D_Stat 15 "NotUsed" 14 "NotFullyScannedYet" 13 "NoObjectInSector" 12 "Zone12" 11 "Zone11" 10 "Zone10" 9 "Zone9" 8 "Zone8" 7 "Zone7" 6 "Zone6" 5 "Zone5" 4 "Zone4" 3 "Zone3" 2 "Zone2" 1 "Zone1" 0 "Off" ;
VAL_ 938 PrkAidAudioMute_B_Rq 1 "Enable" 0 "Disable" ;
VAL_ 939 SidePrkSnsR4_D_Stat 15 "NotUsed" 14 "NotFullyScannedYet" 13 "NoObjectInSector" 12 "Zone12" 11 "Zone11" 10 "Zone10" 9 "Zone9" 8 "Zone8" 7 "Zone7" 6 "Zone6" 5 "Zone5" 4 "Zone4" 3 "Zone3" 2 "Zone2" 1 "Zone1" 0 "Off" ;
VAL_ 939 SidePrkSnsR3_D_Stat 15 "NotUsed" 14 "NotFullyScannedYet" 13 "NoObjectInSector" 12 "Zone12" 11 "Zone11" 10 "Zone10" 9 "Zone9" 8 "Zone8" 7 "Zone7" 6 "Zone6" 5 "Zone5" 4 "Zone4" 3 "Zone3" 2 "Zone2" 1 "Zone1" 0 "Off" ;
VAL_ 939 SidePrkSnsL4_D_Stat 15 "NotUsed" 14 "NotFullyScannedYet" 13 "NoObjectInSector" 12 "Zone12" 11 "Zone11" 10 "Zone10" 9 "Zone9" 8 "Zone8" 7 "Zone7" 6 "Zone6" 5 "Zone5" 4 "Zone4" 3 "Zone3" 2 "Zone2" 1 "Zone1" 0 "Off" ;
VAL_ 939 SidePrkSnsL3_D_Stat 15 "NotUsed" 14 "NotFullyScannedYet" 13 "NoObjectInSector" 12 "Zone12" 11 "Zone11" 10 "Zone10" 9 "Zone9" 8 "Zone8" 7 "Zone7" 6 "Zone6" 5 "Zone5" 4 "Zone4" 3 "Zone3" 2 "Zone2" 1 "Zone1" 0 "Off" ;
VAL_ 939 PrkAidChime_D_Stat 3 "Fault" 2 "No_Data_Exists" 1 "On" 0 "Off" ;
VAL_ 939 PrkAidSnsRlCntr_D_Stat 15 "Zone_15" 14 "Zone_14" 13 "Zone_13" 12 "Zone_12" 11 "Zone_11" 10 "Zone_10" 9 "Zone_9" 8 "Zone_8" 7 "Zone_7" 6 "Zone_6" 5 "Zone_5" 4 "Zone_4" 3 "Zone_3" 2 "Zone_2" 1 "Zone_1" 0 "Off" ;
VAL_ 939 PrkAidSnsRrCrnr_D_Stat 15 "Zone_15" 14 "Zone_14" 13 "Zone_13" 12 "Zone_12" 11 "Zone_11" 10 "Zone_10" 9 "Zone_9" 8 "Zone_8" 7 "Zone_7" 6 "Zone_6" 5 "Zone_5" 4 "Zone_4" 3 "Zone_3" 2 "Zone_2" 1 "Zone_1" 0 "Off" ;
VAL_ 939 PrkAidSnsRrCntr_D_Stat 15 "Zone_15" 14 "Zone_14" 13 "Zone_13" 12 "Zone_12" 11 "Zone_11" 10 "Zone_10" 9 "Zone_9" 8 "Zone_8" 7 "Zone_7" 6 "Zone_6" 5 "Zone_5" 4 "Zone_4" 3 "Zone_3" 2 "Zone_2" 1 "Zone_1" 0 "Off" ;
VAL_ 939 PrkAidSnsRlCrnr_D_Stat 15 "Zone_15" 14 "Zone_14" 13 "Zone_13" 12 "Zone_12" 11 "Zone_11" 10 "Zone_10" 9 "Zone_9" 8 "Zone_8" 7 "Zone_7" 6 "Zone_6" 5 "Zone_5" 4 "Zone_4" 3 "Zone_3" 2 "Zone_2" 1 "Zone_1" 0 "Off" ;
VAL_ 939 PrkAidRear_D_Stat 3 "Faulted" 2 "Unused" 1 "Enabled" 0 "Disabled" ;
VAL_ 939 PrkAidFront_D_Stat 3 "Faulted" 2 "Unused" 1 "Enabled" 0 "Disabled" ;
VAL_ 939 PrkAid_D_Falt 7 "NotUsed2" 6 "NotUsed1" 5 "Failure_Front_PSM_Sensors" 4 "No_Data_Exists" 3 "Failure_Rear_Sensors" 2 "Speaker_Fault" 1 "ECU_Fault" 0 "No_Fault" ;
VAL_ 939 ApaLongCtrlEnbl_D_Rq 1 "Enable" 0 "Disable" ;
VAL_ 939 PrkAidLamp_D_Rq 3 "Not_Used" 2 "Flash" 1 "On" 0 "Off" ;
VAL_ 939 ApaBrk_D_Rq 3 "NotUsed" 2 "LowDecel" 1 "HighDecel" 0 "NoRequest" ;
VAL_ 937 TrnRng_D_RqFap 7 "NotUsed3" 6 "NotUsed2" 5 "NotUsed1" 4 "Backwards" 3 "Forwards" 2 "NoMotion" 1 "Immobilize" 0 "NoRequest" ;
VAL_ 937 FapLcDistToObj_L_Actl 255 "Faulty" 254 "NoDataExists" ;
